VERSION "created by canmatrix"

NS_ :

BS_:

BU_: RadarFrontCenter DASy MPC3

BO_ 210 VFC_Object17A: 64 MPC3
 SG_ VFC_Obj17A_CRC : 0|16@1+ (1,0) [0|65535] ""  RadarFrontCenter,DASy
 SG_ VFC_Obj17A_DyStdDev : 104|10@1+ (0.02,0) [0|20] "m"  RadarFrontCenter,DASy
 SG_ VFC_Obj17A_DxStdDev : 118|10@1+ (0.05,0) [0|50] "m"  RadarFrontCenter,DASy
 SG_ VFC_Obj17A_VxStdDev : 128|10@1+ (0.1,0) [0|100] "m/s"  RadarFrontCenter,DASy
 SG_ VFC_Obj17A_ExistProb : 138|6@1+ (2,0) [0|100] "%"  RadarFrontCenter,DASy
 SG_ VFC_Obj17A_VyStdDev : 144|9@1+ (0.1,0) [0|50] "m/s"  RadarFrontCenter,DASy
 SG_ VFC_Obj17A_TypeProb : 154|6@1+ (2,0) [0|100] "%"  RadarFrontCenter,DASy
 SG_ VFC_Obj17A_AxStdDev : 160|8@1+ (0.1,0) [0|25] "m/s^2"  RadarFrontCenter,DASy
 SG_ VFC_Obj17A_AyStdDev : 168|8@1+ (0.1,0) [0|25] "m/s^2"  RadarFrontCenter,DASy
 SG_ VFC_Obj17A_AliveCtr : 16|8@1+ (1,0) [0|255] ""  RadarFrontCenter,DASy
 SG_ VFC_Obj17A_PhiLeft : 176|13@1+ (0.00025,-1) [-1|1] ""  RadarFrontCenter,DASy
 SG_ VFC_Obj17A_ClassifiedView : 189|3@1+ (1,0) [0|7] ""  RadarFrontCenter,DASy
 SG_ VFC_Obj17A_Length : 192|9@1+ (0.05,0) [0|25.5] "m"  RadarFrontCenter,DASy
 SG_ VFC_Obj17A_WidthStdDev : 201|7@1+ (0.01,0) [0|1] "m"  RadarFrontCenter,DASy
 SG_ VFC_Obj17A_Height : 208|9@1+ (0.01,0) [0|5.11] "m"  RadarFrontCenter,DASy
 SG_ VFC_Obj17A_HeightStdDev : 217|7@1+ (0.01,0) [0|1] "m"  RadarFrontCenter,DASy
 SG_ VFC_Obj17A_PhiLeftStdDev : 224|8@1+ (0.0002,0) [0|0.05] ""  RadarFrontCenter,DASy
 SG_ VFC_Obj17A_HeadingStdDev : 232|6@1+ (0.01,0) [0|0.5] "rad"  RadarFrontCenter,DASy
 SG_ VFC_Obj17A_Measured : 238|2@1+ (1,0) [0|3] ""  RadarFrontCenter,DASy
 SG_ VFC_Obj17A_Heading : 240|9@1+ (0.01,-1.57) [-1.57|1.57] "rad"  RadarFrontCenter,DASy
 SG_ VFC_Obj17A_LengthStdDev : 249|7@1+ (0.05,0) [0|5] "m"  RadarFrontCenter,DASy
 SG_ VFC_Obj17A_BlockCtr : 24|4@1+ (1,0) [0|15] ""  RadarFrontCenter,DASy
 SG_ VFC_Obj17A_PhiMid : 256|13@1+ (0.00025,-1) [-1|1] ""  RadarFrontCenter,DASy
 SG_ VFC_Obj17A_Width : 269|11@1+ (0.01,0) [0|12] "m"  RadarFrontCenter,DASy
 SG_ VFC_Obj17A_PhiMidStdDev : 280|8@1+ (0.0002,0) [0|0.05] ""  RadarFrontCenter,DASy
 SG_ VFC_Obj17A_PhiRight : 288|13@1+ (0.00025,-1) [-1|1] ""  RadarFrontCenter,DASy
 SG_ VFC_Obj17A_VisibleView : 301|3@1+ (1,0) [0|4] ""  RadarFrontCenter,DASy
 SG_ VFC_Obj17A_PhiRightStdDev : 304|8@1+ (0.0002,0) [0|0.05] ""  RadarFrontCenter,DASy
 SG_ VFC_Obj17A_PhiLeftVel : 312|13@1+ (0.001,-4) [-4|4] "1/s"  RadarFrontCenter,DASy
 SG_ VFC_Obj17A_PhiRightVel : 328|13@1+ (0.001,-4) [-4|4] "1/s"  RadarFrontCenter,DASy
 SG_ VFC_Obj17A_ProtOrderIndex : 32|6@1+ (1,0) [0|63] ""  RadarFrontCenter,DASy
 SG_ VFC_Obj17A_PhiRightVelStdDev : 344|8@1+ (0.001,0) [0|0.25] "1/s"  RadarFrontCenter,DASy
 SG_ VFC_Obj17A_PhiLeftVelStdDev : 352|8@1+ (0.001,0) [0|0.25] "1/s"  RadarFrontCenter,DASy
 SG_ VFC_Obj17A_PhiTop : 360|12@1+ (0.00025,-0.4) [-0.4|0.4] ""  RadarFrontCenter,DASy
 SG_ VFC_Obj17A_PhiBottom : 372|12@1+ (0.00025,-0.4) [-0.4|0.4] ""  RadarFrontCenter,DASy
 SG_ VFC_Obj17A_PhiTopStdDev : 384|8@1+ (0.0002,0) [0|0.05] ""  RadarFrontCenter,DASy
 SG_ VFC_Obj17A_HeadOrientation : 392|4@1+ (1,0) [0|10] ""  RadarFrontCenter,DASy
 SG_ VFC_Obj17A_Type : 396|4@1+ (1,0) [0|15] ""  RadarFrontCenter,DASy
 SG_ VFC_Obj17A_Ax : 39|9@1+ (0.1,-16) [-16|16] "m/s^2"  RadarFrontCenter,DASy
 SG_ VFC_Obj17A_PhiBottomStdDev : 400|8@1+ (0.0002,0) [0|0.05] ""  RadarFrontCenter,DASy
 SG_ VFC_Obj17A_NormVx : 408|16@1+ (0.001,-40) [-40|25] "1/s"  RadarFrontCenter,DASy
 SG_ VFC_Obj17A_NormAx : 424|13@1+ (0.002,-10) [-10|6] "1/s^2"  RadarFrontCenter,DASy
 SG_ VFC_Obj17A_NormAxStdDev : 440|10@1+ (0.0025,0) [0|2.5] "1/s^2"  RadarFrontCenter,DASy
 SG_ VFC_Obj17A_ProbMovingLat : 450|6@1+ (2,0) [0|100] "%"  RadarFrontCenter,DASy
 SG_ VFC_Obj17A_ID : 456|8@1+ (1,0) [0|254] ""  RadarFrontCenter,DASy
 SG_ VFC_Obj17A_NormVxStdDev : 464|10@1+ (0.001,0) [0|1] "1/s"  RadarFrontCenter,DASy
 SG_ VFC_Obj17A_ProbMovingLong : 474|6@1+ (2,0) [0|100] "%"  RadarFrontCenter,DASy
 SG_ VFC_Obj17A_Vx : 48|12@1+ (0.1,-154) [-154|50] "m/s"  RadarFrontCenter,DASy
 SG_ VFC_Obj17A_Dx : 60|12@1+ (0.05,0) [0|204.7] "m"  RadarFrontCenter,DASy
 SG_ VFC_Obj17A_Dy : 72|14@1+ (0.01,-80) [-80|80] "m"  RadarFrontCenter,DASy
 SG_ VFC_Obj17A_Vy : 86|10@1+ (0.1,-50) [-50|50] "m/s"  RadarFrontCenter,DASy
 SG_ VFC_Obj17A_Ay : 96|8@1+ (0.1,-12) [-12|12] "m/s^2"  RadarFrontCenter,DASy

BO_ 211 VFC_Object17B: 16 MPC3
 SG_ VFC_Obj17B_CRC : 0|16@1+ (1,0) [0|65535] ""  RadarFrontCenter,DASy
 SG_ VFC_Obj17B_TTIPC : 104|11@1+ (0.008,-8) [-8|8] ""  RadarFrontCenter,DASy
 SG_ VFC_Obj17B_TTIPC_StdDev : 120|7@1+ (0.0625,0) [0|7.875] ""  RadarFrontCenter,DASy
 SG_ VFC_Obj17B_AliveCtr : 16|8@1+ (1,0) [0|255] ""  RadarFrontCenter,DASy
 SG_ VFC_Obj17B_BlockCtr : 24|4@1+ (1,0) [0|15] ""  RadarFrontCenter,DASy
 SG_ VFC_Obj17B_ScaleChange : 32|14@1+ (0.0001,0.5) [0.5|2.1] ""  RadarFrontCenter,DASy
 SG_ VFC_Obj17B_ScaleChngStdDev : 48|10@1+ (0.0001,0) [0|0.1] ""  RadarFrontCenter,DASy
 SG_ VFC_Obj17B_LineEdgeRightEgo : 58|1@1+ (1,0) [0|1] ""  RadarFrontCenter,DASy
 SG_ VFC_Obj17B_LineEdgeLeftEgo : 59|1@1+ (1,0) [0|1] ""  RadarFrontCenter,DASy
 SG_ VFC_Obj17B_CompletelyInImg : 60|1@1+ (1,0) [0|1] ""  RadarFrontCenter,DASy
 SG_ VFC_Obj17B_DirIndicator : 61|3@1+ (1,0) [0|7] ""  RadarFrontCenter,DASy
 SG_ VFC_Obj17B_LineEdgeAngle : 64|13@1+ (0.00025,-1) [-1|1] "rad"  RadarFrontCenter,DASy
 SG_ VFC_Obj17B_BrakeLight : 77|3@1+ (1,0) [0|7] ""  RadarFrontCenter,DASy
 SG_ VFC_Obj17B_MeasSource : 80|5@1+ (1,0) [0|31] ""  RadarFrontCenter,DASy
 SG_ VFC_Obj17B_AngLongitude : 88|10@1+ (0.005,-2.5) [-2.5|2.5] "rad/s"  RadarFrontCenter,DASy
 SG_ VFC_Obj17B_Reliab : 98|6@1+ (1,0) [0|63] ""  RadarFrontCenter,DASy

BO_ 212 VFC_Object18A: 64 MPC3
 SG_ VFC_Obj18A_CRC : 0|16@1+ (1,0) [0|65535] ""  RadarFrontCenter,DASy
 SG_ VFC_Obj18A_DyStdDev : 104|10@1+ (0.02,0) [0|20] "m"  RadarFrontCenter,DASy
 SG_ VFC_Obj18A_DxStdDev : 118|10@1+ (0.05,0) [0|50] "m"  RadarFrontCenter,DASy
 SG_ VFC_Obj18A_VxStdDev : 128|10@1+ (0.1,0) [0|100] "m/s"  RadarFrontCenter,DASy
 SG_ VFC_Obj18A_ExistProb : 138|6@1+ (2,0) [0|100] "%"  RadarFrontCenter,DASy
 SG_ VFC_Obj18A_VyStdDev : 144|9@1+ (0.1,0) [0|50] "m/s"  RadarFrontCenter,DASy
 SG_ VFC_Obj18A_TypeProb : 154|6@1+ (2,0) [0|100] "%"  RadarFrontCenter,DASy
 SG_ VFC_Obj18A_AxStdDev : 160|8@1+ (0.1,0) [0|25] "m/s^2"  RadarFrontCenter,DASy
 SG_ VFC_Obj18A_AyStdDev : 168|8@1+ (0.1,0) [0|25] "m/s^2"  RadarFrontCenter,DASy
 SG_ VFC_Obj18A_AliveCtr : 16|8@1+ (1,0) [0|255] ""  RadarFrontCenter,DASy
 SG_ VFC_Obj18A_PhiLeft : 176|13@1+ (0.00025,-1) [-1|1] ""  RadarFrontCenter,DASy
 SG_ VFC_Obj18A_ClassifiedView : 189|3@1+ (1,0) [0|7] ""  RadarFrontCenter,DASy
 SG_ VFC_Obj18A_Length : 192|9@1+ (0.05,0) [0|25.5] "m"  RadarFrontCenter,DASy
 SG_ VFC_Obj18A_WidthStdDev : 201|7@1+ (0.01,0) [0|1] "m"  RadarFrontCenter,DASy
 SG_ VFC_Obj18A_Height : 208|9@1+ (0.01,0) [0|5.11] "m"  RadarFrontCenter,DASy
 SG_ VFC_Obj18A_HeightStdDev : 217|7@1+ (0.01,0) [0|1] "m"  RadarFrontCenter,DASy
 SG_ VFC_Obj18A_PhiLeftStdDev : 224|8@1+ (0.0002,0) [0|0.05] ""  RadarFrontCenter,DASy
 SG_ VFC_Obj18A_HeadingStdDev : 232|6@1+ (0.01,0) [0|0.5] "rad"  RadarFrontCenter,DASy
 SG_ VFC_Obj18A_Measured : 238|2@1+ (1,0) [0|3] ""  RadarFrontCenter,DASy
 SG_ VFC_Obj18A_Heading : 240|9@1+ (0.01,-1.57) [-1.57|1.57] "rad"  RadarFrontCenter,DASy
 SG_ VFC_Obj18A_LengthStdDev : 249|7@1+ (0.05,0) [0|5] "m"  RadarFrontCenter,DASy
 SG_ VFC_Obj18A_BlockCtr : 24|4@1+ (1,0) [0|15] ""  RadarFrontCenter,DASy
 SG_ VFC_Obj18A_PhiMid : 256|13@1+ (0.00025,-1) [-1|1] ""  RadarFrontCenter,DASy
 SG_ VFC_Obj18A_Width : 269|11@1+ (0.01,0) [0|12] "m"  RadarFrontCenter,DASy
 SG_ VFC_Obj18A_PhiMidStdDev : 280|8@1+ (0.0002,0) [0|0.05] ""  RadarFrontCenter,DASy
 SG_ VFC_Obj18A_PhiRight : 288|13@1+ (0.00025,-1) [-1|1] ""  RadarFrontCenter,DASy
 SG_ VFC_Obj18A_VisibleView : 301|3@1+ (1,0) [0|4] ""  RadarFrontCenter,DASy
 SG_ VFC_Obj18A_PhiRightStdDev : 304|8@1+ (0.0002,0) [0|0.05] ""  RadarFrontCenter,DASy
 SG_ VFC_Obj18A_PhiLeftVel : 312|13@1+ (0.001,-4) [-4|4] "1/s"  RadarFrontCenter,DASy
 SG_ VFC_Obj18A_PhiRightVel : 328|13@1+ (0.001,-4) [-4|4] "1/s"  RadarFrontCenter,DASy
 SG_ VFC_Obj18A_ProtOrderIndex : 32|6@1+ (1,0) [0|63] ""  RadarFrontCenter,DASy
 SG_ VFC_Obj18A_PhiRightVelStdDev : 344|8@1+ (0.001,0) [0|0.25] "1/s"  RadarFrontCenter,DASy
 SG_ VFC_Obj18A_PhiLeftVelStdDev : 352|8@1+ (0.001,0) [0|0.25] "1/s"  RadarFrontCenter,DASy
 SG_ VFC_Obj18A_PhiTop : 360|12@1+ (0.00025,-0.4) [-0.4|0.4] ""  RadarFrontCenter,DASy
 SG_ VFC_Obj18A_PhiBottom : 372|12@1+ (0.00025,-0.4) [-0.4|0.4] ""  RadarFrontCenter,DASy
 SG_ VFC_Obj18A_PhiTopStdDev : 384|8@1+ (0.0002,0) [0|0.05] ""  RadarFrontCenter,DASy
 SG_ VFC_Obj18A_HeadOrientation : 392|4@1+ (1,0) [0|10] ""  RadarFrontCenter,DASy
 SG_ VFC_Obj18A_Type : 396|4@1+ (1,0) [0|15] ""  RadarFrontCenter,DASy
 SG_ VFC_Obj18A_Ax : 39|9@1+ (0.1,-16) [-16|16] "m/s^2"  RadarFrontCenter,DASy
 SG_ VFC_Obj18A_PhiBottomStdDev : 400|8@1+ (0.0002,0) [0|0.05] ""  RadarFrontCenter,DASy
 SG_ VFC_Obj18A_NormVx : 408|16@1+ (0.001,-40) [-40|25] "1/s"  RadarFrontCenter,DASy
 SG_ VFC_Obj18A_NormAx : 424|13@1+ (0.002,-10) [-10|6] "1/s^2"  RadarFrontCenter,DASy
 SG_ VFC_Obj18A_NormAxStdDev : 440|10@1+ (0.0025,0) [0|2.5] "1/s^2"  RadarFrontCenter,DASy
 SG_ VFC_Obj18A_ProbMovingLat : 450|6@1+ (2,0) [0|100] "%"  RadarFrontCenter,DASy
 SG_ VFC_Obj18A_ID : 456|8@1+ (1,0) [0|254] ""  RadarFrontCenter,DASy
 SG_ VFC_Obj18A_NormVxStdDev : 464|10@1+ (0.001,0) [0|1] "1/s"  RadarFrontCenter,DASy
 SG_ VFC_Obj18A_ProbMovingLong : 474|6@1+ (2,0) [0|100] "%"  RadarFrontCenter,DASy
 SG_ VFC_Obj18A_Vx : 48|12@1+ (0.1,-154) [-154|50] "m/s"  RadarFrontCenter,DASy
 SG_ VFC_Obj18A_Dx : 60|12@1+ (0.05,0) [0|204.7] "m"  RadarFrontCenter,DASy
 SG_ VFC_Obj18A_Dy : 72|14@1+ (0.01,-80) [-80|80] "m"  RadarFrontCenter,DASy
 SG_ VFC_Obj18A_Vy : 86|10@1+ (0.1,-50) [-50|50] "m/s"  RadarFrontCenter,DASy
 SG_ VFC_Obj18A_Ay : 96|8@1+ (0.1,-12) [-12|12] "m/s^2"  RadarFrontCenter,DASy

BO_ 213 VFC_Object18B: 16 MPC3
 SG_ VFC_Obj18B_CRC : 0|16@1+ (1,0) [0|65535] ""  RadarFrontCenter,DASy
 SG_ VFC_Obj18B_TTIPC : 104|11@1+ (0.008,-8) [-8|8] ""  RadarFrontCenter,DASy
 SG_ VFC_Obj18B_TTIPC_StdDev : 120|7@1+ (0.0625,0) [0|7.875] ""  RadarFrontCenter,DASy
 SG_ VFC_Obj18B_AliveCtr : 16|8@1+ (1,0) [0|255] ""  RadarFrontCenter,DASy
 SG_ VFC_Obj18B_BlockCtr : 24|4@1+ (1,0) [0|15] ""  RadarFrontCenter,DASy
 SG_ VFC_Obj18B_ScaleChange : 32|14@1+ (0.0001,0.5) [0.5|2.1] ""  RadarFrontCenter,DASy
 SG_ VFC_Obj18B_ScaleChngStdDev : 48|10@1+ (0.0001,0) [0|0.1] ""  RadarFrontCenter,DASy
 SG_ VFC_Obj18B_LineEdgeRightEgo : 58|1@1+ (1,0) [0|1] ""  RadarFrontCenter,DASy
 SG_ VFC_Obj18B_LineEdgeLeftEgo : 59|1@1+ (1,0) [0|1] ""  RadarFrontCenter,DASy
 SG_ VFC_Obj18B_CompletelyInImg : 60|1@1+ (1,0) [0|1] ""  RadarFrontCenter,DASy
 SG_ VFC_Obj18B_DirIndicator : 61|3@1+ (1,0) [0|7] ""  RadarFrontCenter,DASy
 SG_ VFC_Obj18B_LineEdgeAngle : 64|13@1+ (0.00025,-1) [-1|1] "rad"  RadarFrontCenter,DASy
 SG_ VFC_Obj18B_BrakeLight : 77|3@1+ (1,0) [0|7] ""  RadarFrontCenter,DASy
 SG_ VFC_Obj18B_MeasSource : 80|5@1+ (1,0) [0|31] ""  RadarFrontCenter,DASy
 SG_ VFC_Obj18B_AngLongitude : 88|10@1+ (0.005,-2.5) [-2.5|2.5] "rad/s"  RadarFrontCenter,DASy
 SG_ VFC_Obj18B_Reliab : 98|6@1+ (1,0) [0|63] ""  RadarFrontCenter,DASy

BO_ 214 VFC_Object19A: 64 MPC3
 SG_ VFC_Obj19A_CRC : 0|16@1+ (1,0) [0|65535] ""  RadarFrontCenter,DASy
 SG_ VFC_Obj19A_DyStdDev : 104|10@1+ (0.02,0) [0|20] "m"  RadarFrontCenter,DASy
 SG_ VFC_Obj19A_DxStdDev : 118|10@1+ (0.05,0) [0|50] "m"  RadarFrontCenter,DASy
 SG_ VFC_Obj19A_VxStdDev : 128|10@1+ (0.1,0) [0|100] "m/s"  RadarFrontCenter,DASy
 SG_ VFC_Obj19A_ExistProb : 138|6@1+ (2,0) [0|100] "%"  RadarFrontCenter,DASy
 SG_ VFC_Obj19A_VyStdDev : 144|9@1+ (0.1,0) [0|50] "m/s"  RadarFrontCenter,DASy
 SG_ VFC_Obj19A_TypeProb : 154|6@1+ (2,0) [0|100] "%"  RadarFrontCenter,DASy
 SG_ VFC_Obj19A_AxStdDev : 160|8@1+ (0.1,0) [0|25] "m/s^2"  RadarFrontCenter,DASy
 SG_ VFC_Obj19A_AyStdDev : 168|8@1+ (0.1,0) [0|25] "m/s^2"  RadarFrontCenter,DASy
 SG_ VFC_Obj19A_AliveCtr : 16|8@1+ (1,0) [0|255] ""  RadarFrontCenter,DASy
 SG_ VFC_Obj19A_PhiLeft : 176|13@1+ (0.00025,-1) [-1|1] ""  RadarFrontCenter,DASy
 SG_ VFC_Obj19A_ClassifiedView : 189|3@1+ (1,0) [0|7] ""  RadarFrontCenter,DASy
 SG_ VFC_Obj19A_Length : 192|9@1+ (0.05,0) [0|25.5] "m"  RadarFrontCenter,DASy
 SG_ VFC_Obj19A_WidthStdDev : 201|7@1+ (0.01,0) [0|1] "m"  RadarFrontCenter,DASy
 SG_ VFC_Obj19A_Height : 208|9@1+ (0.01,0) [0|5.11] "m"  RadarFrontCenter,DASy
 SG_ VFC_Obj19A_HeightStdDev : 217|7@1+ (0.01,0) [0|1] "m"  RadarFrontCenter,DASy
 SG_ VFC_Obj19A_PhiLeftStdDev : 224|8@1+ (0.0002,0) [0|0.05] ""  RadarFrontCenter,DASy
 SG_ VFC_Obj19A_HeadingStdDev : 232|6@1+ (0.01,0) [0|0.5] "rad"  RadarFrontCenter,DASy
 SG_ VFC_Obj19A_Measured : 238|2@1+ (1,0) [0|3] ""  RadarFrontCenter,DASy
 SG_ VFC_Obj19A_Heading : 240|9@1+ (0.01,-1.57) [-1.57|1.57] "rad"  RadarFrontCenter,DASy
 SG_ VFC_Obj19A_LengthStdDev : 249|7@1+ (0.05,0) [0|5] "m"  RadarFrontCenter,DASy
 SG_ VFC_Obj19A_BlockCtr : 24|4@1+ (1,0) [0|15] ""  RadarFrontCenter,DASy
 SG_ VFC_Obj19A_PhiMid : 256|13@1+ (0.00025,-1) [-1|1] ""  RadarFrontCenter,DASy
 SG_ VFC_Obj19A_Width : 269|11@1+ (0.01,0) [0|12] "m"  RadarFrontCenter,DASy
 SG_ VFC_Obj19A_PhiMidStdDev : 280|8@1+ (0.0002,0) [0|0.05] ""  RadarFrontCenter,DASy
 SG_ VFC_Obj19A_PhiRight : 288|13@1+ (0.00025,-1) [-1|1] ""  RadarFrontCenter,DASy
 SG_ VFC_Obj19A_VisibleView : 301|3@1+ (1,0) [0|4] ""  RadarFrontCenter,DASy
 SG_ VFC_Obj19A_PhiRightStdDev : 304|8@1+ (0.0002,0) [0|0.05] ""  RadarFrontCenter,DASy
 SG_ VFC_Obj19A_PhiLeftVel : 312|13@1+ (0.001,-4) [-4|4] "1/s"  RadarFrontCenter,DASy
 SG_ VFC_Obj19A_PhiRightVel : 328|13@1+ (0.001,-4) [-4|4] "1/s"  RadarFrontCenter,DASy
 SG_ VFC_Obj19A_ProtOrderIndex : 32|6@1+ (1,0) [0|63] ""  RadarFrontCenter,DASy
 SG_ VFC_Obj19A_PhiRightVelStdDev : 344|8@1+ (0.001,0) [0|0.25] "1/s"  RadarFrontCenter,DASy
 SG_ VFC_Obj19A_PhiLeftVelStdDev : 352|8@1+ (0.001,0) [0|0.25] "1/s"  RadarFrontCenter,DASy
 SG_ VFC_Obj19A_PhiTop : 360|12@1+ (0.00025,-0.4) [-0.4|0.4] ""  RadarFrontCenter,DASy
 SG_ VFC_Obj19A_PhiBottom : 372|12@1+ (0.00025,-0.4) [-0.4|0.4] ""  RadarFrontCenter,DASy
 SG_ VFC_Obj19A_PhiTopStdDev : 384|8@1+ (0.0002,0) [0|0.05] ""  RadarFrontCenter,DASy
 SG_ VFC_Obj19A_HeadOrientation : 392|4@1+ (1,0) [0|10] ""  RadarFrontCenter,DASy
 SG_ VFC_Obj19A_Type : 396|4@1+ (1,0) [0|15] ""  RadarFrontCenter,DASy
 SG_ VFC_Obj19A_Ax : 39|9@1+ (0.1,-16) [-16|16] "m/s^2"  RadarFrontCenter,DASy
 SG_ VFC_Obj19A_PhiBottomStdDev : 400|8@1+ (0.0002,0) [0|0.05] ""  RadarFrontCenter,DASy
 SG_ VFC_Obj19A_NormVx : 408|16@1+ (0.001,-40) [-40|25] "1/s"  RadarFrontCenter,DASy
 SG_ VFC_Obj19A_NormAx : 424|13@1+ (0.002,-10) [-10|6] "1/s^2"  RadarFrontCenter,DASy
 SG_ VFC_Obj19A_NormAxStdDev : 440|10@1+ (0.0025,0) [0|2.5] "1/s^2"  RadarFrontCenter,DASy
 SG_ VFC_Obj19A_ProbMovingLat : 450|6@1+ (2,0) [0|100] "%"  RadarFrontCenter,DASy
 SG_ VFC_Obj19A_ID : 456|8@1+ (1,0) [0|254] ""  RadarFrontCenter,DASy
 SG_ VFC_Obj19A_NormVxStdDev : 464|10@1+ (0.001,0) [0|1] "1/s"  RadarFrontCenter,DASy
 SG_ VFC_Obj19A_ProbMovingLong : 474|6@1+ (2,0) [0|100] "%"  RadarFrontCenter,DASy
 SG_ VFC_Obj19A_Vx : 48|12@1+ (0.1,-154) [-154|50] "m/s"  RadarFrontCenter,DASy
 SG_ VFC_Obj19A_Dx : 60|12@1+ (0.05,0) [0|204.7] "m"  RadarFrontCenter,DASy
 SG_ VFC_Obj19A_Dy : 72|14@1+ (0.01,-80) [-80|80] "m"  RadarFrontCenter,DASy
 SG_ VFC_Obj19A_Vy : 86|10@1+ (0.1,-50) [-50|50] "m/s"  RadarFrontCenter,DASy
 SG_ VFC_Obj19A_Ay : 96|8@1+ (0.1,-12) [-12|12] "m/s^2"  RadarFrontCenter,DASy

BO_ 215 VFC_Object19B: 16 MPC3
 SG_ VFC_Obj19B_CRC : 0|16@1+ (1,0) [0|65535] ""  RadarFrontCenter,DASy
 SG_ VFC_Obj19B_TTIPC : 104|11@1+ (0.008,-8) [-8|8] ""  RadarFrontCenter,DASy
 SG_ VFC_Obj19B_TTIPC_StdDev : 120|7@1+ (0.0625,0) [0|7.875] ""  RadarFrontCenter,DASy
 SG_ VFC_Obj19B_AliveCtr : 16|8@1+ (1,0) [0|255] ""  RadarFrontCenter,DASy
 SG_ VFC_Obj19B_BlockCtr : 24|4@1+ (1,0) [0|15] ""  RadarFrontCenter,DASy
 SG_ VFC_Obj19B_ScaleChange : 32|14@1+ (0.0001,0.5) [0.5|2.1] ""  RadarFrontCenter,DASy
 SG_ VFC_Obj19B_ScaleChngStdDev : 48|10@1+ (0.0001,0) [0|0.1] ""  RadarFrontCenter,DASy
 SG_ VFC_Obj19B_LineEdgeRightEgo : 58|1@1+ (1,0) [0|1] ""  RadarFrontCenter,DASy
 SG_ VFC_Obj19B_LineEdgeLeftEgo : 59|1@1+ (1,0) [0|1] ""  RadarFrontCenter,DASy
 SG_ VFC_Obj19B_CompletelyInImg : 60|1@1+ (1,0) [0|1] ""  RadarFrontCenter,DASy
 SG_ VFC_Obj19B_DirIndicator : 61|3@1+ (1,0) [0|7] ""  RadarFrontCenter,DASy
 SG_ VFC_Obj19B_LineEdgeAngle : 64|13@1+ (0.00025,-1) [-1|1] "rad"  RadarFrontCenter,DASy
 SG_ VFC_Obj19B_BrakeLight : 77|3@1+ (1,0) [0|7] ""  RadarFrontCenter,DASy
 SG_ VFC_Obj19B_MeasSource : 80|5@1+ (1,0) [0|31] ""  RadarFrontCenter,DASy
 SG_ VFC_Obj19B_AngLongitude : 88|10@1+ (0.005,-2.5) [-2.5|2.5] "rad/s"  RadarFrontCenter,DASy
 SG_ VFC_Obj19B_Reliab : 98|6@1+ (1,0) [0|63] ""  RadarFrontCenter,DASy

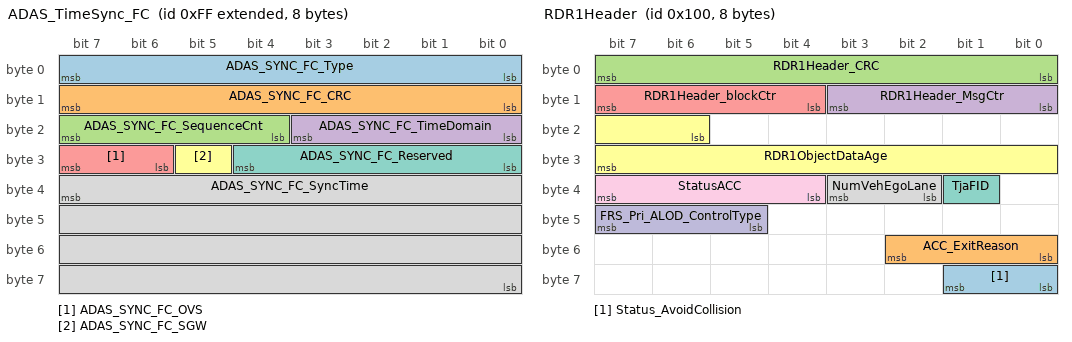
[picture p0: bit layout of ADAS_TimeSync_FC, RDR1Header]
BO_ 2147483903 ADAS_TimeSync_FC: 8 DASy
 SG_ ADAS_SYNC_FC_Type : 7|8@0+ (1,0) [0|255] ""  RadarFrontCenter,MPC3
 SG_ ADAS_SYNC_FC_CRC : 15|8@0+ (1,0) [0|0] ""  RadarFrontCenter,MPC3
 SG_ ADAS_SYNC_FC_SequenceCnt : 23|4@0+ (1,0) [0|15] ""  RadarFrontCenter,MPC3
 SG_ ADAS_SYNC_FC_TimeDomain : 19|4@0+ (1,0) [0|15] ""  RadarFrontCenter,MPC3
 SG_ ADAS_SYNC_FC_OVS : 31|2@0+ (1,0) [0|3] ""  RadarFrontCenter,MPC3
 SG_ ADAS_SYNC_FC_SGW : 29|1@0+ (1,0) [0|1] ""  RadarFrontCenter,MPC3
 SG_ ADAS_SYNC_FC_Reserved : 28|5@0+ (1,0) [0|31] ""  RadarFrontCenter,MPC3
 SG_ ADAS_SYNC_FC_SyncTime : 39|32@0+ (1,0) [0|4294967295] ""  RadarFrontCenter,MPC3

BO_ 256 RDR1Header: 8 RadarFrontCenter
 SG_ Status_AvoidCollision : 56|2@1+ (1,0) [0|3] ""  MPC3
 SG_ ACC_ExitReason : 48|3@1+ (1,0) [0|7] ""  MPC3
 SG_ RDR1Header_CRC : 0|8@1+ (1,0) [0|255] ""  MPC3
 SG_ RDR1Header_MsgCtr : 8|4@1+ (1,0) [0|15] ""  MPC3
 SG_ RDR1Header_blockCtr : 12|4@1+ (1,0) [0|15] ""  MPC3
 SG_ RDR1ObjectDataAge : 22|10@1+ (0.000976562,0) [0|0.998046875] "seconds"  MPC3
 SG_ TjaFID : 33|1@1+ (1,0) [0|1] ""  MPC3
 SG_ NumVehEgoLane : 34|2@1+ (1,0) [0|3] ""  MPC3
 SG_ StatusACC : 36|4@1+ (1,0) [0|15] ""  MPC3
 SG_ FRS_Pri_ALOD_ControlType : 45|3@1+ (1,0) [0|7] ""  MPC3

BO_ 273 TIPLCourseInfo0: 16 RadarFrontCenter
 SG_ TIPLCourseInfo0_CRC : 0|8@1+ (1,0) [0|255] ""  MPC3
 SG_ TIPLCourseInfo0_MsgCtr : 8|4@1+ (1,0) [0|15] ""  MPC3
 SG_ TIPLCourseInfo0_blockCtr : 12|4@1+ (1,0) [0|15] ""  MPC3
 SG_ TIPLCourseInfo0_a0polynomCoef_sw : 16|16@1- (0.0078125,0) [-256|255.9921875] ""  MPC3
 SG_ TIPLCourseInfo0_a1polynomCoef_sw : 32|16@1- (0.000244140625,0) [-8|7.999755859375] ""  MPC3
 SG_ TIPLCourseInfo0_a2polynomCoef_sw : 48|16@1- (1.9073486328125E-006,0) [-0.0625|0.0624980926513672] ""  MPC3
 SG_ TIPLCourseInfo0_dLowerLimit_sw : 64|16@1- (0.0078125,0) [-256|255.9921875] "m"  MPC3
 SG_ TIPLCourseInfo0_dUpperLimit_sw : 80|16@1- (0.0078125,0) [-256|255.9921875] "m"  MPC3
 SG_ TIPLCourseInfo0_qCourseConform : 96|8@1+ (0.00390625,0) [0|0.99609375] ""  MPC3

BO_ 274 TIPLCourseInfo1: 16 RadarFrontCenter
 SG_ TIPLCourseInfo1_CRC : 0|8@1+ (1,0) [0|255] ""  MPC3
 SG_ TIPLCourseInfo1_MsgCtr : 8|4@1+ (1,0) [0|15] ""  MPC3
 SG_ TIPLCourseInfo1_blockCtr : 12|4@1+ (1,0) [0|15] ""  MPC3
 SG_ TIPLCourseInfo1_a0polynomCoef_sw : 16|16@1- (0.0078125,0) [-256|255.9921875] ""  MPC3
 SG_ TIPLCourseInfo1_a1polynomCoef_sw : 32|16@1- (0.000244140625,0) [-8|7.999755859375] ""  MPC3
 SG_ TIPLCourseInfo1_a2polynomCoef_sw : 48|16@1- (1.9073486328125E-006,0) [-0.0625|0.0624980926513672] ""  MPC3
 SG_ TIPLCourseInfo1_dLowerLimit_sw : 64|16@1- (0.0078125,0) [-256|255.9921875] "m"  MPC3
 SG_ TIPLCourseInfo1_dUpperLimit_sw : 80|16@1- (0.0078125,0) [-256|255.9921875] "m"  MPC3
 SG_ TIPLCourseInfo1_qCourseConform : 96|8@1+ (0.00390625,0) [0|0.99609375] ""  MPC3

BO_ 275 TIPLCourseInfo2: 16 RadarFrontCenter
 SG_ TIPLCourseInfo2_CRC : 0|8@1+ (1,0) [0|255] ""  MPC3
 SG_ TIPLCourseInfo2_MsgCtr : 8|4@1+ (1,0) [0|15] ""  MPC3
 SG_ TIPLCourseInfo2_blockCtr : 12|4@1+ (1,0) [0|15] ""  MPC3
 SG_ TIPLCourseInfo2_a0polynomCoef_sw : 16|16@1- (0.0078125,0) [-256|255.9921875] ""  MPC3
 SG_ TIPLCourseInfo2_a1polynomCoef_sw : 32|16@1- (0.000244140625,0) [-8|7.999755859375] ""  MPC3
 SG_ TIPLCourseInfo2_a2polynomCoef_sw : 48|16@1- (1.9073486328125E-006,0) [-0.0625|0.0624980926513672] ""  MPC3
 SG_ TIPLCourseInfo2_dLowerLimit_sw : 64|16@1- (0.0078125,0) [-256|255.9921875] "m"  MPC3
 SG_ TIPLCourseInfo2_dUpperLimit_sw : 80|16@1- (0.0078125,0) [-256|255.9921875] "m"  MPC3
 SG_ TIPLCourseInfo2_qCourseConform : 96|8@1+ (0.00390625,0) [0|0.99609375] ""  MPC3

BO_ 276 TIPLCourseInfo3: 16 RadarFrontCenter
 SG_ TIPLCourseInfo3_CRC : 0|8@1+ (1,0) [0|255] ""  MPC3
 SG_ TIPLCourseInfo3_MsgCtr : 8|4@1+ (1,0) [0|15] ""  MPC3
 SG_ TIPLCourseInfo3_blockCtr : 12|4@1+ (1,0) [0|15] ""  MPC3
 SG_ TIPLCourseInfo3_a0polynomCoef_sw : 16|16@1- (0.0078125,0) [-256|255.9921875] ""  MPC3
 SG_ TIPLCourseInfo3_a1polynomCoef_sw : 32|16@1- (0.000244140625,0) [-8|7.999755859375] ""  MPC3
 SG_ TIPLCourseInfo3_a2polynomCoef_sw : 48|16@1- (1.9073486328125E-006,0) [-0.0625|0.0624980926513672] ""  MPC3
 SG_ TIPLCourseInfo3_dLowerLimit_sw : 64|16@1- (0.0078125,0) [-256|255.9921875] "m"  MPC3
 SG_ TIPLCourseInfo3_dUpperLimit_sw : 80|16@1- (0.0078125,0) [-256|255.9921875] "m"  MPC3
 SG_ TIPLCourseInfo3_qCourseConform : 96|8@1+ (0.00390625,0) [0|0.99609375] ""  MPC3

BO_ 277 TIPLCourseInfo4: 16 RadarFrontCenter
 SG_ TIPLCourseInfo4_CRC : 0|8@1+ (1,0) [0|255] ""  MPC3
 SG_ TIPLCourseInfo4_MsgCtr : 8|4@1+ (1,0) [0|15] ""  MPC3
 SG_ TIPLCourseInfo4_blockCtr : 12|4@1+ (1,0) [0|15] ""  MPC3
 SG_ TIPLCourseInfo4_a0polynomCoef_sw : 16|16@1- (0.0078125,0) [-256|255.9921875] ""  MPC3
 SG_ TIPLCourseInfo4_a1polynomCoef_sw : 32|16@1- (0.000244140625,0) [-8|7.999755859375] ""  MPC3
 SG_ TIPLCourseInfo4_a2polynomCoef_sw : 48|16@1- (1.9073486328125E-006,0) [-0.0625|0.0624980926513672] ""  MPC3
 SG_ TIPLCourseInfo4_dLowerLimit_sw : 64|16@1- (0.0078125,0) [-256|255.9921875] "m"  MPC3
 SG_ TIPLCourseInfo4_dUpperLimit_sw : 80|16@1- (0.0078125,0) [-256|255.9921875] "m"  MPC3
 SG_ TIPLCourseInfo4_qCourseConform : 96|8@1+ (0.00390625,0) [0|0.99609375] ""  MPC3

BO_ 278 TIPLLaneInfo0: 12 RadarFrontCenter
 SG_ TIPLLaneInfo0_CRC : 0|8@1+ (1,0) [0|255] ""  MPC3
 SG_ TIPLLaneInfo0_MsgCtr : 8|4@1+ (1,0) [0|15] ""  MPC3
 SG_ TIPLLaneInfo0_blockCtr : 12|4@1+ (1,0) [0|15] ""  MPC3
 SG_ TIPLLaneInfo0_dLeftBorder_sw : 16|16@1- (0.0078125,0) [-256|255.9921875] "m"  MPC3
 SG_ TIPLLaneInfo0_dLowerLimitLane_sw : 32|16@1- (0.0078125,0) [-256|255.9921875] "m"  MPC3
 SG_ TIPLLaneInfo0_dRightBorder_sw : 48|16@1- (0.0078125,0) [-256|255.9921875] "m"  MPC3
 SG_ TIPLLaneInfo0_dUpperLimitLane_sw : 64|16@1- (0.0078125,0) [-256|255.9921875] "m"  MPC3
 SG_ TIPLLaneInfo0_prob1Lane_ub : 80|8@1+ (0.0078125,0) [0|1.9921875] ""  MPC3

BO_ 279 TIPLLaneInfo1: 12 RadarFrontCenter
 SG_ TIPLLaneInfo1_CRC : 0|8@1+ (1,0) [0|255] ""  MPC3
 SG_ TIPLLaneInfo1_MsgCtr : 8|4@1+ (1,0) [0|15] ""  MPC3
 SG_ TIPLLaneInfo1_blockCtr : 12|4@1+ (1,0) [0|15] ""  MPC3
 SG_ TIPLLaneInfo1_dLeftBorder_sw : 16|16@1- (0.0078125,0) [-256|255.9921875] "m"  MPC3
 SG_ TIPLLaneInfo1_dLowerLimitLane_sw : 32|16@1- (0.0078125,0) [-256|255.9921875] "m"  MPC3
 SG_ TIPLLaneInfo1_dRightBorder_sw : 48|16@1- (0.0078125,0) [-256|255.9921875] "m"  MPC3
 SG_ TIPLLaneInfo1_dUpperLimitLane_sw : 64|16@1- (0.0078125,0) [-256|255.9921875] "m"  MPC3
 SG_ TIPLLaneInfo1_prob1Lane_ub : 80|8@1+ (0.0078125,0) [0|1.9921875] ""  MPC3

BO_ 280 TIPLLaneInfo2: 12 RadarFrontCenter
 SG_ TIPLLaneInfo2_CRC : 0|8@1+ (1,0) [0|255] ""  MPC3
 SG_ TIPLLaneInfo2_MsgCtr : 8|4@1+ (1,0) [0|15] ""  MPC3
 SG_ TIPLLaneInfo2_blockCtr : 12|4@1+ (1,0) [0|15] ""  MPC3
 SG_ TIPLLaneInfo2_dLeftBorder_sw : 16|16@1- (0.0078125,0) [-256|255.9921875] "m"  MPC3
 SG_ TIPLLaneInfo2_dLowerLimitLane_sw : 32|16@1- (0.0078125,0) [-256|255.9921875] "m"  MPC3
 SG_ TIPLLaneInfo2_dRightBorder_sw : 48|16@1- (0.0078125,0) [-256|255.9921875] "m"  MPC3
 SG_ TIPLLaneInfo2_dUpperLimitLane_sw : 64|16@1- (0.0078125,0) [-256|255.9921875] "m"  MPC3
 SG_ TIPLLaneInfo2_prob1Lane_ub : 80|8@1+ (0.0078125,0) [0|1.9921875] ""  MPC3

BO_ 281 TIPLLaneInfo3: 12 RadarFrontCenter
 SG_ TIPLLaneInfo3_CRC : 0|8@1+ (1,0) [0|255] ""  MPC3
 SG_ TIPLLaneInfo3_MsgCtr : 8|4@1+ (1,0) [0|15] ""  MPC3
 SG_ TIPLLaneInfo3_blockCtr : 12|4@1+ (1,0) [0|15] ""  MPC3
 SG_ TIPLLaneInfo3_dLeftBorder_sw : 16|16@1- (0.0078125,0) [-256|255.9921875] "m"  MPC3
 SG_ TIPLLaneInfo3_dLowerLimitLane_sw : 32|16@1- (0.0078125,0) [-256|255.9921875] "m"  MPC3
 SG_ TIPLLaneInfo3_dRightBorder_sw : 48|16@1- (0.0078125,0) [-256|255.9921875] "m"  MPC3
 SG_ TIPLLaneInfo3_dUpperLimitLane_sw : 64|16@1- (0.0078125,0) [-256|255.9921875] "m"  MPC3
 SG_ TIPLLaneInfo3_prob1Lane_ub : 80|8@1+ (0.0078125,0) [0|1.9921875] ""  MPC3

BO_ 288 OnComingObj0: 12 RadarFrontCenter
 SG_ OnComingObj0_CRC : 0|8@1+ (1,0) [0|255] ""  MPC3
 SG_ OnComingObj0_MsgCtr : 8|4@1+ (1,0) [0|15] ""  MPC3
 SG_ OnComingObj0_blockCtr : 12|4@1+ (1,0) [0|15] ""  MPC3
 SG_ OnComingObj0_dWidth_sw : 16|16@1- (0.0078125,0) [-256|255.9921875] ""  MPC3
 SG_ OnComingObj0_dxv_sw : 32|16@1- (0.0078125,0) [-256|255.9921875] ""  MPC3
 SG_ OnComingObj0_dyv_sw : 48|16@1- (0.0078125,0) [-256|255.9921875] ""  MPC3
 SG_ OnComingObj0_Handle_ub : 64|8@1+ (1,0) [0|255] ""  MPC3
 SG_ OnComingObj0_RFF_ub : 72|8@1+ (1,0) [0|255] ""  MPC3
 SG_ OnComingObj0_vxv_sw : 80|16@1- (0.00390625,0) [-128|127.99609375] ""  MPC3

BO_ 289 OnComingObj1: 12 RadarFrontCenter
 SG_ OnComingObj1_CRC : 0|8@1+ (1,0) [0|255] ""  MPC3
 SG_ OnComingObj1_MsgCtr : 8|4@1+ (1,0) [0|15] ""  MPC3
 SG_ OnComingObj1_blockCtr : 12|4@1+ (1,0) [0|15] ""  MPC3
 SG_ OnComingObj1_dWidth_sw : 16|16@1- (0.0078125,0) [-256|255.9921875] ""  MPC3
 SG_ OnComingObj1_dxv_sw : 32|16@1- (0.0078125,0) [-256|255.9921875] ""  MPC3
 SG_ OnComingObj1_dyv_sw : 48|16@1- (0.0078125,0) [-256|255.9921875] ""  MPC3
 SG_ OnComingObj1_Handle_ub : 64|8@1+ (1,0) [0|255] ""  MPC3
 SG_ OnComingObj1_RFF_ub : 72|8@1+ (1,0) [0|255] ""  MPC3
 SG_ OnComingObj1_vxv_sw : 80|16@1- (0.00390625,0) [-128|127.99609375] ""  MPC3

BO_ 290 OnComingObj2: 12 RadarFrontCenter
 SG_ OnComingObj2_CRC : 0|8@1+ (1,0) [0|255] ""  MPC3
 SG_ OnComingObj2_MsgCtr : 8|4@1+ (1,0) [0|15] ""  MPC3
 SG_ OnComingObj2_blockCtr : 12|4@1+ (1,0) [0|15] ""  MPC3
 SG_ OnComingObj2_dWidth_sw : 16|16@1- (0.0078125,0) [-256|255.9921875] ""  MPC3
 SG_ OnComingObj2_dxv_sw : 32|16@1- (0.0078125,0) [-256|255.9921875] ""  MPC3
 SG_ OnComingObj2_dyv_sw : 48|16@1- (0.0078125,0) [-256|255.9921875] ""  MPC3
 SG_ OnComingObj2_Handle_ub : 64|8@1+ (1,0) [0|255] ""  MPC3
 SG_ OnComingObj2_RFF_ub : 72|8@1+ (1,0) [0|255] ""  MPC3
 SG_ OnComingObj2_vxv_sw : 80|16@1- (0.00390625,0) [-128|127.99609375] ""  MPC3

BO_ 291 OnComingObj3: 12 RadarFrontCenter
 SG_ OnComingObj3_CRC : 0|8@1+ (1,0) [0|255] ""  MPC3
 SG_ OnComingObj3_MsgCtr : 8|4@1+ (1,0) [0|15] ""  MPC3
 SG_ OnComingObj3_blockCtr : 12|4@1+ (1,0) [0|15] ""  MPC3
 SG_ OnComingObj3_dWidth_sw : 16|16@1- (0.0078125,0) [-256|255.9921875] ""  MPC3
 SG_ OnComingObj3_dxv_sw : 32|16@1- (0.0078125,0) [-256|255.9921875] ""  MPC3
 SG_ OnComingObj3_dyv_sw : 48|16@1- (0.0078125,0) [-256|255.9921875] ""  MPC3
 SG_ OnComingObj3_Handle_ub : 64|8@1+ (1,0) [0|255] ""  MPC3
 SG_ OnComingObj3_RFF_ub : 72|8@1+ (1,0) [0|255] ""  MPC3
 SG_ OnComingObj3_vxv_sw : 80|16@1- (0.00390625,0) [-128|127.99609375] ""  MPC3

BO_ 292 OnGoingObj0: 12 RadarFrontCenter
 SG_ OnGoingObj0_CRC : 0|8@1+ (1,0) [0|255] ""  MPC3
 SG_ OnGoingObj0_MsgCtr : 8|4@1+ (1,0) [0|15] ""  MPC3
 SG_ OnGoingObj0_blockCtr : 12|4@1+ (1,0) [0|15] ""  MPC3
 SG_ OnGoingObj0_dxv_sw : 16|16@1- (0.0078125,0) [-256|255.9921875] ""  MPC3
 SG_ OnGoingObj0_dyv_sw : 32|16@1- (0.0078125,0) [-256|255.9921875] ""  MPC3
 SG_ OnGoingObj0_Handle_ub : 48|8@1+ (1,0) [0|255] ""  MPC3
 SG_ OnGoingObj0_RFF_ub : 56|8@1+ (1,0) [0|255] ""  MPC3
 SG_ OnGoingObj0_vxv_sw : 64|16@1- (0.00390625,0) [-128|127.99609375] ""  MPC3

BO_ 293 OnGoingObj1: 12 RadarFrontCenter
 SG_ OnGoingObj1_CRC : 0|8@1+ (1,0) [0|255] ""  MPC3
 SG_ OnGoingObj1_MsgCtr : 8|4@1+ (1,0) [0|15] ""  MPC3
 SG_ OnGoingObj1_blockCtr : 12|4@1+ (1,0) [0|15] ""  MPC3
 SG_ OnGoingObj1_dxv_sw : 16|16@1- (0.0078125,0) [-256|255.9921875] ""  MPC3
 SG_ OnGoingObj1_dyv_sw : 32|16@1- (0.0078125,0) [-256|255.9921875] ""  MPC3
 SG_ OnGoingObj1_Handle_ub : 48|8@1+ (1,0) [0|255] ""  MPC3
 SG_ OnGoingObj1_RFF_ub : 56|8@1+ (1,0) [0|255] ""  MPC3
 SG_ OnGoingObj1_vxv_sw : 64|16@1- (0.00390625,0) [-128|127.99609375] ""  MPC3

BO_ 304 TrajPointACCObj0: 16 RadarFrontCenter
 SG_ TrajPointACCObj0_CRC : 0|8@1+ (1,0) [0|255] ""  MPC3
 SG_ TrajPointACCObj0_MsgCtr : 8|4@1+ (1,0) [0|15] ""  MPC3
 SG_ TrajPointACCObj0_blockCtr : 12|4@1+ (1,0) [0|15] ""  MPC3
 SG_ TrajPointACCObj0_Valid_b : 17|1@1+ (1,0) [0|1] ""  MPC3
 SG_ TrajPointACCObj0_Drive_b : 18|1@1+ (1,0) [0|1] ""  MPC3
 SG_ TrajPointACCObj0_Stand_b : 19|1@1+ (1,0) [0|1] ""  MPC3
 SG_ TrajPointACCObj0_InvDir_b : 21|1@1+ (1,0) [0|1] ""  MPC3
 SG_ TrajPointACCObj0_Stopped_b : 22|1@1+ (1,0) [0|1] ""  MPC3
 SG_ TrajPointACCObj0_TrajEnd_b : 23|1@1+ (1,0) [0|1] ""  MPC3
 SG_ TrajPointACCObj0_dVarXv_uw : 24|16@1+ (0.001953125,0) [0|127.998046875] ""  MPC3
 SG_ TrajPointACCObj0_dVarYv_uw : 40|16@1+ (0.001953125,0) [0|127.998046875] ""  MPC3
 SG_ TrajPointACCObj0_dxv_sw : 56|16@1- (0.0078125,0) [-256|255.9921875] ""  MPC3
 SG_ TrajPointACCObj0_dyv_sw : 72|16@1- (0.0078125,0) [-256|255.9921875] ""  MPC3
 SG_ TrajPointACCObj0_wExistProb_ub : 88|8@1+ (0.00390625,0) [0|0.99609375] ""  MPC3
 SG_ TrajPointACCObj0_timestamp : 96|16@1+ (0.00048828125,0) [0|32] ""  MPC3

BO_ 305 TrajPointACCObj1: 16 RadarFrontCenter
 SG_ TrajPointACCObj1_CRC : 0|8@1+ (1,0) [0|255] ""  MPC3
 SG_ TrajPointACCObj1_MsgCtr : 8|4@1+ (1,0) [0|15] ""  MPC3
 SG_ TrajPointACCObj1_blockCtr : 12|4@1+ (1,0) [0|15] ""  MPC3
 SG_ TrajPointACCObj1_Valid_b : 17|1@1+ (1,0) [0|1] ""  MPC3
 SG_ TrajPointACCObj1_Drive_b : 18|1@1+ (1,0) [0|1] ""  MPC3
 SG_ TrajPointACCObj1_Stand_b : 19|1@1+ (1,0) [0|1] ""  MPC3
 SG_ TrajPointACCObj1_InvDir_b : 21|1@1+ (1,0) [0|1] ""  MPC3
 SG_ TrajPointACCObj1_Stopped_b : 22|1@1+ (1,0) [0|1] ""  MPC3
 SG_ TrajPointACCObj1_TrajEnd_b : 23|1@1+ (1,0) [0|1] ""  MPC3
 SG_ TrajPointACCObj1_dVarXv_uw : 24|16@1+ (0.001953125,0) [0|127.998046875] ""  MPC3
 SG_ TrajPointACCObj1_dVarYv_uw : 40|16@1+ (0.001953125,0) [0|127.998046875] ""  MPC3
 SG_ TrajPointACCObj1_dxv_sw : 56|16@1- (0.0078125,0) [-256|255.9921875] ""  MPC3
 SG_ TrajPointACCObj1_dyv_sw : 72|16@1- (0.0078125,0) [-256|255.9921875] ""  MPC3
 SG_ TrajPointACCObj1_wExistProb_ub : 88|8@1+ (0.00390625,0) [0|0.99609375] ""  MPC3
 SG_ TrajPointACCObj1_timestamp : 96|16@1+ (0.00048828125,0) [0|32] ""  MPC3

BO_ 306 TrajPointACCObj2: 16 RadarFrontCenter
 SG_ TrajPointACCObj2_CRC : 0|8@1+ (1,0) [0|255] ""  MPC3
 SG_ TrajPointACCObj2_MsgCtr : 8|4@1+ (1,0) [0|15] ""  MPC3
 SG_ TrajPointACCObj2_blockCtr : 12|4@1+ (1,0) [0|15] ""  MPC3
 SG_ TrajPointACCObj2_Valid_b : 17|1@1+ (1,0) [0|1] ""  MPC3
 SG_ TrajPointACCObj2_Drive_b : 18|1@1+ (1,0) [0|1] ""  MPC3
 SG_ TrajPointACCObj2_Stand_b : 19|1@1+ (1,0) [0|1] ""  MPC3
 SG_ TrajPointACCObj2_InvDir_b : 21|1@1+ (1,0) [0|1] ""  MPC3
 SG_ TrajPointACCObj2_Stopped_b : 22|1@1+ (1,0) [0|1] ""  MPC3
 SG_ TrajPointACCObj2_TrajEnd_b : 23|1@1+ (1,0) [0|1] ""  MPC3
 SG_ TrajPointACCObj2_dVarXv_uw : 24|16@1+ (0.001953125,0) [0|127.998046875] ""  MPC3
 SG_ TrajPointACCObj2_dVarYv_uw : 40|16@1+ (0.001953125,0) [0|127.998046875] ""  MPC3
 SG_ TrajPointACCObj2_dxv_sw : 56|16@1- (0.0078125,0) [-256|255.9921875] ""  MPC3
 SG_ TrajPointACCObj2_dyv_sw : 72|16@1- (0.0078125,0) [-256|255.9921875] ""  MPC3
 SG_ TrajPointACCObj2_wExistProb_ub : 88|8@1+ (0.00390625,0) [0|0.99609375] ""  MPC3
 SG_ TrajPointACCObj2_timestamp : 96|16@1+ (0.00048828125,0) [0|32] ""  MPC3

BO_ 307 TrajPointACCObj3: 16 RadarFrontCenter
 SG_ TrajPointACCObj3_CRC : 0|8@1+ (1,0) [0|255] ""  MPC3
 SG_ TrajPointACCObj3_MsgCtr : 8|4@1+ (1,0) [0|15] ""  MPC3
 SG_ TrajPointACCObj3_blockCtr : 12|4@1+ (1,0) [0|15] ""  MPC3
 SG_ TrajPointACCObj3_Valid_b : 17|1@1+ (1,0) [0|1] ""  MPC3
 SG_ TrajPointACCObj3_Drive_b : 18|1@1+ (1,0) [0|1] ""  MPC3
 SG_ TrajPointACCObj3_Stand_b : 19|1@1+ (1,0) [0|1] ""  MPC3
 SG_ TrajPointACCObj3_InvDir_b : 21|1@1+ (1,0) [0|1] ""  MPC3
 SG_ TrajPointACCObj3_Stopped_b : 22|1@1+ (1,0) [0|1] ""  MPC3
 SG_ TrajPointACCObj3_TrajEnd_b : 23|1@1+ (1,0) [0|1] ""  MPC3
 SG_ TrajPointACCObj3_dVarXv_uw : 24|16@1+ (0.001953125,0) [0|127.998046875] ""  MPC3
 SG_ TrajPointACCObj3_dVarYv_uw : 40|16@1+ (0.001953125,0) [0|127.998046875] ""  MPC3
 SG_ TrajPointACCObj3_dxv_sw : 56|16@1- (0.0078125,0) [-256|255.9921875] ""  MPC3
 SG_ TrajPointACCObj3_dyv_sw : 72|16@1- (0.0078125,0) [-256|255.9921875] ""  MPC3
 SG_ TrajPointACCObj3_wExistProb_ub : 88|8@1+ (0.00390625,0) [0|0.99609375] ""  MPC3
 SG_ TrajPointACCObj3_timestamp : 96|16@1+ (0.00048828125,0) [0|32] ""  MPC3

BO_ 308 TrajPointACCObj4: 16 RadarFrontCenter
 SG_ TrajPointACCObj4_CRC : 0|8@1+ (1,0) [0|255] ""  MPC3
 SG_ TrajPointACCObj4_MsgCtr : 8|4@1+ (1,0) [0|15] ""  MPC3
 SG_ TrajPointACCObj4_blockCtr : 12|4@1+ (1,0) [0|15] ""  MPC3
 SG_ TrajPointACCObj4_Valid_b : 17|1@1+ (1,0) [0|1] ""  MPC3
 SG_ TrajPointACCObj4_Drive_b : 18|1@1+ (1,0) [0|1] ""  MPC3
 SG_ TrajPointACCObj4_Stand_b : 19|1@1+ (1,0) [0|1] ""  MPC3
 SG_ TrajPointACCObj4_InvDir_b : 21|1@1+ (1,0) [0|1] ""  MPC3
 SG_ TrajPointACCObj4_Stopped_b : 22|1@1+ (1,0) [0|1] ""  MPC3
 SG_ TrajPointACCObj4_TrajEnd_b : 23|1@1+ (1,0) [0|1] ""  MPC3
 SG_ TrajPointACCObj4_dVarXv_uw : 24|16@1+ (0.001953125,0) [0|127.998046875] ""  MPC3
 SG_ TrajPointACCObj4_dVarYv_uw : 40|16@1+ (0.001953125,0) [0|127.998046875] ""  MPC3
 SG_ TrajPointACCObj4_dxv_sw : 56|16@1- (0.0078125,0) [-256|255.9921875] ""  MPC3
 SG_ TrajPointACCObj4_dyv_sw : 72|16@1- (0.0078125,0) [-256|255.9921875] ""  MPC3
 SG_ TrajPointACCObj4_wExistProb_ub : 88|8@1+ (0.00390625,0) [0|0.99609375] ""  MPC3
 SG_ TrajPointACCObj4_timestamp : 96|16@1+ (0.00048828125,0) [0|32] ""  MPC3

BO_ 309 TrajPointACCObj5: 16 RadarFrontCenter
 SG_ TrajPointACCObj5_CRC : 0|8@1+ (1,0) [0|255] ""  MPC3
 SG_ TrajPointACCObj5_MsgCtr : 8|4@1+ (1,0) [0|15] ""  MPC3
 SG_ TrajPointACCObj5_blockCtr : 12|4@1+ (1,0) [0|15] ""  MPC3
 SG_ TrajPointACCObj5_Valid_b : 17|1@1+ (1,0) [0|1] ""  MPC3
 SG_ TrajPointACCObj5_Drive_b : 18|1@1+ (1,0) [0|1] ""  MPC3
 SG_ TrajPointACCObj5_Stand_b : 19|1@1+ (1,0) [0|1] ""  MPC3
 SG_ TrajPointACCObj5_InvDir_b : 21|1@1+ (1,0) [0|1] ""  MPC3
 SG_ TrajPointACCObj5_Stopped_b : 22|1@1+ (1,0) [0|1] ""  MPC3
 SG_ TrajPointACCObj5_TrajEnd_b : 23|1@1+ (1,0) [0|1] ""  MPC3
 SG_ TrajPointACCObj5_dVarXv_uw : 24|16@1+ (0.001953125,0) [0|127.998046875] ""  MPC3
 SG_ TrajPointACCObj5_dVarYv_uw : 40|16@1+ (0.001953125,0) [0|127.998046875] ""  MPC3
 SG_ TrajPointACCObj5_dxv_sw : 56|16@1- (0.0078125,0) [-256|255.9921875] ""  MPC3
 SG_ TrajPointACCObj5_dyv_sw : 72|16@1- (0.0078125,0) [-256|255.9921875] ""  MPC3
 SG_ TrajPointACCObj5_wExistProb_ub : 88|8@1+ (0.00390625,0) [0|0.99609375] ""  MPC3
 SG_ TrajPointACCObj5_timestamp : 96|16@1+ (0.00048828125,0) [0|32] ""  MPC3

BO_ 310 TrajPointACCObj6: 16 RadarFrontCenter
 SG_ TrajPointACCObj6_CRC : 0|8@1+ (1,0) [0|255] ""  MPC3
 SG_ TrajPointACCObj6_MsgCtr : 8|4@1+ (1,0) [0|15] ""  MPC3
 SG_ TrajPointACCObj6_blockCtr : 12|4@1+ (1,0) [0|15] ""  MPC3
 SG_ TrajPointACCObj6_Valid_b : 17|1@1+ (1,0) [0|1] ""  MPC3
 SG_ TrajPointACCObj6_Stand_b : 18|1@1+ (1,0) [0|1] ""  MPC3
 SG_ TrajPointACCObj6_Drive_b : 19|1@1+ (1,0) [0|1] ""  MPC3
 SG_ TrajPointACCObj6_InvDir_b : 21|1@1+ (1,0) [0|1] ""  MPC3
 SG_ TrajPointACCObj6_Stopped_b : 22|1@1+ (1,0) [0|1] ""  MPC3
 SG_ TrajPointACCObj6_TrajEnd_b : 23|1@1+ (1,0) [0|1] ""  MPC3
 SG_ TrajPointACCObj6_dVarXv_uw : 24|16@1+ (0.001953125,0) [0|127.998046875] ""  MPC3
 SG_ TrajPointACCObj6_dVarYv_uw : 40|16@1+ (0.001953125,0) [0|127.998046875] ""  MPC3
 SG_ TrajPointACCObj6_dxv_sw : 56|16@1- (0.0078125,0) [-256|255.9921875] ""  MPC3
 SG_ TrajPointACCObj6_dyv_sw : 72|16@1- (0.0078125,0) [-256|255.9921875] ""  MPC3
 SG_ TrajPointACCObj6_wExistProb_ub : 88|8@1+ (0.00390625,0) [0|0.99609375] ""  MPC3
 SG_ TrajPointACCObj6_timestamp : 96|16@1+ (0.00048828125,0) [0|32] ""  MPC3

BO_ 311 TrajPointACCObj7: 16 RadarFrontCenter
 SG_ TrajPointACCObj7_CRC : 0|8@1+ (1,0) [0|255] ""  MPC3
 SG_ TrajPointACCObj7_MsgCtr : 8|4@1+ (1,0) [0|15] ""  MPC3
 SG_ TrajPointACCObj7_blockCtr : 12|4@1+ (1,0) [0|15] ""  MPC3
 SG_ TrajPointACCObj7_Valid_b : 17|1@1+ (1,0) [0|1] ""  MPC3
 SG_ TrajPointACCObj7_Drive_b : 18|1@1+ (1,0) [0|1] ""  MPC3
 SG_ TrajPointACCObj7_Stand_b : 19|1@1+ (1,0) [0|1] ""  MPC3
 SG_ TrajPointACCObj7_InvDir_b : 21|1@1+ (1,0) [0|1] ""  MPC3
 SG_ TrajPointACCObj7_Stopped_b : 22|1@1+ (1,0) [0|1] ""  MPC3
 SG_ TrajPointACCObj7_TrajEnd_b : 23|1@1+ (1,0) [0|1] ""  MPC3
 SG_ TrajPointACCObj7_dVarXv_uw : 24|16@1+ (0.001953125,0) [0|127.998046875] ""  MPC3
 SG_ TrajPointACCObj7_dVarYv_uw : 40|16@1+ (0.001953125,0) [0|127.998046875] ""  MPC3
 SG_ TrajPointACCObj7_dxv_sw : 56|16@1- (0.0078125,0) [-256|255.9921875] ""  MPC3
 SG_ TrajPointACCObj7_dyv_sw : 72|16@1- (0.0078125,0) [-256|255.9921875] ""  MPC3
 SG_ TrajPointACCObj7_wExistProb_ub : 88|8@1+ (0.00390625,0) [0|0.99609375] ""  MPC3
 SG_ TrajPointACCObj7_timestamp : 96|16@1+ (0.00048828125,0) [0|32] ""  MPC3

BO_ 312 TrajPointACCObj8: 16 RadarFrontCenter
 SG_ TrajPointACCObj8_CRC : 0|8@1+ (1,0) [0|255] ""  MPC3
 SG_ TrajPointACCObj8_MsgCtr : 8|4@1+ (1,0) [0|15] ""  MPC3
 SG_ TrajPointACCObj8_blockCtr : 12|4@1+ (1,0) [0|15] ""  MPC3
 SG_ TrajPointACCObj8_Valid_b : 17|1@1+ (1,0) [0|1] ""  MPC3
 SG_ TrajPointACCObj8_Drive_b : 18|1@1+ (1,0) [0|1] ""  MPC3
 SG_ TrajPointACCObj8_Stand_b : 19|1@1+ (1,0) [0|1] ""  MPC3
 SG_ TrajPointACCObj8_InvDir_b : 21|1@1+ (1,0) [0|1] ""  MPC3
 SG_ TrajPointACCObj8_Stopped_b : 22|1@1+ (1,0) [0|1] ""  MPC3
 SG_ TrajPointACCObj8_TrajEnd_b : 23|1@1+ (1,0) [0|1] ""  MPC3
 SG_ TrajPointACCObj8_dVarXv_uw : 24|16@1+ (0.001953125,0) [0|127.998046875] ""  MPC3
 SG_ TrajPointACCObj8_dVarYv_uw : 40|16@1+ (0.001953125,0) [0|127.998046875] ""  MPC3
 SG_ TrajPointACCObj8_dxv_sw : 56|16@1- (0.0078125,0) [-256|255.9921875] ""  MPC3
 SG_ TrajPointACCObj8_dyv_sw : 72|16@1- (0.0078125,0) [-256|255.9921875] ""  MPC3
 SG_ TrajPointACCObj8_wExistProb_ub : 88|8@1+ (0.00390625,0) [0|0.99609375] ""  MPC3
 SG_ TrajPointACCObj8_timestamp : 96|16@1+ (0.00048828125,0) [0|32] ""  MPC3

BO_ 313 TrajPointACCObj9: 16 RadarFrontCenter
 SG_ TrajPointACCObj9_CRC : 0|8@1+ (1,0) [0|255] ""  MPC3
 SG_ TrajPointACCObj9_MsgCtr : 8|4@1+ (1,0) [0|15] ""  MPC3
 SG_ TrajPointACCObj9_blockCtr : 12|4@1+ (1,0) [0|15] ""  MPC3
 SG_ TrajPointACCObj9_Valid_b : 17|1@1+ (1,0) [0|1] ""  MPC3
 SG_ TrajPointACCObj9_Drive_b : 18|1@1+ (1,0) [0|1] ""  MPC3
 SG_ TrajPointACCObj9_Stand_b : 19|1@1+ (1,0) [0|1] ""  MPC3
 SG_ TrajPointACCObj9_InvDir_b : 21|1@1+ (1,0) [0|1] ""  MPC3
 SG_ TrajPointACCObj9_Stopped_b : 22|1@1+ (1,0) [0|1] ""  MPC3
 SG_ TrajPointACCObj9_TrajEnd_b : 23|1@1+ (1,0) [0|1] ""  MPC3
 SG_ TrajPointACCObj9_dVarXv_uw : 24|16@1+ (0.001953125,0) [0|127.998046875] ""  MPC3
 SG_ TrajPointACCObj9_dVarYv_uw : 40|16@1+ (0.001953125,0) [0|127.998046875] ""  MPC3
 SG_ TrajPointACCObj9_dxv_sw : 56|16@1- (0.0078125,0) [-256|255.9921875] ""  MPC3
 SG_ TrajPointACCObj9_dyv_sw : 72|16@1- (0.0078125,0) [-256|255.9921875] ""  MPC3
 SG_ TrajPointACCObj9_wExistProb_ub : 88|8@1+ (0.00390625,0) [0|0.99609375] ""  MPC3
 SG_ TrajPointACCObj9_timestamp : 96|16@1+ (0.00048828125,0) [0|32] ""  MPC3

BO_ 320 TrajPointACCObj10: 16 RadarFrontCenter
 SG_ TrajPointACCObj10_CRC : 0|8@1+ (1,0) [0|255] ""  MPC3
 SG_ TrajPointACCObj10_MsgCtr : 8|4@1+ (1,0) [0|15] ""  MPC3
 SG_ TrajPointACCObj10_blockCtr : 12|4@1+ (1,0) [0|15] ""  MPC3
 SG_ TrajPointACCObj10_Valid_b : 17|1@1+ (1,0) [0|1] ""  MPC3
 SG_ TrajPointACCObj10_Drive_b : 18|1@1+ (1,0) [0|1] ""  MPC3
 SG_ TrajPointACCObj10_Stand_b : 19|1@1+ (1,0) [0|1] ""  MPC3
 SG_ TrajPointACCObj10_InvDir_b : 21|1@1+ (1,0) [0|1] ""  MPC3
 SG_ TrajPointACCObj10_Stopped_b : 22|1@1+ (1,0) [0|1] ""  MPC3
 SG_ TrajPointACCObj10_TrajEnd_b : 23|1@1+ (1,0) [0|1] ""  MPC3
 SG_ TrajPointACCObj10_dVarXv_uw : 24|16@1+ (0.001953125,0) [0|127.998046875] ""  MPC3
 SG_ TrajPointACCObj10_dVarYv_uw : 40|16@1+ (0.001953125,0) [0|127.998046875] ""  MPC3
 SG_ TrajPointACCObj10_dxv_sw : 56|16@1- (0.0078125,0) [-256|255.9921875] ""  MPC3
 SG_ TrajPointACCObj10_dyv_sw : 72|16@1- (0.0078125,0) [-256|255.9921875] ""  MPC3
 SG_ TrajPointACCObj10_wExistProb_ub : 88|8@1+ (0.00390625,0) [0|0.99609375] ""  MPC3
 SG_ TrajPointACCObj10_timestamp : 96|16@1+ (0.00048828125,0) [0|32] ""  MPC3

BO_ 321 TrajPointACCObj11: 16 RadarFrontCenter
 SG_ TrajPointACCObj11_CRC : 0|8@1+ (1,0) [0|255] ""  MPC3
 SG_ TrajPointACCObj11_MsgCtr : 8|4@1+ (1,0) [0|15] ""  MPC3
 SG_ TrajPointACCObj11_blockCtr : 12|4@1+ (1,0) [0|15] ""  MPC3
 SG_ TrajPointACCObj11_Valid_b : 17|1@1+ (1,0) [0|1] ""  MPC3
 SG_ TrajPointACCObj11_Drive_b : 18|1@1+ (1,0) [0|1] ""  MPC3
 SG_ TrajPointACCObj11_Stand_b : 19|1@1+ (1,0) [0|1] ""  MPC3
 SG_ TrajPointACCObj11_InvDir_b : 21|1@1+ (1,0) [0|1] ""  MPC3
 SG_ TrajPointACCObj11_Stopped_b : 22|1@1+ (1,0) [0|1] ""  MPC3
 SG_ TrajPointACCObj11_TrajEnd_b : 23|1@1+ (1,0) [0|1] ""  MPC3
 SG_ TrajPointACCObj11_dVarXv_uw : 24|16@1+ (0.001953125,0) [0|127.998046875] ""  MPC3
 SG_ TrajPointACCObj11_dVarYv_uw : 40|16@1+ (0.001953125,0) [0|127.998046875] ""  MPC3
 SG_ TrajPointACCObj11_dxv_sw : 56|16@1- (0.0078125,0) [-256|255.9921875] ""  MPC3
 SG_ TrajPointACCObj11_dyv_sw : 72|16@1- (0.0078125,0) [-256|255.9921875] ""  MPC3
 SG_ TrajPointACCObj11_wExistProb_ub : 88|8@1+ (0.00390625,0) [0|0.99609375] ""  MPC3
 SG_ TrajPointACCObj11_timestamp : 96|16@1+ (0.00048828125,0) [0|32] ""  MPC3

BO_ 322 TrajPointACCObj12: 16 RadarFrontCenter
 SG_ TrajPointACCObj12_CRC : 0|8@1+ (1,0) [0|255] ""  MPC3
 SG_ TrajPointACCObj12_MsgCtr : 8|4@1+ (1,0) [0|15] ""  MPC3
 SG_ TrajPointACCObj12_blockCtr : 12|4@1+ (1,0) [0|15] ""  MPC3
 SG_ TrajPointACCObj12_Valid_b : 17|1@1+ (1,0) [0|1] ""  MPC3
 SG_ TrajPointACCObj12_Drive_b : 18|1@1+ (1,0) [0|1] ""  MPC3
 SG_ TrajPointACCObj12_Stand_b : 19|1@1+ (1,0) [0|1] ""  MPC3
 SG_ TrajPointACCObj12_InvDir_b : 21|1@1+ (1,0) [0|1] ""  MPC3
 SG_ TrajPointACCObj12_Stopped_b : 22|1@1+ (1,0) [0|1] ""  MPC3
 SG_ TrajPointACCObj12_TrajEnd_b : 23|1@1+ (1,0) [0|1] ""  MPC3
 SG_ TrajPointACCObj12_dVarXv_uw : 24|16@1+ (0.001953125,0) [0|127.998046875] ""  MPC3
 SG_ TrajPointACCObj12_dVarYv_uw : 40|16@1+ (0.001953125,0) [0|127.998046875] ""  MPC3
 SG_ TrajPointACCObj12_dxv_sw : 56|16@1- (0.0078125,0) [-256|255.9921875] ""  MPC3
 SG_ TrajPointACCObj12_dyv_sw : 72|16@1- (0.0078125,0) [-256|255.9921875] ""  MPC3
 SG_ TrajPointACCObj12_wExistProb_ub : 88|8@1+ (0.00390625,0) [0|0.99609375] ""  MPC3
 SG_ TrajPointACCObj12_timestamp : 96|16@1+ (0.00048828125,0) [0|32] ""  MPC3

BO_ 323 TrajPointACCObj13: 16 RadarFrontCenter
 SG_ TrajPointACCObj13_CRC : 0|8@1+ (1,0) [0|255] ""  MPC3
 SG_ TrajPointACCObj13_MsgCtr : 8|4@1+ (1,0) [0|15] ""  MPC3
 SG_ TrajPointACCObj13_blockCtr : 12|4@1+ (1,0) [0|15] ""  MPC3
 SG_ TrajPointACCObj13_Valid_b : 17|1@1+ (1,0) [0|1] ""  MPC3
 SG_ TrajPointACCObj13_Drive_b : 18|1@1+ (1,0) [0|1] ""  MPC3
 SG_ TrajPointACCObj13_Stand_b : 19|1@1+ (1,0) [0|1] ""  MPC3
 SG_ TrajPointACCObj13_InvDir_b : 21|1@1+ (1,0) [0|1] ""  MPC3
 SG_ TrajPointACCObj13_Stopped_b : 22|1@1+ (1,0) [0|1] ""  MPC3
 SG_ TrajPointACCObj13_TrajEnd_b : 23|1@1+ (1,0) [0|1] ""  MPC3
 SG_ TrajPointACCObj13_dVarXv_uw : 24|16@1+ (0.001953125,0) [0|127.998046875] ""  MPC3
 SG_ TrajPointACCObj13_dVarYv_uw : 40|16@1+ (0.001953125,0) [0|127.998046875] ""  MPC3
 SG_ TrajPointACCObj13_dxv_sw : 56|16@1- (0.0078125,0) [-256|255.9921875] ""  MPC3
 SG_ TrajPointACCObj13_dyv_sw : 72|16@1- (0.0078125,0) [-256|255.9921875] ""  MPC3
 SG_ TrajPointACCObj13_wExistProb_ub : 88|8@1+ (0.00390625,0) [0|0.99609375] ""  MPC3
 SG_ TrajPointACCObj13_timestamp : 96|16@1+ (0.00048828125,0) [0|32] ""  MPC3

BO_ 324 TrajPointACCObj14: 16 RadarFrontCenter
 SG_ TrajPointACCObj14_CRC : 0|8@1+ (1,0) [0|255] ""  MPC3
 SG_ TrajPointACCObj14_MsgCtr : 8|4@1+ (1,0) [0|15] ""  MPC3
 SG_ TrajPointACCObj14_blockCtr : 12|4@1+ (1,0) [0|15] ""  MPC3
 SG_ TrajPointACCObj14_Valid_b : 17|1@1+ (1,0) [0|1] ""  MPC3
 SG_ TrajPointACCObj14_Drive_b : 18|1@1+ (1,0) [0|1] ""  MPC3
 SG_ TrajPointACCObj14_Stand_b : 19|1@1+ (1,0) [0|1] ""  MPC3
 SG_ TrajPointACCObj14_InvDir_b : 21|1@1+ (1,0) [0|1] ""  MPC3
 SG_ TrajPointACCObj14_Stopped_b : 22|1@1+ (1,0) [0|1] ""  MPC3
 SG_ TrajPointACCObj14_TrajEnd_b : 23|1@1+ (1,0) [0|1] ""  MPC3
 SG_ TrajPointACCObj14_dVarXv_uw : 24|16@1+ (0.001953125,0) [0|127.998046875] ""  MPC3
 SG_ TrajPointACCObj14_dVarYv_uw : 40|16@1+ (0.001953125,0) [0|127.998046875] ""  MPC3
 SG_ TrajPointACCObj14_dxv_sw : 56|16@1- (0.0078125,0) [-256|255.9921875] ""  MPC3
 SG_ TrajPointACCObj14_dyv_sw : 72|16@1- (0.0078125,0) [-256|255.9921875] ""  MPC3
 SG_ TrajPointACCObj14_wExistProb_ub : 88|8@1+ (0.00390625,0) [0|0.99609375] ""  MPC3
 SG_ TrajPointACCObj14_timestamp : 96|16@1+ (0.00048828125,0) [0|32] ""  MPC3

BO_ 325 TrajPointACCObj15: 16 RadarFrontCenter
 SG_ TrajPointACCObj15_CRC : 0|8@1+ (1,0) [0|255] ""  MPC3
 SG_ TrajPointACCObj15_MsgCtr : 8|4@1+ (1,0) [0|15] ""  MPC3
 SG_ TrajPointACCObj15_blockCtr : 12|4@1+ (1,0) [0|15] ""  MPC3
 SG_ TrajPointACCObj15_Valid_b : 17|1@1+ (1,0) [0|1] ""  MPC3
 SG_ TrajPointACCObj15_Drive_b : 18|1@1+ (1,0) [0|1] ""  MPC3
 SG_ TrajPointACCObj15_Stand_b : 19|1@1+ (1,0) [0|1] ""  MPC3
 SG_ TrajPointACCObj15_InvDir_b : 21|1@1+ (1,0) [0|1] ""  MPC3
 SG_ TrajPointACCObj15_Stopped_b : 22|1@1+ (1,0) [0|1] ""  MPC3
 SG_ TrajPointACCObj15_TrajEnd_b : 23|1@1+ (1,0) [0|1] ""  MPC3
 SG_ TrajPointACCObj15_dVarXv_uw : 24|16@1+ (0.001953125,0) [0|127.998046875] ""  MPC3
 SG_ TrajPointACCObj15_dVarYv_uw : 40|16@1+ (0.001953125,0) [0|127.998046875] ""  MPC3
 SG_ TrajPointACCObj15_dxv_sw : 56|16@1- (0.0078125,0) [-256|255.9921875] ""  MPC3
 SG_ TrajPointACCObj15_dyv_sw : 72|16@1- (0.0078125,0) [-256|255.9921875] ""  MPC3
 SG_ TrajPointACCObj15_wExistProb_ub : 88|8@1+ (0.00390625,0) [0|0.99609375] ""  MPC3
 SG_ TrajPointACCObj15_timestamp : 96|16@1+ (0.00048828125,0) [0|32] ""  MPC3

BO_ 326 TrajPointACCObj16: 16 RadarFrontCenter
 SG_ TrajPointACCObj16_CRC : 0|8@1+ (1,0) [0|255] ""  MPC3
 SG_ TrajPointACCObj16_MsgCtr : 8|4@1+ (1,0) [0|15] ""  MPC3
 SG_ TrajPointACCObj16_blockCtr : 12|4@1+ (1,0) [0|15] ""  MPC3
 SG_ TrajPointACCObj16_Valid_b : 17|1@1+ (1,0) [0|1] ""  MPC3
 SG_ TrajPointACCObj16_Drive_b : 18|1@1+ (1,0) [0|1] ""  MPC3
 SG_ TrajPointACCObj16_Stand_b : 19|1@1+ (1,0) [0|1] ""  MPC3
 SG_ TrajPointACCObj16_InvDir_b : 21|1@1+ (1,0) [0|1] ""  MPC3
 SG_ TrajPointACCObj16_Stopped_b : 22|1@1+ (1,0) [0|1] ""  MPC3
 SG_ TrajPointACCObj16_TrajEnd_b : 23|1@1+ (1,0) [0|1] ""  MPC3
 SG_ TrajPointACCObj16_dVarXv_uw : 24|16@1+ (0.001953125,0) [0|127.998046875] ""  MPC3
 SG_ TrajPointACCObj16_dVarYv_uw : 40|16@1+ (0.001953125,0) [0|127.998046875] ""  MPC3
 SG_ TrajPointACCObj16_dxv_sw : 56|16@1- (0.0078125,0) [-256|255.9921875] ""  MPC3
 SG_ TrajPointACCObj16_dyv_sw : 72|16@1- (0.0078125,0) [-256|255.9921875] ""  MPC3
 SG_ TrajPointACCObj16_wExistProb_ub : 88|8@1+ (0.00390625,0) [0|0.99609375] ""  MPC3
 SG_ TrajPointACCObj16_timestamp : 96|16@1+ (0.00048828125,0) [0|32] ""  MPC3

BO_ 327 TrajPointACCObj17: 16 RadarFrontCenter
 SG_ TrajPointACCObj17_CRC : 0|8@1+ (1,0) [0|255] ""  MPC3
 SG_ TrajPointACCObj17_MsgCtr : 8|4@1+ (1,0) [0|15] ""  MPC3
 SG_ TrajPointACCObj17_blockCtr : 12|4@1+ (1,0) [0|15] ""  MPC3
 SG_ TrajPointACCObj17_Valid_b : 17|1@1+ (1,0) [0|1] ""  MPC3
 SG_ TrajPointACCObj17_Drive_b : 18|1@1+ (1,0) [0|1] ""  MPC3
 SG_ TrajPointACCObj17_Stand_b : 19|1@1+ (1,0) [0|1] ""  MPC3
 SG_ TrajPointACCObj17_InvDir_b : 21|1@1+ (1,0) [0|1] ""  MPC3
 SG_ TrajPointACCObj17_Stopped_b : 22|1@1+ (1,0) [0|1] ""  MPC3
 SG_ TrajPointACCObj17_TrajEnd_b : 23|1@1+ (1,0) [0|1] ""  MPC3
 SG_ TrajPointACCObj17_dVarXv_uw : 24|16@1+ (0.001953125,0) [0|127.998046875] ""  MPC3
 SG_ TrajPointACCObj17_dVarYv_uw : 40|16@1+ (0.001953125,0) [0|127.998046875] ""  MPC3
 SG_ TrajPointACCObj17_dxv_sw : 56|16@1- (0.0078125,0) [-256|255.9921875] ""  MPC3
 SG_ TrajPointACCObj17_dyv_sw : 72|16@1- (0.0078125,0) [-256|255.9921875] ""  MPC3
 SG_ TrajPointACCObj17_wExistProb_ub : 88|8@1+ (0.00390625,0) [0|0.99609375] ""  MPC3
 SG_ TrajPointACCObj17_timestamp : 96|16@1+ (0.00048828125,0) [0|32] ""  MPC3

BO_ 328 TrajPointACCObj18: 16 RadarFrontCenter
 SG_ TrajPointACCObj18_CRC : 0|8@1+ (1,0) [0|255] ""  MPC3
 SG_ TrajPointACCObj18_MsgCtr : 8|4@1+ (1,0) [0|15] ""  MPC3
 SG_ TrajPointACCObj18_blockCtr : 12|4@1+ (1,0) [0|15] ""  MPC3
 SG_ TrajPointACCObj18_Valid_b : 17|1@1+ (1,0) [0|1] ""  MPC3
 SG_ TrajPointACCObj18_Drive_b : 18|1@1+ (1,0) [0|1] ""  MPC3
 SG_ TrajPointACCObj18_Stand_b : 19|1@1+ (1,0) [0|1] ""  MPC3
 SG_ TrajPointACCObj18_InvDir_b : 21|1@1+ (1,0) [0|1] ""  MPC3
 SG_ TrajPointACCObj18_Stopped_b : 22|1@1+ (1,0) [0|1] ""  MPC3
 SG_ TrajPointACCObj18_TrajEnd_b : 23|1@1+ (1,0) [0|1] ""  MPC3
 SG_ TrajPointACCObj18_dVarXv_uw : 24|16@1+ (0.001953125,0) [0|127.998046875] ""  MPC3
 SG_ TrajPointACCObj18_dVarYv_uw : 40|16@1+ (0.001953125,0) [0|127.998046875] ""  MPC3
 SG_ TrajPointACCObj18_dxv_sw : 56|16@1- (0.0078125,0) [-256|255.9921875] ""  MPC3
 SG_ TrajPointACCObj18_dyv_sw : 72|16@1- (0.0078125,0) [-256|255.9921875] ""  MPC3
 SG_ TrajPointACCObj18_wExistProb_ub : 88|8@1+ (0.00390625,0) [0|0.99609375] ""  MPC3
 SG_ TrajPointACCObj18_timestamp : 96|16@1+ (0.00048828125,0) [0|32] ""  MPC3

BO_ 329 TrajPointACCObj19: 16 RadarFrontCenter
 SG_ TrajPointACCObj19_CRC : 0|8@1+ (1,0) [0|255] ""  MPC3
 SG_ TrajPointACCObj19_MsgCtr : 8|4@1+ (1,0) [0|15] ""  MPC3
 SG_ TrajPointACCObj19_blockCtr : 12|4@1+ (1,0) [0|15] ""  MPC3
 SG_ TrajPointACCObj19_Valid_b : 17|1@1+ (1,0) [0|1] ""  MPC3
 SG_ TrajPointACCObj19_Drive_b : 18|1@1+ (1,0) [0|1] ""  MPC3
 SG_ TrajPointACCObj19_Stand_b : 19|1@1+ (1,0) [0|1] ""  MPC3
 SG_ TrajPointACCObj19_InvDir_b : 21|1@1+ (1,0) [0|1] ""  MPC3
 SG_ TrajPointACCObj19_Stopped_b : 22|1@1+ (1,0) [0|1] ""  MPC3
 SG_ TrajPointACCObj19_TrajEnd_b : 23|1@1+ (1,0) [0|1] ""  MPC3
 SG_ TrajPointACCObj19_dVarXv_uw : 24|16@1+ (0.001953125,0) [0|127.998046875] ""  MPC3
 SG_ TrajPointACCObj19_dVarYv_uw : 40|16@1+ (0.001953125,0) [0|127.998046875] ""  MPC3
 SG_ TrajPointACCObj19_dxv_sw : 56|16@1- (0.0078125,0) [-256|255.9921875] ""  MPC3
 SG_ TrajPointACCObj19_dyv_sw : 72|16@1- (0.0078125,0) [-256|255.9921875] ""  MPC3
 SG_ TrajPointACCObj19_wExistProb_ub : 88|8@1+ (0.00390625,0) [0|0.99609375] ""  MPC3
 SG_ TrajPointACCObj19_timestamp : 96|16@1+ (0.00048828125,0) [0|32] ""  MPC3

BO_ 336 TrajPointACCObj20: 16 RadarFrontCenter
 SG_ TrajPointACCObj20_CRC : 0|8@1+ (1,0) [0|255] ""  MPC3
 SG_ TrajPointACCObj20_MsgCtr : 8|4@1+ (1,0) [0|15] ""  MPC3
 SG_ TrajPointACCObj20_blockCtr : 12|4@1+ (1,0) [0|15] ""  MPC3
 SG_ TrajPointACCObj20_Valid_b : 17|1@1+ (1,0) [0|1] ""  MPC3
 SG_ TrajPointACCObj20_Drive_b : 18|1@1+ (1,0) [0|1] ""  MPC3
 SG_ TrajPointACCObj20_Stand_b : 19|1@1+ (1,0) [0|1] ""  MPC3
 SG_ TrajPointACCObj20_InvDir_b : 21|1@1+ (1,0) [0|1] ""  MPC3
 SG_ TrajPointACCObj20_Stopped_b : 22|1@1+ (1,0) [0|1] ""  MPC3
 SG_ TrajPointACCObj20_TrajEnd_b : 23|1@1+ (1,0) [0|1] ""  MPC3
 SG_ TrajPointACCObj20_dVarXv_uw : 24|16@1+ (0.001953125,0) [0|127.998046875] ""  MPC3
 SG_ TrajPointACCObj20_dVarYv_uw : 40|16@1+ (0.001953125,0) [0|127.998046875] ""  MPC3
 SG_ TrajPointACCObj20_dxv_sw : 56|16@1- (0.0078125,0) [-256|255.9921875] ""  MPC3
 SG_ TrajPointACCObj20_dyv_sw : 72|16@1- (0.0078125,0) [-256|255.9921875] ""  MPC3
 SG_ TrajPointACCObj20_wExistProb_ub : 88|8@1+ (0.00390625,0) [0|0.99609375] ""  MPC3
 SG_ TrajPointACCObj20_timestamp : 96|16@1+ (0.00048828125,0) [0|32] ""  MPC3

BO_ 337 TrajPointACCObj21: 16 RadarFrontCenter
 SG_ TrajPointACCObj21_CRC : 0|8@1+ (1,0) [0|255] ""  MPC3
 SG_ TrajPointACCObj21_MsgCtr : 8|4@1+ (1,0) [0|15] ""  MPC3
 SG_ TrajPointACCObj21_blockCtr : 12|4@1+ (1,0) [0|15] ""  MPC3
 SG_ TrajPointACCObj21_Valid_b : 17|1@1+ (1,0) [0|1] ""  MPC3
 SG_ TrajPointACCObj21_Drive_b : 18|1@1+ (1,0) [0|1] ""  MPC3
 SG_ TrajPointACCObj21_Stand_b : 19|1@1+ (1,0) [0|1] ""  MPC3
 SG_ TrajPointACCObj21_InvDir_b : 21|1@1+ (1,0) [0|1] ""  MPC3
 SG_ TrajPointACCObj21_Stopped_b : 22|1@1+ (1,0) [0|1] ""  MPC3
 SG_ TrajPointACCObj21_TrajEnd_b : 23|1@1+ (1,0) [0|1] ""  MPC3
 SG_ TrajPointACCObj21_dVarXv_uw : 24|16@1+ (0.001953125,0) [0|127.998046875] ""  MPC3
 SG_ TrajPointACCObj21_dVarYv_uw : 40|16@1+ (0.001953125,0) [0|127.998046875] ""  MPC3
 SG_ TrajPointACCObj21_dxv_sw : 56|16@1- (0.0078125,0) [-256|255.9921875] ""  MPC3
 SG_ TrajPointACCObj21_dyv_sw : 72|16@1- (0.0078125,0) [-256|255.9921875] ""  MPC3
 SG_ TrajPointACCObj21_wExistProb_ub : 88|8@1+ (0.00390625,0) [0|0.99609375] ""  MPC3
 SG_ TrajPointACCObj21_timestamp : 96|16@1+ (0.00048828125,0) [0|32] ""  MPC3

BO_ 338 TrajPointACCObj22: 16 RadarFrontCenter
 SG_ TrajPointACCObj22_CRC : 0|8@1+ (1,0) [0|255] ""  MPC3
 SG_ TrajPointACCObj22_MsgCtr : 8|4@1+ (1,0) [0|15] ""  MPC3
 SG_ TrajPointACCObj22_blockCtr : 12|4@1+ (1,0) [0|15] ""  MPC3
 SG_ TrajPointACCObj22_Valid_b : 17|1@1+ (1,0) [0|1] ""  MPC3
 SG_ TrajPointACCObj22_Drive_b : 18|1@1+ (1,0) [0|1] ""  MPC3
 SG_ TrajPointACCObj22_Stand_b : 19|1@1+ (1,0) [0|1] ""  MPC3
 SG_ TrajPointACCObj22_InvDir_b : 21|1@1+ (1,0) [0|1] ""  MPC3
 SG_ TrajPointACCObj22_Stopped_b : 22|1@1+ (1,0) [0|1] ""  MPC3
 SG_ TrajPointACCObj22_TrajEnd_b : 23|1@1+ (1,0) [0|1] ""  MPC3
 SG_ TrajPointACCObj22_dVarXv_uw : 24|16@1+ (0.001953125,0) [0|127.998046875] ""  MPC3
 SG_ TrajPointACCObj22_dVarYv_uw : 40|16@1+ (0.001953125,0) [0|127.998046875] ""  MPC3
 SG_ TrajPointACCObj22_dxv_sw : 56|16@1- (0.0078125,0) [-256|255.9921875] ""  MPC3
 SG_ TrajPointACCObj22_dyv_sw : 72|16@1- (0.0078125,0) [-256|255.9921875] ""  MPC3
 SG_ TrajPointACCObj22_wExistProb_ub : 88|8@1+ (0.00390625,0) [0|0.99609375] ""  MPC3
 SG_ TrajPointACCObj22_timestamp : 96|16@1+ (0.00048828125,0) [0|32] ""  MPC3

BO_ 339 TrajPointACCObj23: 16 RadarFrontCenter
 SG_ TrajPointACCObj23_CRC : 0|8@1+ (1,0) [0|255] ""  MPC3
 SG_ TrajPointACCObj23_MsgCtr : 8|4@1+ (1,0) [0|15] ""  MPC3
 SG_ TrajPointACCObj23_blockCtr : 12|4@1+ (1,0) [0|15] ""  MPC3
 SG_ TrajPointACCObj23_Valid_b : 17|1@1+ (1,0) [0|1] ""  MPC3
 SG_ TrajPointACCObj23_Drive_b : 18|1@1+ (1,0) [0|1] ""  MPC3
 SG_ TrajPointACCObj23_Stand_b : 19|1@1+ (1,0) [0|1] ""  MPC3
 SG_ TrajPointACCObj23_InvDir_b : 21|1@1+ (1,0) [0|1] ""  MPC3
 SG_ TrajPointACCObj23_Stopped_b : 22|1@1+ (1,0) [0|1] ""  MPC3
 SG_ TrajPointACCObj23_TrajEnd_b : 23|1@1+ (1,0) [0|1] ""  MPC3
 SG_ TrajPointACCObj23_dVarXv_uw : 24|16@1+ (0.001953125,0) [0|127.998046875] ""  MPC3
 SG_ TrajPointACCObj23_dVarYv_uw : 40|16@1+ (0.001953125,0) [0|127.998046875] ""  MPC3
 SG_ TrajPointACCObj23_dxv_sw : 56|16@1- (0.0078125,0) [-256|255.9921875] ""  MPC3
 SG_ TrajPointACCObj23_dyv_sw : 72|16@1- (0.0078125,0) [-256|255.9921875] ""  MPC3
 SG_ TrajPointACCObj23_wExistProb_ub : 88|8@1+ (0.00390625,0) [0|0.99609375] ""  MPC3
 SG_ TrajPointACCObj23_timestamp : 96|16@1+ (0.00048828125,0) [0|32] ""  MPC3

BO_ 340 ACCObjInfo: 16 RadarFrontCenter
 SG_ ACCObjInfo_CRC : 0|8@1+ (1,0) [0|255] ""  MPC3
 SG_ ACCObjInfo_MsgCtr : 8|4@1+ (1,0) [0|15] ""  MPC3
 SG_ ACCObjInfo_vxv_sw : 112|16@1- (0.00390625,0) [-128|127.99609375] ""  MPC3
 SG_ ACCObjInfo_blockCtr : 12|4@1+ (1,0) [0|15] ""  MPC3
 SG_ ACCObjInfo_dWidth_sw : 16|16@1- (0.0078125,0) [-256|255.9921875] ""  MPC3
 SG_ ACCObjInfo_dxv_sw : 32|16@1- (0.0078125,0) [-256|255.9921875] ""  MPC3
 SG_ ACCObjInfo_dyv_sw : 48|16@1- (0.0078125,0) [-256|255.9921875] ""  MPC3
 SG_ ACCObjInfo_Handle_ub : 64|8@1+ (1,0) [0|255] ""  MPC3
 SG_ ACCObjInfo_RFF_ub : 72|8@1+ (1,0) [0|255] ""  MPC3
 SG_ ACCObjInfo_timestamp : 80|32@1+ (1.52588E-005,0) [0|65535.9999847412] ""  MPC3

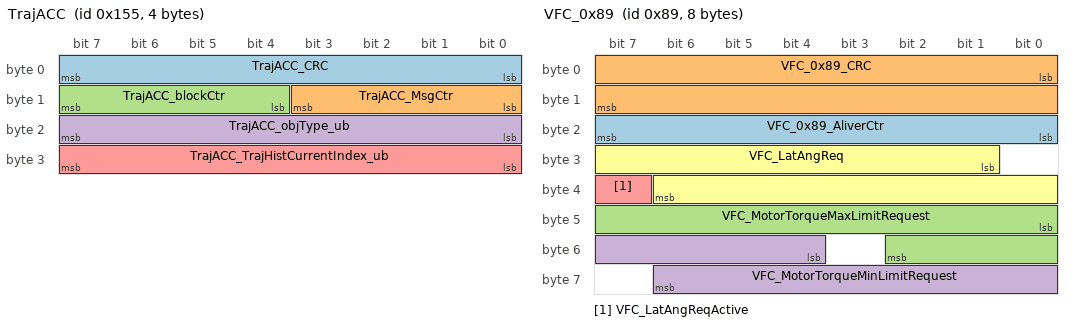
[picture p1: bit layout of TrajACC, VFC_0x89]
BO_ 341 TrajACC: 4 RadarFrontCenter
 SG_ TrajACC_CRC : 0|8@1+ (1,0) [0|255] ""  MPC3
 SG_ TrajACC_MsgCtr : 8|4@1+ (1,0) [0|15] ""  MPC3
 SG_ TrajACC_blockCtr : 12|4@1+ (1,0) [0|15] ""  MPC3
 SG_ TrajACC_objType_ub : 16|8@1+ (1,0) [0|255] ""  MPC3
 SG_ TrajACC_TrajHistCurrentIndex_ub : 24|8@1+ (1,0) [0|255] ""  MPC3

BO_ 137 VFC_0x89: 8 MPC3
 SG_ VFC_0x89_AliverCtr : 16|8@1+ (1,0) [0|255] ""  RadarFrontCenter
 SG_ VFC_0x89_CRC : 0|16@1+ (1,0) [0|65535] ""  RadarFrontCenter
 SG_ VFC_MotorTorqueMaxLimitRequest : 40|11@1+ (0.02,-20.48) [-20.48|20.46] "Nm"  RadarFrontCenter
 SG_ VFC_MotorTorqueMinLimitRequest : 52|11@1+ (0.02,-20.48) [-20.48|20.46] "Nm"  RadarFrontCenter
 SG_ VFC_LatAngReqActive : 39|1@1+ (1,0) [0|1] ""  RadarFrontCenter
 SG_ VFC_LatAngReq : 25|14@1+ (0.1,-720) [-720|720] "degree"  RadarFrontCenter

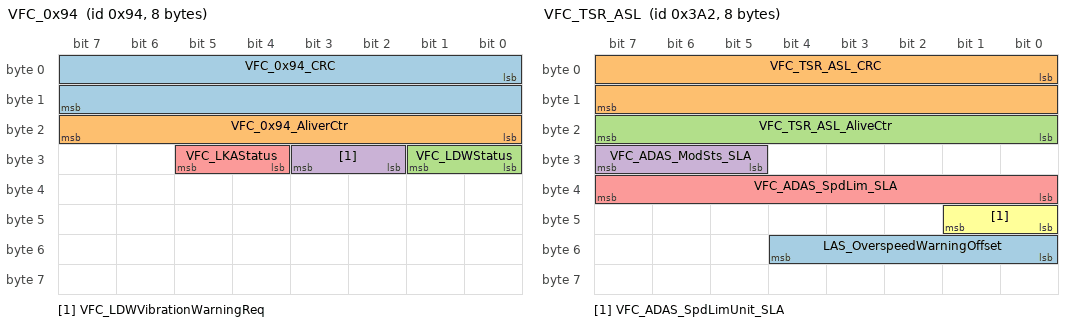
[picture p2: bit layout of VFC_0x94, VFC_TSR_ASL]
BO_ 148 VFC_0x94: 8 MPC3
 SG_ VFC_0x94_CRC : 0|16@1+ (1,0) [0|65535] ""  RadarFrontCenter
 SG_ VFC_0x94_AliverCtr : 16|8@1+ (1,0) [0|255] ""  RadarFrontCenter
 SG_ VFC_LDWStatus : 24|2@1+ (1,0) [0|3] ""  RadarFrontCenter
 SG_ VFC_LDWVibrationWarningReq : 26|2@1+ (1,0) [0|3] ""  RadarFrontCenter
 SG_ VFC_LKAStatus : 28|2@1+ (1,0) [0|3] ""  RadarFrontCenter

BO_ 145 VFC_0x91: 16 MPC3
 SG_ Selflearning_angle : 72|11@1+ (0.01,-10.25) [-10.25|10.22] "degree"  RadarFrontCenter
 SG_ Selflearning_status : 64|2@1+ (1,0) [0|3] ""  RadarFrontCenter
 SG_ VFC_0x91_CRC : 0|16@1+ (1,0) [0|65535] ""  RadarFrontCenter
 SG_ VFC_0x91_AliverCtr : 16|8@1+ (1,0) [0|255] ""  RadarFrontCenter
 SG_ VFC_DriverWindowControl : 32|7@1+ (1,0) [0|100] ""  RadarFrontCenter
 SG_ VFC_ToTargetLatDistance : 56|8@1+ (0.1,-10) [-10|10] ""  RadarFrontCenter
 SG_ VFC_LLaneDistanceFusion : 24|7@1+ (0.05,-1) [-1|5] "m"  RadarFrontCenter
 SG_ VFC_SunroofControl : 47|8@1+ (1,0) [0|255] ""  RadarFrontCenter
 SG_ VFC_RLaneDistanceFusion : 40|7@1+ (0.05,-1) [-1|5] "m"  RadarFrontCenter

BO_ 146 VFC_0x92: 32 MPC3
 SG_ VFC_EmergencyLightingRequest : 144|2@1+ (1,0) [0|3] ""  RadarFrontCenter
 SG_ VFC_ELKActiveSide : 152|2@1+ (1,0) [0|3] ""  RadarFrontCenter
 SG_ VFC_0x92_CRC : 0|16@1+ (1,0) [0|65535] ""  RadarFrontCenter
 SG_ VFC_0x92_AliverCtr : 16|8@1+ (1,0) [0|255] ""  RadarFrontCenter
 SG_ VFC_LASModeSelectionStatus : 61|3@1+ (1,0) [0|7] ""  RadarFrontCenter
 SG_ VFC_LatTakeoverReq : 88|2@1+ (1,0) [0|3] ""  RadarFrontCenter
 SG_ VFC_HandsOnReq : 39|3@1+ (1,0) [0|7] ""  RadarFrontCenter
 SG_ VFC_RLaneMarkerType : 103|3@1+ (1,0) [0|7] ""  RadarFrontCenter
 SG_ VFC_LaneChangeStatus : 59|2@1+ (1,0) [0|3] ""  RadarFrontCenter
 SG_ VFC_RoadCurvatureFar : 113|7@1+ (0.0005,-0.03) [-0.03|0.03] "1/m"  RadarFrontCenter
 SG_ VFC_RRLaneDistance : 129|6@1+ (0.2,0) [0|12] "m"  RadarFrontCenter
 SG_ VFC_IACCHWAMode : 51|3@1+ (1,0) [0|7] ""  RadarFrontCenter
 SG_ VFC_LASWarningModeSelectionSts : 64|3@1+ (1,0) [0|7] ""  RadarFrontCenter
 SG_ VFC_DriverHandsOffStatus : 24|2@1+ (1,0) [0|3] ""  RadarFrontCenter
 SG_ VFC_IACCHWATextInfoForDriver : 54|5@1+ (1,0) [0|31] ""  RadarFrontCenter
 SG_ VFC_LDWShakeLevStatus : 90|2@1+ (1,0) [0|3] ""  RadarFrontCenter
 SG_ VFC_IACCHWAEnable : 50|1@1+ (1,0) [0|1] ""  RadarFrontCenter
 SG_ VFC_HostLaneLeftStatus : 42|4@1+ (1,0) [0|15] ""  RadarFrontCenter
 SG_ VFC_ELKInterventionMode : 27|2@1+ (1,0) [0|3] ""  RadarFrontCenter
 SG_ VFC_ELKMode : 29|3@1+ (1,0) [0|7] ""  RadarFrontCenter
 SG_ VFC_HostLaneRightStatus : 46|4@1+ (1,0) [0|15] ""  RadarFrontCenter
 SG_ VFC_TargetBasedLateralControl : 135|2@1+ (1,0) [0|3] ""  RadarFrontCenter
 SG_ VFC_HandsoffFuncStatus : 32|3@1+ (1,0) [0|7] ""  RadarFrontCenter
 SG_ VFC_HandsoffFuncTextinfo : 35|4@1+ (1,0) [0|15] ""  RadarFrontCenter
 SG_ VFC_LLaneMarkerType : 92|3@1+ (1,0) [0|7] ""  RadarFrontCenter
 SG_ VFC_ELKEnableStatus : 26|1@1+ (1,0) [0|1] ""  RadarFrontCenter
 SG_ VFC_LLLaneDistance : 97|6@1+ (0.2,0) [0|12] "m"  RadarFrontCenter
 SG_ VFC_LatPathDY : 67|10@1- (0.01,0) [-5|5] "m"  RadarFrontCenter
 SG_ VFC_RoadCurvature : 106|7@1+ (0.0005,-0.03) [-0.03|0.03] "1/m"  RadarFrontCenter
 SG_ VFC_LLLaneDetection : 95|2@1+ (1,0) [0|3] ""  RadarFrontCenter
 SG_ VFC_LatPathHeadingAngle : 77|11@1- (0.1,0) [-90|90] "degree"  RadarFrontCenter
 SG_ VFC_Voiceinfo : 137|5@1+ (1,0) [0|31] ""  RadarFrontCenter
 SG_ VFC_RRLaneDetection : 127|2@1+ (1,0) [0|3] ""  RadarFrontCenter
 SG_ VFC_RoadCurvatureNear : 120|7@1+ (0.0005,-0.03) [-0.03|0.03] "1/m"  RadarFrontCenter

BO_ 147 VFC_0x93: 16 MPC3
 SG_ VFC_0x93_CRC : 0|16@1+ (1,0) [0|65535] ""  RadarFrontCenter
 SG_ VFC_0x93_AliverCtr : 16|8@1+ (1,0) [0|255] ""  RadarFrontCenter
 SG_ VFC_LaneQuality : 62|6@1+ (0.015625,0) [0|0.984375] ""  RadarFrontCenter
 SG_ VFC_LaneEquationC1 : 24|12@1+ (0.00048828125,-1) [-1|0.9990234375] "red"  RadarFrontCenter
 SG_ VFC_LaneEquationC2 : 36|12@1+ (1.52587890625E-005,-0.0312347412109375) [-0.0312347412109375|0.0312347412109375] ""  RadarFrontCenter
 SG_ VFC_LaneEquationStatus : 60|2@1+ (1,0) [0|3] ""  RadarFrontCenter
 SG_ VFC_LaneEquationC3 : 48|12@1+ (4.76837158203125E-007,-0.000976085662841797) [-0.000976085662841797|0.000976085662841797] ""  RadarFrontCenter

BO_ 930 VFC_TSR_ASL: 8 MPC3
 SG_ LAS_OverspeedWarningOffset : 48|5@1+ (1,-10) [-10|10] "km/h"  RadarFrontCenter
 SG_ VFC_TSR_ASL_CRC : 0|16@1+ (1,0) [0|65535] ""  RadarFrontCenter,DASy
 SG_ VFC_TSR_ASL_AliveCtr : 16|8@1+ (1,0) [0|255] ""  RadarFrontCenter,DASy
 SG_ VFC_ADAS_ModSts_SLA : 29|3@1+ (1,0) [0|7] ""  RadarFrontCenter,DASy
 SG_ VFC_ADAS_SpdLim_SLA : 32|8@1+ (1,0) [0|255] ""  RadarFrontCenter,DASy
 SG_ VFC_ADAS_SpdLimUnit_SLA : 40|2@1+ (1,0) [0|3] ""  RadarFrontCenter,DASy

BO_ 2281601536 Dev_Video_SyncVisor_TX: 8 MPC3
 SG_ ImgFrameCounter : 0|32@1+ (1,0) [0|4294967295] ""  RadarFrontCenter,DASy
 SG_ ImgTimeDelay : 32|32@1+ (1,0) [0|4294967295] ""  RadarFrontCenter,DASy

CM_ SG_ 210 VFC_Obj17A_CRC "CRC - Autosar E2E Profile 5";
CM_ SG_ 210 VFC_Obj17A_DyStdDev "Standard deviation of Object position in lateral direction";
CM_ SG_ 210 VFC_Obj17A_DxStdDev "Standard deviation of Object position in longitudinal direction";
CM_ SG_ 210 VFC_Obj17A_VxStdDev "Standard deviation of Object velocity in longitudinal direction";
CM_ SG_ 210 VFC_Obj17A_ExistProb "Object existence probability";
CM_ SG_ 210 VFC_Obj17A_VyStdDev "Standard deviation of Object velocity in lateral direction";
CM_ SG_ 210 VFC_Obj17A_TypeProb "Probability of the classified object type";
CM_ SG_ 210 VFC_Obj17A_AxStdDev "Standard deviation of Object acceleration in longitudinal direction";
CM_ SG_ 210 VFC_Obj17A_AyStdDev "Standard deviation of Object acceleration in lateral direction";
CM_ SG_ 210 VFC_Obj17A_AliveCtr "Alive counter - Autosar E2E Profile 5";
CM_ SG_ 210 VFC_Obj17A_PhiLeft "ACCS Viewing Angle of left object edge(dimensionless)";
CM_ SG_ 210 VFC_Obj17A_ClassifiedView "The classified view of object to be used in connection with Heading angle";
CM_ SG_ 210 VFC_Obj17A_Length "Length of the object";
CM_ SG_ 210 VFC_Obj17A_WidthStdDev "Standard deviation of object width";
CM_ SG_ 210 VFC_Obj17A_Height "Height of the object";
CM_ SG_ 210 VFC_Obj17A_HeightStdDev "Standard deviation of object height";
CM_ SG_ 210 VFC_Obj17A_PhiLeftStdDev "Standard deviation of the ACCS angle of left object(dimensionless)";
CM_ SG_ 210 VFC_Obj17A_HeadingStdDev "Standard deviation of object Heading angle";
CM_ SG_ 210 VFC_Obj17A_Measured "Indicator if the object detected is measured or predicted.";
CM_ SG_ 210 VFC_Obj17A_Heading "Heading angle of the object";
CM_ SG_ 210 VFC_Obj17A_LengthStdDev "Standard deviation of object length";
CM_ SG_ 210 VFC_Obj17A_BlockCtr "Protocol-Signal: Block-Counter";
CM_ SG_ 210 VFC_Obj17A_PhiMid "Viewing angle of the ACCS middle of the object(dimensionless)";
CM_ SG_ 210 VFC_Obj17A_Width "Width of the object";
CM_ SG_ 210 VFC_Obj17A_PhiMidStdDev "Standard deviation of the ACCS middle angle of object(dimensionless)";
CM_ SG_ 210 VFC_Obj17A_PhiRight "ACCS Viewing Angle of right object edge(dimensionless)";
CM_ SG_ 210 VFC_Obj17A_VisibleView "The visible view of the detectd object";
CM_ SG_ 210 VFC_Obj17A_PhiRightStdDev "Standard deviation of the ACCS angle of right object(dimensionless)";
CM_ SG_ 210 VFC_Obj17A_PhiLeftVel "Velocity of the ACCS viewing angle of the left edge";
CM_ SG_ 210 VFC_Obj17A_PhiRightVel "Velocity of the ACCS viewing angle of the right edge";
CM_ SG_ 210 VFC_Obj17A_ProtOrderIndex "Protocol-Signal: Index to ensure same order in Tx and Rx of the objects";
CM_ SG_ 210 VFC_Obj17A_PhiRightVelStdDev "Standard deviation of ACCS viewing angle velocity of right object edge from ego vehicle related to camera";
CM_ SG_ 210 VFC_Obj17A_PhiLeftVelStdDev "Standard deviation of ACCS viewing angle velocity of left object edge from ego vehicle related to camera";
CM_ SG_ 210 VFC_Obj17A_PhiTop "ACCS Viewing angle of the top of the object(dimensionless)";
CM_ SG_ 210 VFC_Obj17A_PhiBottom "ACCS Viewing angle of the bottom of the object(dimensionless)";
CM_ SG_ 210 VFC_Obj17A_PhiTopStdDev "Standard deviation  of the ACCS top angle of object(dimensionless)";
CM_ SG_ 210 VFC_Obj17A_HeadOrientation "The orientation of the head of cyclists or pedestrians that are detected.";
CM_ SG_ 210 VFC_Obj17A_Type "Classification of the object";
CM_ SG_ 210 VFC_Obj17A_Ax "Object Acceleration in longitudinal direction";
CM_ SG_ 210 VFC_Obj17A_PhiBottomStdDev "Standard deviation of the ACCS bottom angle of object(dimensionless)";
CM_ SG_ 210 VFC_Obj17A_NormVx "Normalised object velocity in longitudinal direction.";
CM_ SG_ 210 VFC_Obj17A_NormAx "Normalised object acceleration in longitudinal direction.";
CM_ SG_ 210 VFC_Obj17A_NormAxStdDev "Standard deviation of Normalized Object Acceleration in longitudinal direction";
CM_ SG_ 210 VFC_Obj17A_ProbMovingLat "Probability of object moving laterally";
CM_ SG_ 210 VFC_Obj17A_ID "Unique Object ID";
CM_ SG_ 210 VFC_Obj17A_NormVxStdDev "Standard deviation of Normalized Object Velocity in longitudinal direction";
CM_ SG_ 210 VFC_Obj17A_ProbMovingLong "Probability of object moving longitudinally";
CM_ SG_ 210 VFC_Obj17A_Vx "Object Velocity in longitudinal direction";
CM_ SG_ 210 VFC_Obj17A_Dx "Object Position in longitudinal direction";
CM_ SG_ 210 VFC_Obj17A_Dy "Object Position in lateral direction";
CM_ SG_ 210 VFC_Obj17A_Vy "Object Velocity in lateral direction";
CM_ SG_ 210 VFC_Obj17A_Ay "Object Acceleration in lateral direction";
CM_ SG_ 211 VFC_Obj17B_CRC "CRC - Autosar E2E Profile 5";
CM_ SG_ 211 VFC_Obj17B_TTIPC "Inverse TTI";
CM_ SG_ 211 VFC_Obj17B_TTIPC_StdDev "Inverse TTI standard deviation";
CM_ SG_ 211 VFC_Obj17B_AliveCtr "Alive counter - Autosar E2E Profile 5";
CM_ SG_ 211 VFC_Obj17B_BlockCtr "Protocol-Signal: Block Counter";
CM_ SG_ 211 VFC_Obj17B_ScaleChange "A scale change of of the detected object";
CM_ SG_ 211 VFC_Obj17B_ScaleChngStdDev "Standard deviation of object scale change";
CM_ SG_ 211 VFC_Obj17B_LineEdgeRightEgo "ObjLineEdgeAngle refers to the line which limits the host vehicle lane on the right side";
CM_ SG_ 211 VFC_Obj17B_LineEdgeLeftEgo "ObjLineEdgeAngle refers to the line which limits the host vehicle lane on the left side";
CM_ SG_ 211 VFC_Obj17B_CompletelyInImg "indicator if the object is completely measrued in the image";
CM_ SG_ 211 VFC_Obj17B_DirIndicator "The detected direction indicator lights";
CM_ SG_ 211 VFC_Obj17B_LineEdgeAngle "Angle between the video object's edge and the lane marking";
CM_ SG_ 211 VFC_Obj17B_BrakeLight "The number of detected lights. More confident if more lights are detected.";
CM_ SG_ 211 VFC_Obj17B_MeasSource "Bitmask for the measurement programs from which this object originates";
CM_ SG_ 211 VFC_Obj17B_AngLongitude "angular velocity with regarding to longitudinal direction";
CM_ SG_ 211 VFC_Obj17B_Reliab "Bitmask that indicates the algorithmic paths that have detected this object
NOT_RELIABLE=0 (Bit5==0)";
CM_ SG_ 212 VFC_Obj18A_CRC "CRC - Autosar E2E Profile 5";
CM_ SG_ 212 VFC_Obj18A_DyStdDev "Standard deviation of Object position in lateral direction";
CM_ SG_ 212 VFC_Obj18A_DxStdDev "Standard deviation of Object position in longitudinal direction";
CM_ SG_ 212 VFC_Obj18A_VxStdDev "Standard deviation of Object velocity in longitudinal direction";
CM_ SG_ 212 VFC_Obj18A_ExistProb "Object existence probability";
CM_ SG_ 212 VFC_Obj18A_VyStdDev "Standard deviation of Object velocity in lateral direction";
CM_ SG_ 212 VFC_Obj18A_TypeProb "Probability of the classified object type";
CM_ SG_ 212 VFC_Obj18A_AxStdDev "Standard deviation of Object acceleration in longitudinal direction";
CM_ SG_ 212 VFC_Obj18A_AyStdDev "Standard deviation of Object acceleration in lateral direction";
CM_ SG_ 212 VFC_Obj18A_AliveCtr "Alive counter - Autosar E2E Profile 5";
CM_ SG_ 212 VFC_Obj18A_PhiLeft "ACCS Viewing Angle of left object edge(dimensionless)";
CM_ SG_ 212 VFC_Obj18A_ClassifiedView "The classified view of object to be used in connection with Heading angle";
CM_ SG_ 212 VFC_Obj18A_Length "Length of the object";
CM_ SG_ 212 VFC_Obj18A_WidthStdDev "Standard deviation of object width";
CM_ SG_ 212 VFC_Obj18A_Height "Height of the object";
CM_ SG_ 212 VFC_Obj18A_HeightStdDev "Standard deviation of object height";
CM_ SG_ 212 VFC_Obj18A_PhiLeftStdDev "Standard deviation of the ACCS angle of left object(dimensionless)";
CM_ SG_ 212 VFC_Obj18A_HeadingStdDev "Standard deviation of object Heading angle";
CM_ SG_ 212 VFC_Obj18A_Measured "Indicator if the object detected is measured or predicted.";
CM_ SG_ 212 VFC_Obj18A_Heading "Heading angle of the object";
CM_ SG_ 212 VFC_Obj18A_LengthStdDev "Standard deviation of object length";
CM_ SG_ 212 VFC_Obj18A_BlockCtr "Protocol-Signal: Block-Counter";
CM_ SG_ 212 VFC_Obj18A_PhiMid "Viewing angle of the ACCS middle of the object(dimensionless)";
CM_ SG_ 212 VFC_Obj18A_Width "Width of the object";
CM_ SG_ 212 VFC_Obj18A_PhiMidStdDev "Standard deviation of the ACCS middle angle of object(dimensionless)";
CM_ SG_ 212 VFC_Obj18A_PhiRight "ACCS Viewing Angle of right object edge(dimensionless)";
CM_ SG_ 212 VFC_Obj18A_VisibleView "The visible view of the detectd object";
CM_ SG_ 212 VFC_Obj18A_PhiRightStdDev "Standard deviation of the ACCS angle of right object(dimensionless)";
CM_ SG_ 212 VFC_Obj18A_PhiLeftVel "Velocity of the ACCS viewing angle of the left edge";
CM_ SG_ 212 VFC_Obj18A_PhiRightVel "Velocity of the ACCS viewing angle of the right edge";
CM_ SG_ 212 VFC_Obj18A_ProtOrderIndex "Protocol-Signal: Index to ensure same order in Tx and Rx of the objects";
CM_ SG_ 212 VFC_Obj18A_PhiRightVelStdDev "Standard deviation of ACCS viewing angle velocity of right object edge from ego vehicle related to camera";
CM_ SG_ 212 VFC_Obj18A_PhiLeftVelStdDev "Standard deviation of ACCS viewing angle velocity of left object edge from ego vehicle related to camera";
CM_ SG_ 212 VFC_Obj18A_PhiTop "ACCS Viewing angle of the top of the object(dimensionless)";
CM_ SG_ 212 VFC_Obj18A_PhiBottom "ACCS Viewing angle of the bottom of the object(dimensionless)";
CM_ SG_ 212 VFC_Obj18A_PhiTopStdDev "Standard deviation  of the ACCS top angle of object(dimensionless)";
CM_ SG_ 212 VFC_Obj18A_HeadOrientation "The orientation of the head of cyclists or pedestrians that are detected.";
CM_ SG_ 212 VFC_Obj18A_Type "Classification of the object";
CM_ SG_ 212 VFC_Obj18A_Ax "Object Acceleration in longitudinal direction";
CM_ SG_ 212 VFC_Obj18A_PhiBottomStdDev "Standard deviation of the ACCS bottom angle of object(dimensionless)";
CM_ SG_ 212 VFC_Obj18A_NormVx "Normalised object velocity in longitudinal direction.";
CM_ SG_ 212 VFC_Obj18A_NormAx "Normalised object acceleration in longitudinal direction.";
CM_ SG_ 212 VFC_Obj18A_NormAxStdDev "Standard deviation of Normalized Object Acceleration in longitudinal direction";
CM_ SG_ 212 VFC_Obj18A_ProbMovingLat "Probability of object moving laterally";
CM_ SG_ 212 VFC_Obj18A_ID "Unique Object ID";
CM_ SG_ 212 VFC_Obj18A_NormVxStdDev "Standard deviation of Normalized Object Velocity in longitudinal direction";
CM_ SG_ 212 VFC_Obj18A_ProbMovingLong "Probability of object moving longitudinally";
CM_ SG_ 212 VFC_Obj18A_Vx "Object Velocity in longitudinal direction";
CM_ SG_ 212 VFC_Obj18A_Dx "Object Position in longitudinal direction";
CM_ SG_ 212 VFC_Obj18A_Dy "Object Position in lateral direction";
CM_ SG_ 212 VFC_Obj18A_Vy "Object Velocity in lateral direction";
CM_ SG_ 212 VFC_Obj18A_Ay "Object Acceleration in lateral direction";
CM_ SG_ 213 VFC_Obj18B_CRC "CRC - Autosar E2E Profile 5";
CM_ SG_ 213 VFC_Obj18B_TTIPC "Inverse TTI";
CM_ SG_ 213 VFC_Obj18B_TTIPC_StdDev "Inverse TTI standard deviation";
CM_ SG_ 213 VFC_Obj18B_AliveCtr "Alive counter - Autosar E2E Profile 5";
CM_ SG_ 213 VFC_Obj18B_BlockCtr "Protocol-Signal: Block Counter";
CM_ SG_ 213 VFC_Obj18B_ScaleChange "A scale change of of the detected object";
CM_ SG_ 213 VFC_Obj18B_ScaleChngStdDev "Standard deviation of object scale change";
CM_ SG_ 213 VFC_Obj18B_LineEdgeRightEgo "ObjLineEdgeAngle refers to the line which limits the host vehicle lane on the right side";
CM_ SG_ 213 VFC_Obj18B_LineEdgeLeftEgo "ObjLineEdgeAngle refers to the line which limits the host vehicle lane on the left side";
CM_ SG_ 213 VFC_Obj18B_CompletelyInImg "indicator if the object is completely measrued in the image";
CM_ SG_ 213 VFC_Obj18B_DirIndicator "The detected direction indicator lights";
CM_ SG_ 213 VFC_Obj18B_LineEdgeAngle "Angle between the video object's edge and the lane marking";
CM_ SG_ 213 VFC_Obj18B_BrakeLight "The number of detected lights. More confident if more lights are detected.";
CM_ SG_ 213 VFC_Obj18B_MeasSource "Bitmask for the measurement programs from which this object originates";
CM_ SG_ 213 VFC_Obj18B_AngLongitude "angular velocity with regarding to longitudinal direction";
CM_ SG_ 213 VFC_Obj18B_Reliab "Bitmask that indicates the algorithmic paths that have detected this object
NOT_RELIABLE=0 (Bit5==0)";
CM_ SG_ 214 VFC_Obj19A_CRC "CRC - Autosar E2E Profile 5";
CM_ SG_ 214 VFC_Obj19A_DyStdDev "Standard deviation of Object position in lateral direction";
CM_ SG_ 214 VFC_Obj19A_DxStdDev "Standard deviation of Object position in longitudinal direction";
CM_ SG_ 214 VFC_Obj19A_VxStdDev "Standard deviation of Object velocity in longitudinal direction";
CM_ SG_ 214 VFC_Obj19A_ExistProb "Object existence probability";
CM_ SG_ 214 VFC_Obj19A_VyStdDev "Standard deviation of Object velocity in lateral direction";
CM_ SG_ 214 VFC_Obj19A_TypeProb "Probability of the classified object type";
CM_ SG_ 214 VFC_Obj19A_AxStdDev "Standard deviation of Object acceleration in longitudinal direction";
CM_ SG_ 214 VFC_Obj19A_AyStdDev "Standard deviation of Object acceleration in lateral direction";
CM_ SG_ 214 VFC_Obj19A_AliveCtr "Alive counter - Autosar E2E Profile 5";
CM_ SG_ 214 VFC_Obj19A_PhiLeft "ACCS Viewing Angle of left object edge(dimensionless)";
CM_ SG_ 214 VFC_Obj19A_ClassifiedView "The classified view of object to be used in connection with Heading angle";
CM_ SG_ 214 VFC_Obj19A_Length "Length of the object";
CM_ SG_ 214 VFC_Obj19A_WidthStdDev "Standard deviation of object width";
CM_ SG_ 214 VFC_Obj19A_Height "Height of the object";
CM_ SG_ 214 VFC_Obj19A_HeightStdDev "Standard deviation of object height";
CM_ SG_ 214 VFC_Obj19A_PhiLeftStdDev "Standard deviation of the ACCS angle of left object(dimensionless)";
CM_ SG_ 214 VFC_Obj19A_HeadingStdDev "Standard deviation of object Heading angle";
CM_ SG_ 214 VFC_Obj19A_Measured "Indicator if the object detected is measured or predicted.";
CM_ SG_ 214 VFC_Obj19A_Heading "Heading angle of the object";
CM_ SG_ 214 VFC_Obj19A_LengthStdDev "Standard deviation of object length";
CM_ SG_ 214 VFC_Obj19A_BlockCtr "Protocol-Signal: Block-Counter";
CM_ SG_ 214 VFC_Obj19A_PhiMid "Viewing angle of the ACCS middle of the object(dimensionless)";
CM_ SG_ 214 VFC_Obj19A_Width "Width of the object";
CM_ SG_ 214 VFC_Obj19A_PhiMidStdDev "Standard deviation of the ACCS middle angle of object(dimensionless)";
CM_ SG_ 214 VFC_Obj19A_PhiRight "ACCS Viewing Angle of right object edge(dimensionless)";
CM_ SG_ 214 VFC_Obj19A_VisibleView "The visible view of the detectd object";
CM_ SG_ 214 VFC_Obj19A_PhiRightStdDev "Standard deviation of the ACCS angle of right object(dimensionless)";
CM_ SG_ 214 VFC_Obj19A_PhiLeftVel "Velocity of the ACCS viewing angle of the left edge";
CM_ SG_ 214 VFC_Obj19A_PhiRightVel "Velocity of the ACCS viewing angle of the right edge";
CM_ SG_ 214 VFC_Obj19A_ProtOrderIndex "Protocol-Signal: Index to ensure same order in Tx and Rx of the objects";
CM_ SG_ 214 VFC_Obj19A_PhiRightVelStdDev "Standard deviation of ACCS viewing angle velocity of right object edge from ego vehicle related to camera";
CM_ SG_ 214 VFC_Obj19A_PhiLeftVelStdDev "Standard deviation of ACCS viewing angle velocity of left object edge from ego vehicle related to camera";
CM_ SG_ 214 VFC_Obj19A_PhiTop "ACCS Viewing angle of the top of the object(dimensionless)";
CM_ SG_ 214 VFC_Obj19A_PhiBottom "ACCS Viewing angle of the bottom of the object(dimensionless)";
CM_ SG_ 214 VFC_Obj19A_PhiTopStdDev "Standard deviation  of the ACCS top angle of object(dimensionless)";
CM_ SG_ 214 VFC_Obj19A_HeadOrientation "The orientation of the head of cyclists or pedestrians that are detected.";
CM_ SG_ 214 VFC_Obj19A_Type "Classification of the object";
CM_ SG_ 214 VFC_Obj19A_Ax "Object Acceleration in longitudinal direction";
CM_ SG_ 214 VFC_Obj19A_PhiBottomStdDev "Standard deviation of the ACCS bottom angle of object(dimensionless)";
CM_ SG_ 214 VFC_Obj19A_NormVx "Normalised object velocity in longitudinal direction.";
CM_ SG_ 214 VFC_Obj19A_NormAx "Normalised object acceleration in longitudinal direction.";
CM_ SG_ 214 VFC_Obj19A_NormAxStdDev "Standard deviation of Normalized Object Acceleration in longitudinal direction";
CM_ SG_ 214 VFC_Obj19A_ProbMovingLat "Probability of object moving laterally";
CM_ SG_ 214 VFC_Obj19A_ID "Unique Object ID";
CM_ SG_ 214 VFC_Obj19A_NormVxStdDev "Standard deviation of Normalized Object Velocity in longitudinal direction";
CM_ SG_ 214 VFC_Obj19A_ProbMovingLong "Probability of object moving longitudinally";
CM_ SG_ 214 VFC_Obj19A_Vx "Object Velocity in longitudinal direction";
CM_ SG_ 214 VFC_Obj19A_Dx "Object Position in longitudinal direction";
CM_ SG_ 214 VFC_Obj19A_Dy "Object Position in lateral direction";
CM_ SG_ 214 VFC_Obj19A_Vy "Object Velocity in lateral direction";
CM_ SG_ 214 VFC_Obj19A_Ay "Object Acceleration in lateral direction";
CM_ SG_ 215 VFC_Obj19B_CRC "CRC - Autosar E2E Profile 5";
CM_ SG_ 215 VFC_Obj19B_TTIPC "Inverse TTI";
CM_ SG_ 215 VFC_Obj19B_TTIPC_StdDev "Inverse TTI standard deviation";
CM_ SG_ 215 VFC_Obj19B_AliveCtr "Alive counter - Autosar E2E Profile 5";
CM_ SG_ 215 VFC_Obj19B_BlockCtr "Protocol-Signal: Block Counter";
CM_ SG_ 215 VFC_Obj19B_ScaleChange "A scale change of of the detected object";
CM_ SG_ 215 VFC_Obj19B_ScaleChngStdDev "Standard deviation of object scale change";
CM_ SG_ 215 VFC_Obj19B_LineEdgeRightEgo "ObjLineEdgeAngle refers to the line which limits the host vehicle lane on the right side";
CM_ SG_ 215 VFC_Obj19B_LineEdgeLeftEgo "ObjLineEdgeAngle refers to the line which limits the host vehicle lane on the left side";
CM_ SG_ 215 VFC_Obj19B_CompletelyInImg "indicator if the object is completely measrued in the image";
CM_ SG_ 215 VFC_Obj19B_DirIndicator "The detected direction indicator lights";
CM_ SG_ 215 VFC_Obj19B_LineEdgeAngle "Angle between the video object's edge and the lane marking";
CM_ SG_ 215 VFC_Obj19B_BrakeLight "The number of detected lights. More confident if more lights are detected.";
CM_ SG_ 215 VFC_Obj19B_MeasSource "Bitmask for the measurement programs from which this object originates";
CM_ SG_ 215 VFC_Obj19B_AngLongitude "angular velocity with regarding to longitudinal direction";
CM_ SG_ 215 VFC_Obj19B_Reliab "Bitmask that indicates the algorithmic paths that have detected this object
NOT_RELIABLE=0 (Bit5==0)";
CM_ SG_ 2147483903 ADAS_SYNC_FC_Type "Type=0x20 : TSync    Type=0x28 : TSync FUP";
CM_ SG_ 2147483903 ADAS_SYNC_FC_CRC "CRC";
CM_ SG_ 2147483903 ADAS_SYNC_FC_SequenceCnt "Sequence counter";
CM_ SG_ 2147483903 ADAS_SYNC_FC_TimeDomain "Time Domain";
CM_ SG_ 2147483903 ADAS_SYNC_FC_OVS "in FUP PDU
OVS = Overflow of seconds";
CM_ SG_ 2147483903 ADAS_SYNC_FC_SGW "in FUP PDU
SyncToGTM = 0
SyncToSubDomain = 1";
CM_ SG_ 2147483903 ADAS_SYNC_FC_Reserved "in FUP PDU
reserved, default =0";
CM_ SG_ 2147483903 ADAS_SYNC_FC_SyncTime "TSync: SyncTimeSec = 32 bit LSB of the 48 bits seconds part of the time
TSync FUP: SyncTimeNSec = 32 Bit time value in nanoseconds";
CM_ SG_ 256 FRS_Pri_ALOD_ControlType "The type of the automatic longitude driving";
CM_ SG_ 273 TIPLCourseInfo0_CRC "Check Sum";
CM_ SG_ 273 TIPLCourseInfo0_MsgCtr "Alive counter";
CM_ SG_ 273 TIPLCourseInfo0_blockCtr "Block counter for synchronisation";
CM_ SG_ 273 TIPLCourseInfo0_a0polynomCoef_sw "a0 coefficient of the polynom for the course segment";
CM_ SG_ 273 TIPLCourseInfo0_a1polynomCoef_sw "a1 coefficient of the polynom for the course segment";
CM_ SG_ 273 TIPLCourseInfo0_a2polynomCoef_sw "a2 coefficient of the polynom for the course segment";
CM_ SG_ 273 TIPLCourseInfo0_dLowerLimit_sw "dx value of the general lower limit for each course segment  in m";
CM_ SG_ 273 TIPLCourseInfo0_dUpperLimit_sw "dx value of the general upper limit for each course segment  in m";
CM_ SG_ 273 TIPLCourseInfo0_qCourseConform "Conformity of the estimated course for the course segment";
CM_ SG_ 274 TIPLCourseInfo1_CRC "Check Sum";
CM_ SG_ 274 TIPLCourseInfo1_MsgCtr "Alive counter";
CM_ SG_ 274 TIPLCourseInfo1_blockCtr "Block counter for synchronisation";
CM_ SG_ 274 TIPLCourseInfo1_a0polynomCoef_sw "a0 coefficient of the polynom for the course segment";
CM_ SG_ 274 TIPLCourseInfo1_a1polynomCoef_sw "a1 coefficient of the polynom for the course segment";
CM_ SG_ 274 TIPLCourseInfo1_a2polynomCoef_sw "a2 coefficient of the polynom for the course segment";
CM_ SG_ 274 TIPLCourseInfo1_dLowerLimit_sw "dx value of the general lower limit for each course segment  in m";
CM_ SG_ 274 TIPLCourseInfo1_dUpperLimit_sw "dx value of the general upper limit for each course segment  in m";
CM_ SG_ 274 TIPLCourseInfo1_qCourseConform "Conformity of the estimated course for the course segment";
CM_ SG_ 275 TIPLCourseInfo2_CRC "Check Sum";
CM_ SG_ 275 TIPLCourseInfo2_MsgCtr "Alive counter";
CM_ SG_ 275 TIPLCourseInfo2_blockCtr "Block counter for synchronisation";
CM_ SG_ 275 TIPLCourseInfo2_a0polynomCoef_sw "a0 coefficient of the polynom for the course segment";
CM_ SG_ 275 TIPLCourseInfo2_a1polynomCoef_sw "a1 coefficient of the polynom for the course segment";
CM_ SG_ 275 TIPLCourseInfo2_a2polynomCoef_sw "a2 coefficient of the polynom for the course segment";
CM_ SG_ 275 TIPLCourseInfo2_dLowerLimit_sw "dx value of the general lower limit for each course segment  in m";
CM_ SG_ 275 TIPLCourseInfo2_dUpperLimit_sw "dx value of the general upper limit for each course segment  in m";
CM_ SG_ 275 TIPLCourseInfo2_qCourseConform "Conformity of the estimated course for the course segment";
CM_ SG_ 276 TIPLCourseInfo3_CRC "Check Sum";
CM_ SG_ 276 TIPLCourseInfo3_MsgCtr "Alive counter";
CM_ SG_ 276 TIPLCourseInfo3_blockCtr "Block counter for synchronisation";
CM_ SG_ 276 TIPLCourseInfo3_a0polynomCoef_sw "a0 coefficient of the polynom for the course segment";
CM_ SG_ 276 TIPLCourseInfo3_a1polynomCoef_sw "a1 coefficient of the polynom for the course segment";
CM_ SG_ 276 TIPLCourseInfo3_a2polynomCoef_sw "a2 coefficient of the polynom for the course segment";
CM_ SG_ 276 TIPLCourseInfo3_dLowerLimit_sw "dx value of the general lower limit for each course segment  in m";
CM_ SG_ 276 TIPLCourseInfo3_dUpperLimit_sw "dx value of the general upper limit for each course segment  in m";
CM_ SG_ 276 TIPLCourseInfo3_qCourseConform "Conformity of the estimated course for the course segment";
CM_ SG_ 277 TIPLCourseInfo4_CRC "Check Sum";
CM_ SG_ 277 TIPLCourseInfo4_MsgCtr "Alive counter";
CM_ SG_ 277 TIPLCourseInfo4_blockCtr "Block counter for synchronisation";
CM_ SG_ 277 TIPLCourseInfo4_a0polynomCoef_sw "a0 coefficient of the polynom for the course segment";
CM_ SG_ 277 TIPLCourseInfo4_a1polynomCoef_sw "a1 coefficient of the polynom for the course segment";
CM_ SG_ 277 TIPLCourseInfo4_a2polynomCoef_sw "a2 coefficient of the polynom for the course segment";
CM_ SG_ 277 TIPLCourseInfo4_dLowerLimit_sw "dx value of the general lower limit for each course segment  in m";
CM_ SG_ 277 TIPLCourseInfo4_dUpperLimit_sw "dx value of the general upper limit for each course segment  in m";
CM_ SG_ 277 TIPLCourseInfo4_qCourseConform "Conformity of the estimated course for the course segment";
CM_ SG_ 278 TIPLLaneInfo0_CRC "Check Sum";
CM_ SG_ 278 TIPLLaneInfo0_MsgCtr "Alive counter";
CM_ SG_ 278 TIPLLaneInfo0_blockCtr "Block counter for synchronisation";
CM_ SG_ 278 TIPLLaneInfo0_dLeftBorder_sw "lateral position of the left lane border of each lane segment for x = {lower lane limit} in m";
CM_ SG_ 278 TIPLLaneInfo0_dLowerLimitLane_sw "dx value of the lower lane limit for each lane segment in m";
CM_ SG_ 278 TIPLLaneInfo0_dRightBorder_sw "lateral position of the right lane border of each lane segment for x = {lower lane limit} in m";
CM_ SG_ 278 TIPLLaneInfo0_dUpperLimitLane_sw "dx value of the upper lane limit for each lane segment in m";
CM_ SG_ 278 TIPLLaneInfo0_prob1Lane_ub "Probability of each lane segment that this lane segment exists";
CM_ SG_ 279 TIPLLaneInfo1_CRC "Check Sum";
CM_ SG_ 279 TIPLLaneInfo1_MsgCtr "Alive counter";
CM_ SG_ 279 TIPLLaneInfo1_blockCtr "Block counter for synchronisation";
CM_ SG_ 279 TIPLLaneInfo1_dLeftBorder_sw "lateral position of the left lane border of each lane segment for x = {lower lane limit} in m";
CM_ SG_ 279 TIPLLaneInfo1_dLowerLimitLane_sw "dx value of the lower lane limit for each lane segment in m";
CM_ SG_ 279 TIPLLaneInfo1_dRightBorder_sw "lateral position of the right lane border of each lane segment for x = {lower lane limit} in m";
CM_ SG_ 279 TIPLLaneInfo1_dUpperLimitLane_sw "dx value of the upper lane limit for each lane segment in m";
CM_ SG_ 279 TIPLLaneInfo1_prob1Lane_ub "Probability of each lane segment that this lane segment exists";
CM_ SG_ 280 TIPLLaneInfo2_CRC "Check Sum";
CM_ SG_ 280 TIPLLaneInfo2_MsgCtr "Alive counter";
CM_ SG_ 280 TIPLLaneInfo2_blockCtr "Block counter for synchronisation";
CM_ SG_ 280 TIPLLaneInfo2_dLeftBorder_sw "lateral position of the left lane border of each lane segment for x = {lower lane limit} in m";
CM_ SG_ 280 TIPLLaneInfo2_dLowerLimitLane_sw "dx value of the lower lane limit for each lane segment in m";
CM_ SG_ 280 TIPLLaneInfo2_dRightBorder_sw "lateral position of the right lane border of each lane segment for x = {lower lane limit} in m";
CM_ SG_ 280 TIPLLaneInfo2_dUpperLimitLane_sw "dx value of the upper lane limit for each lane segment in m";
CM_ SG_ 280 TIPLLaneInfo2_prob1Lane_ub "Probability of each lane segment that this lane segment exists";
CM_ SG_ 281 TIPLLaneInfo3_CRC "Check Sum";
CM_ SG_ 281 TIPLLaneInfo3_MsgCtr "Alive counter";
CM_ SG_ 281 TIPLLaneInfo3_blockCtr "Block counter for synchronisation";
CM_ SG_ 281 TIPLLaneInfo3_dLeftBorder_sw "lateral position of the left lane border of each lane segment for x = {lower lane limit} in m";
CM_ SG_ 281 TIPLLaneInfo3_dLowerLimitLane_sw "dx value of the lower lane limit for each lane segment in m";
CM_ SG_ 281 TIPLLaneInfo3_dRightBorder_sw "lateral position of the right lane border of each lane segment for x = {lower lane limit} in m";
CM_ SG_ 281 TIPLLaneInfo3_dUpperLimitLane_sw "dx value of the upper lane limit for each lane segment in m";
CM_ SG_ 281 TIPLLaneInfo3_prob1Lane_ub "Probability of each lane segment that this lane segment exists";
CM_ SG_ 288 OnComingObj0_CRC "CRC";
CM_ SG_ 288 OnComingObj0_MsgCtr "Alive Counter";
CM_ SG_ 288 OnComingObj0_blockCtr "Block counter for synchronisation";
CM_ SG_ 288 OnComingObj0_dWidth_sw "width of object";
CM_ SG_ 288 OnComingObj0_dxv_sw "longitudinal distance, relative to ego";
CM_ SG_ 288 OnComingObj0_dyv_sw "lateral distance, relative to ego";
CM_ SG_ 288 OnComingObj0_Handle_ub "PER fus handle of the object";
CM_ SG_ 288 OnComingObj0_RFF_ub "the object is fused with video(1) or radar only(0)";
CM_ SG_ 288 OnComingObj0_vxv_sw "longitudinal velocity, relative to ego";
CM_ SG_ 289 OnComingObj1_CRC "CRC";
CM_ SG_ 289 OnComingObj1_MsgCtr "Alive Counter";
CM_ SG_ 289 OnComingObj1_blockCtr "Block counter for synchronisation";
CM_ SG_ 289 OnComingObj1_dWidth_sw "width of object";
CM_ SG_ 289 OnComingObj1_dxv_sw "longitudinal distance, relative to ego";
CM_ SG_ 289 OnComingObj1_dyv_sw "lateral distance, relative to ego";
CM_ SG_ 289 OnComingObj1_Handle_ub "PER fus handle of the object";
CM_ SG_ 289 OnComingObj1_RFF_ub "the object is fused with video(1) or radar only(0)";
CM_ SG_ 289 OnComingObj1_vxv_sw "longitudinal velocity, relative to ego";
CM_ SG_ 290 OnComingObj2_CRC "CRC";
CM_ SG_ 290 OnComingObj2_MsgCtr "Alive Counter";
CM_ SG_ 290 OnComingObj2_blockCtr "Block counter for synchronisation";
CM_ SG_ 290 OnComingObj2_dWidth_sw "width of object";
CM_ SG_ 290 OnComingObj2_dxv_sw "longitudinal distance, relative to ego";
CM_ SG_ 290 OnComingObj2_dyv_sw "lateral distance, relative to ego";
CM_ SG_ 290 OnComingObj2_Handle_ub "PER fus handle of the object";
CM_ SG_ 290 OnComingObj2_RFF_ub "the object is fused with video(1) or radar only(0)";
CM_ SG_ 290 OnComingObj2_vxv_sw "longitudinal velocity, relative to ego";
CM_ SG_ 291 OnComingObj3_CRC "CRC";
CM_ SG_ 291 OnComingObj3_MsgCtr "Alive Counter";
CM_ SG_ 291 OnComingObj3_blockCtr "Block counter for synchronisation";
CM_ SG_ 291 OnComingObj3_dWidth_sw "width of object";
CM_ SG_ 291 OnComingObj3_dxv_sw "longitudinal distance, relative to ego";
CM_ SG_ 291 OnComingObj3_dyv_sw "lateral distance, relative to ego";
CM_ SG_ 291 OnComingObj3_Handle_ub "PER fus handle of the object";
CM_ SG_ 291 OnComingObj3_RFF_ub "the object is fused with video(1) or radar only(0)";
CM_ SG_ 291 OnComingObj3_vxv_sw "longitudinal velocity, relative to ego";
CM_ SG_ 292 OnGoingObj0_CRC "CRC";
CM_ SG_ 292 OnGoingObj0_MsgCtr "Alive Counter";
CM_ SG_ 292 OnGoingObj0_blockCtr "Block counter for synchronisation";
CM_ SG_ 292 OnGoingObj0_dxv_sw "longitudinal distance, relative to ego";
CM_ SG_ 292 OnGoingObj0_dyv_sw "lateral distance, relative to ego";
CM_ SG_ 292 OnGoingObj0_Handle_ub "PER fus handle of the object";
CM_ SG_ 292 OnGoingObj0_RFF_ub "the object is fused with video(1) or radar only(0)";
CM_ SG_ 292 OnGoingObj0_vxv_sw "longitudinal velocity, relative to ego";
CM_ SG_ 293 OnGoingObj1_CRC "CRC";
CM_ SG_ 293 OnGoingObj1_MsgCtr "Alive Counter";
CM_ SG_ 293 OnGoingObj1_blockCtr "Block counter for synchronisation";
CM_ SG_ 293 OnGoingObj1_dxv_sw "longitudinal distance, relative to ego";
CM_ SG_ 293 OnGoingObj1_dyv_sw "lateral distance, relative to ego";
CM_ SG_ 293 OnGoingObj1_Handle_ub "PER fus handle of the object";
CM_ SG_ 293 OnGoingObj1_RFF_ub "the object is fused with video(1) or radar only(0)";
CM_ SG_ 293 OnGoingObj1_vxv_sw "longitudinal velocity, relative to ego";
CM_ SG_ 304 TrajPointACCObj0_CRC "Check Sum";
CM_ SG_ 304 TrajPointACCObj0_MsgCtr "Alive counter";
CM_ SG_ 304 TrajPointACCObj0_blockCtr "Block counter for synchronisation";
CM_ SG_ 304 TrajPointACCObj0_Valid_b "object was existent in last cycle";
CM_ SG_ 304 TrajPointACCObj0_Drive_b "object is driving in same direction";
CM_ SG_ 304 TrajPointACCObj0_Stand_b "object is standing";
CM_ SG_ 304 TrajPointACCObj0_InvDir_b "object is driving in opposite direction or object has stopped after driving in opposite direction";
CM_ SG_ 304 TrajPointACCObj0_Stopped_b "object has stopped";
CM_ SG_ 304 TrajPointACCObj0_TrajEnd_b "object is measured";
CM_ SG_ 304 TrajPointACCObj0_dVarXv_uw "variance longitudinal distance";
CM_ SG_ 304 TrajPointACCObj0_dVarYv_uw "variance lateral distance";
CM_ SG_ 304 TrajPointACCObj0_dxv_sw "longitudinal distance";
CM_ SG_ 304 TrajPointACCObj0_dyv_sw "lateral distance";
CM_ SG_ 304 TrajPointACCObj0_wExistProb_ub "probability of existence of a physical object";
CM_ SG_ 304 TrajPointACCObj0_timestamp "time of detection";
CM_ SG_ 305 TrajPointACCObj1_CRC "Check Sum";
CM_ SG_ 305 TrajPointACCObj1_MsgCtr "Alive counter";
CM_ SG_ 305 TrajPointACCObj1_blockCtr "Block counter for synchronisation";
CM_ SG_ 305 TrajPointACCObj1_Valid_b "object was existent in last cycle";
CM_ SG_ 305 TrajPointACCObj1_Drive_b "object is driving in same direction";
CM_ SG_ 305 TrajPointACCObj1_Stand_b "object is standing";
CM_ SG_ 305 TrajPointACCObj1_InvDir_b "object is driving in opposite direction or object has stopped after driving in opposite direction";
CM_ SG_ 305 TrajPointACCObj1_Stopped_b "object has stopped";
CM_ SG_ 305 TrajPointACCObj1_TrajEnd_b "object is measured";
CM_ SG_ 305 TrajPointACCObj1_dVarXv_uw "variance longitudinal distance";
CM_ SG_ 305 TrajPointACCObj1_dVarYv_uw "variance lateral distance";
CM_ SG_ 305 TrajPointACCObj1_dxv_sw "longitudinal distance";
CM_ SG_ 305 TrajPointACCObj1_dyv_sw "lateral distance";
CM_ SG_ 305 TrajPointACCObj1_wExistProb_ub "probability of existence of a physical object";
CM_ SG_ 305 TrajPointACCObj1_timestamp "time of detection";
CM_ SG_ 306 TrajPointACCObj2_CRC "Check Sum";
CM_ SG_ 306 TrajPointACCObj2_MsgCtr "Alive counter";
CM_ SG_ 306 TrajPointACCObj2_blockCtr "Block counter for synchronisation";
CM_ SG_ 306 TrajPointACCObj2_Valid_b "object was existent in last cycle";
CM_ SG_ 306 TrajPointACCObj2_Drive_b "object is driving in same direction";
CM_ SG_ 306 TrajPointACCObj2_Stand_b "object is standing";
CM_ SG_ 306 TrajPointACCObj2_InvDir_b "object is driving in opposite direction or object has stopped after driving in opposite direction";
CM_ SG_ 306 TrajPointACCObj2_Stopped_b "object has stopped";
CM_ SG_ 306 TrajPointACCObj2_TrajEnd_b "object is measured";
CM_ SG_ 306 TrajPointACCObj2_dVarXv_uw "variance longitudinal distance";
CM_ SG_ 306 TrajPointACCObj2_dVarYv_uw "variance lateral distance";
CM_ SG_ 306 TrajPointACCObj2_dxv_sw "longitudinal distance";
CM_ SG_ 306 TrajPointACCObj2_dyv_sw "lateral distance";
CM_ SG_ 306 TrajPointACCObj2_wExistProb_ub "probability of existence of a physical object";
CM_ SG_ 306 TrajPointACCObj2_timestamp "time of detection";
CM_ SG_ 307 TrajPointACCObj3_CRC "Check Sum";
CM_ SG_ 307 TrajPointACCObj3_MsgCtr "Alive counter";
CM_ SG_ 307 TrajPointACCObj3_blockCtr "Block counter for synchronisation";
CM_ SG_ 307 TrajPointACCObj3_Valid_b "object was existent in last cycle";
CM_ SG_ 307 TrajPointACCObj3_Drive_b "object is driving in same direction";
CM_ SG_ 307 TrajPointACCObj3_Stand_b "object is standing";
CM_ SG_ 307 TrajPointACCObj3_InvDir_b "object is driving in opposite direction or object has stopped after driving in opposite direction";
CM_ SG_ 307 TrajPointACCObj3_Stopped_b "object has stopped";
CM_ SG_ 307 TrajPointACCObj3_TrajEnd_b "object is measured";
CM_ SG_ 307 TrajPointACCObj3_dVarXv_uw "variance longitudinal distance";
CM_ SG_ 307 TrajPointACCObj3_dVarYv_uw "variance lateral distance";
CM_ SG_ 307 TrajPointACCObj3_dxv_sw "longitudinal distance";
CM_ SG_ 307 TrajPointACCObj3_dyv_sw "lateral distance";
CM_ SG_ 307 TrajPointACCObj3_wExistProb_ub "probability of existence of a physical object";
CM_ SG_ 307 TrajPointACCObj3_timestamp "time of detection";
CM_ SG_ 308 TrajPointACCObj4_CRC "Check Sum";
CM_ SG_ 308 TrajPointACCObj4_MsgCtr "Alive counter";
CM_ SG_ 308 TrajPointACCObj4_blockCtr "Block counter for synchronisation";
CM_ SG_ 308 TrajPointACCObj4_Valid_b "object was existent in last cycle";
CM_ SG_ 308 TrajPointACCObj4_Drive_b "object is driving in same direction";
CM_ SG_ 308 TrajPointACCObj4_Stand_b "object is standing";
CM_ SG_ 308 TrajPointACCObj4_InvDir_b "object is driving in opposite direction or object has stopped after driving in opposite direction";
CM_ SG_ 308 TrajPointACCObj4_Stopped_b "object has stopped";
CM_ SG_ 308 TrajPointACCObj4_TrajEnd_b "object is measured";
CM_ SG_ 308 TrajPointACCObj4_dVarXv_uw "variance longitudinal distance";
CM_ SG_ 308 TrajPointACCObj4_dVarYv_uw "variance lateral distance";
CM_ SG_ 308 TrajPointACCObj4_dxv_sw "longitudinal distance";
CM_ SG_ 308 TrajPointACCObj4_dyv_sw "lateral distance";
CM_ SG_ 308 TrajPointACCObj4_wExistProb_ub "probability of existence of a physical object";
CM_ SG_ 308 TrajPointACCObj4_timestamp "time of detection";
CM_ SG_ 309 TrajPointACCObj5_CRC "Check Sum";
CM_ SG_ 309 TrajPointACCObj5_MsgCtr "Alive counter";
CM_ SG_ 309 TrajPointACCObj5_blockCtr "Block counter for synchronisation";
CM_ SG_ 309 TrajPointACCObj5_Valid_b "object was existent in last cycle";
CM_ SG_ 309 TrajPointACCObj5_Drive_b "object is driving in same direction";
CM_ SG_ 309 TrajPointACCObj5_Stand_b "object is standing";
CM_ SG_ 309 TrajPointACCObj5_InvDir_b "object is driving in opposite direction or object has stopped after driving in opposite direction";
CM_ SG_ 309 TrajPointACCObj5_Stopped_b "object has stopped";
CM_ SG_ 309 TrajPointACCObj5_TrajEnd_b "object is measured";
CM_ SG_ 309 TrajPointACCObj5_dVarXv_uw "variance longitudinal distance";
CM_ SG_ 309 TrajPointACCObj5_dVarYv_uw "variance lateral distance";
CM_ SG_ 309 TrajPointACCObj5_dxv_sw "longitudinal distance";
CM_ SG_ 309 TrajPointACCObj5_dyv_sw "lateral distance";
CM_ SG_ 309 TrajPointACCObj5_wExistProb_ub "probability of existence of a physical object";
CM_ SG_ 309 TrajPointACCObj5_timestamp "time of detection";
CM_ SG_ 310 TrajPointACCObj6_CRC "Check Sum";
CM_ SG_ 310 TrajPointACCObj6_MsgCtr "Alive counter";
CM_ SG_ 310 TrajPointACCObj6_blockCtr "Block counter for synchronisation";
CM_ SG_ 310 TrajPointACCObj6_Valid_b "object was existent in last cycle";
CM_ SG_ 310 TrajPointACCObj6_Stand_b "object is standing";
CM_ SG_ 310 TrajPointACCObj6_Drive_b "object is driving in same direction";
CM_ SG_ 310 TrajPointACCObj6_InvDir_b "object is driving in opposite direction or object has stopped after driving in opposite direction";
CM_ SG_ 310 TrajPointACCObj6_Stopped_b "object has stopped";
CM_ SG_ 310 TrajPointACCObj6_TrajEnd_b "object is measured";
CM_ SG_ 310 TrajPointACCObj6_dVarXv_uw "variance longitudinal distance";
CM_ SG_ 310 TrajPointACCObj6_dVarYv_uw "variance lateral distance";
CM_ SG_ 310 TrajPointACCObj6_dxv_sw "longitudinal distance";
CM_ SG_ 310 TrajPointACCObj6_dyv_sw "lateral distance";
CM_ SG_ 310 TrajPointACCObj6_wExistProb_ub "probability of existence of a physical object";
CM_ SG_ 310 TrajPointACCObj6_timestamp "time of detection";
CM_ SG_ 311 TrajPointACCObj7_CRC "Check Sum";
CM_ SG_ 311 TrajPointACCObj7_MsgCtr "Alive counter";
CM_ SG_ 311 TrajPointACCObj7_blockCtr "Block counter for synchronisation";
CM_ SG_ 311 TrajPointACCObj7_Valid_b "object was existent in last cycle";
CM_ SG_ 311 TrajPointACCObj7_Drive_b "object is driving in same direction";
CM_ SG_ 311 TrajPointACCObj7_Stand_b "object is standing";
CM_ SG_ 311 TrajPointACCObj7_InvDir_b "object is driving in opposite direction or object has stopped after driving in opposite direction";
CM_ SG_ 311 TrajPointACCObj7_Stopped_b "object has stopped";
CM_ SG_ 311 TrajPointACCObj7_TrajEnd_b "object is measured";
CM_ SG_ 311 TrajPointACCObj7_dVarXv_uw "variance longitudinal distance";
CM_ SG_ 311 TrajPointACCObj7_dVarYv_uw "variance lateral distance";
CM_ SG_ 311 TrajPointACCObj7_dxv_sw "longitudinal distance";
CM_ SG_ 311 TrajPointACCObj7_dyv_sw "lateral distance";
CM_ SG_ 311 TrajPointACCObj7_wExistProb_ub "probability of existence of a physical object";
CM_ SG_ 311 TrajPointACCObj7_timestamp "time of detection";
CM_ SG_ 312 TrajPointACCObj8_CRC "Check Sum";
CM_ SG_ 312 TrajPointACCObj8_MsgCtr "Alive counter";
CM_ SG_ 312 TrajPointACCObj8_blockCtr "Block counter for synchronisation";
CM_ SG_ 312 TrajPointACCObj8_Valid_b "object was existent in last cycle";
CM_ SG_ 312 TrajPointACCObj8_Drive_b "object is driving in same direction";
CM_ SG_ 312 TrajPointACCObj8_Stand_b "object is standing";
CM_ SG_ 312 TrajPointACCObj8_InvDir_b "object is driving in opposite direction or object has stopped after driving in opposite direction";
CM_ SG_ 312 TrajPointACCObj8_Stopped_b "object has stopped";
CM_ SG_ 312 TrajPointACCObj8_TrajEnd_b "object is measured";
CM_ SG_ 312 TrajPointACCObj8_dVarXv_uw "variance longitudinal distance";
CM_ SG_ 312 TrajPointACCObj8_dVarYv_uw "variance lateral distance";
CM_ SG_ 312 TrajPointACCObj8_dxv_sw "longitudinal distance";
CM_ SG_ 312 TrajPointACCObj8_dyv_sw "lateral distance";
CM_ SG_ 312 TrajPointACCObj8_wExistProb_ub "probability of existence of a physical object";
CM_ SG_ 312 TrajPointACCObj8_timestamp "time of detection";
CM_ SG_ 313 TrajPointACCObj9_CRC "Check Sum";
CM_ SG_ 313 TrajPointACCObj9_MsgCtr "Alive counter";
CM_ SG_ 313 TrajPointACCObj9_blockCtr "Block counter for synchronisation";
CM_ SG_ 313 TrajPointACCObj9_Valid_b "object was existent in last cycle";
CM_ SG_ 313 TrajPointACCObj9_Drive_b "object is driving in same direction";
CM_ SG_ 313 TrajPointACCObj9_Stand_b "object is standing";
CM_ SG_ 313 TrajPointACCObj9_InvDir_b "object is driving in opposite direction or object has stopped after driving in opposite direction";
CM_ SG_ 313 TrajPointACCObj9_Stopped_b "object has stopped";
CM_ SG_ 313 TrajPointACCObj9_TrajEnd_b "object is measured";
CM_ SG_ 313 TrajPointACCObj9_dVarXv_uw "variance longitudinal distance";
CM_ SG_ 313 TrajPointACCObj9_dVarYv_uw "variance lateral distance";
CM_ SG_ 313 TrajPointACCObj9_dxv_sw "longitudinal distance";
CM_ SG_ 313 TrajPointACCObj9_dyv_sw "lateral distance";
CM_ SG_ 313 TrajPointACCObj9_wExistProb_ub "probability of existence of a physical object";
CM_ SG_ 313 TrajPointACCObj9_timestamp "time of detection";
CM_ SG_ 320 TrajPointACCObj10_CRC "Check Sum";
CM_ SG_ 320 TrajPointACCObj10_MsgCtr "Alive counter";
CM_ SG_ 320 TrajPointACCObj10_blockCtr "Block counter for synchronisation";
CM_ SG_ 320 TrajPointACCObj10_Valid_b "object was existent in last cycle";
CM_ SG_ 320 TrajPointACCObj10_Drive_b "object is driving in same direction";
CM_ SG_ 320 TrajPointACCObj10_Stand_b "object is standing";
CM_ SG_ 320 TrajPointACCObj10_InvDir_b "object is driving in opposite direction or object has stopped after driving in opposite direction";
CM_ SG_ 320 TrajPointACCObj10_Stopped_b "object has stopped";
CM_ SG_ 320 TrajPointACCObj10_TrajEnd_b "object is measured";
CM_ SG_ 320 TrajPointACCObj10_dVarXv_uw "variance longitudinal distance";
CM_ SG_ 320 TrajPointACCObj10_dVarYv_uw "variance lateral distance";
CM_ SG_ 320 TrajPointACCObj10_dxv_sw "longitudinal distance";
CM_ SG_ 320 TrajPointACCObj10_dyv_sw "lateral distance";
CM_ SG_ 320 TrajPointACCObj10_wExistProb_ub "probability of existence of a physical object";
CM_ SG_ 320 TrajPointACCObj10_timestamp "time of detection";
CM_ SG_ 321 TrajPointACCObj11_CRC "Check Sum";
CM_ SG_ 321 TrajPointACCObj11_MsgCtr "Alive counter";
CM_ SG_ 321 TrajPointACCObj11_blockCtr "Block counter for synchronisation";
CM_ SG_ 321 TrajPointACCObj11_Valid_b "object was existent in last cycle";
CM_ SG_ 321 TrajPointACCObj11_Drive_b "object is driving in same direction";
CM_ SG_ 321 TrajPointACCObj11_Stand_b "object is standing";
CM_ SG_ 321 TrajPointACCObj11_InvDir_b "object is driving in opposite direction or object has stopped after driving in opposite direction";
CM_ SG_ 321 TrajPointACCObj11_Stopped_b "object has stopped";
CM_ SG_ 321 TrajPointACCObj11_TrajEnd_b "object is measured";
CM_ SG_ 321 TrajPointACCObj11_dVarXv_uw "variance longitudinal distance";
CM_ SG_ 321 TrajPointACCObj11_dVarYv_uw "variance lateral distance";
CM_ SG_ 321 TrajPointACCObj11_dxv_sw "longitudinal distance";
CM_ SG_ 321 TrajPointACCObj11_dyv_sw "lateral distance";
CM_ SG_ 321 TrajPointACCObj11_wExistProb_ub "probability of existence of a physical object";
CM_ SG_ 321 TrajPointACCObj11_timestamp "time of detection";
CM_ SG_ 322 TrajPointACCObj12_CRC "Check Sum";
CM_ SG_ 322 TrajPointACCObj12_MsgCtr "Alive counter";
CM_ SG_ 322 TrajPointACCObj12_blockCtr "Block counter for synchronisation";
CM_ SG_ 322 TrajPointACCObj12_Valid_b "object was existent in last cycle";
CM_ SG_ 322 TrajPointACCObj12_Drive_b "object is driving in same direction";
CM_ SG_ 322 TrajPointACCObj12_Stand_b "object is standing";
CM_ SG_ 322 TrajPointACCObj12_InvDir_b "object is driving in opposite direction or object has stopped after driving in opposite direction";
CM_ SG_ 322 TrajPointACCObj12_Stopped_b "object has stopped";
CM_ SG_ 322 TrajPointACCObj12_TrajEnd_b "object is measured";
CM_ SG_ 322 TrajPointACCObj12_dVarXv_uw "variance longitudinal distance";
CM_ SG_ 322 TrajPointACCObj12_dVarYv_uw "variance lateral distance";
CM_ SG_ 322 TrajPointACCObj12_dxv_sw "longitudinal distance";
CM_ SG_ 322 TrajPointACCObj12_dyv_sw "lateral distance";
CM_ SG_ 322 TrajPointACCObj12_wExistProb_ub "probability of existence of a physical object";
CM_ SG_ 322 TrajPointACCObj12_timestamp "time of detection";
CM_ SG_ 323 TrajPointACCObj13_CRC "Check Sum";
CM_ SG_ 323 TrajPointACCObj13_MsgCtr "Alive counter";
CM_ SG_ 323 TrajPointACCObj13_blockCtr "Block counter for synchronisation";
CM_ SG_ 323 TrajPointACCObj13_Valid_b "object was existent in last cycle";
CM_ SG_ 323 TrajPointACCObj13_Drive_b "object is driving in same direction";
CM_ SG_ 323 TrajPointACCObj13_Stand_b "object is standing";
CM_ SG_ 323 TrajPointACCObj13_InvDir_b "object is driving in opposite direction or object has stopped after driving in opposite direction";
CM_ SG_ 323 TrajPointACCObj13_Stopped_b "object has stopped";
CM_ SG_ 323 TrajPointACCObj13_TrajEnd_b "object is measured";
CM_ SG_ 323 TrajPointACCObj13_dVarXv_uw "variance longitudinal distance";
CM_ SG_ 323 TrajPointACCObj13_dVarYv_uw "variance lateral distance";
CM_ SG_ 323 TrajPointACCObj13_dxv_sw "longitudinal distance";
CM_ SG_ 323 TrajPointACCObj13_dyv_sw "lateral distance";
CM_ SG_ 323 TrajPointACCObj13_wExistProb_ub "probability of existence of a physical object";
CM_ SG_ 323 TrajPointACCObj13_timestamp "time of detection";
CM_ SG_ 324 TrajPointACCObj14_CRC "Check Sum";
CM_ SG_ 324 TrajPointACCObj14_MsgCtr "Alive counter";
CM_ SG_ 324 TrajPointACCObj14_blockCtr "Block counter for synchronisation";
CM_ SG_ 324 TrajPointACCObj14_Valid_b "object was existent in last cycle";
CM_ SG_ 324 TrajPointACCObj14_Drive_b "object is driving in same direction";
CM_ SG_ 324 TrajPointACCObj14_Stand_b "object is standing";
CM_ SG_ 324 TrajPointACCObj14_InvDir_b "object is driving in opposite direction or object has stopped after driving in opposite direction";
CM_ SG_ 324 TrajPointACCObj14_Stopped_b "object has stopped";
CM_ SG_ 324 TrajPointACCObj14_TrajEnd_b "object is measured";
CM_ SG_ 324 TrajPointACCObj14_dVarXv_uw "variance longitudinal distance";
CM_ SG_ 324 TrajPointACCObj14_dVarYv_uw "variance lateral distance";
CM_ SG_ 324 TrajPointACCObj14_dxv_sw "longitudinal distance";
CM_ SG_ 324 TrajPointACCObj14_dyv_sw "lateral distance";
CM_ SG_ 324 TrajPointACCObj14_wExistProb_ub "probability of existence of a physical object";
CM_ SG_ 324 TrajPointACCObj14_timestamp "time of detection";
CM_ SG_ 325 TrajPointACCObj15_CRC "Check Sum";
CM_ SG_ 325 TrajPointACCObj15_MsgCtr "Alive counter";
CM_ SG_ 325 TrajPointACCObj15_blockCtr "Block counter for synchronisation";
CM_ SG_ 325 TrajPointACCObj15_Valid_b "object was existent in last cycle";
CM_ SG_ 325 TrajPointACCObj15_Drive_b "object is driving in same direction";
CM_ SG_ 325 TrajPointACCObj15_Stand_b "object is standing";
CM_ SG_ 325 TrajPointACCObj15_InvDir_b "object is driving in opposite direction or object has stopped after driving in opposite direction";
CM_ SG_ 325 TrajPointACCObj15_Stopped_b "object has stopped";
CM_ SG_ 325 TrajPointACCObj15_TrajEnd_b "object is measured";
CM_ SG_ 325 TrajPointACCObj15_dVarXv_uw "variance longitudinal distance";
CM_ SG_ 325 TrajPointACCObj15_dVarYv_uw "variance lateral distance";
CM_ SG_ 325 TrajPointACCObj15_dxv_sw "longitudinal distance";
CM_ SG_ 325 TrajPointACCObj15_dyv_sw "lateral distance";
CM_ SG_ 325 TrajPointACCObj15_wExistProb_ub "probability of existence of a physical object";
CM_ SG_ 325 TrajPointACCObj15_timestamp "time of detection";
CM_ SG_ 326 TrajPointACCObj16_CRC "Check Sum";
CM_ SG_ 326 TrajPointACCObj16_MsgCtr "Alive counter";
CM_ SG_ 326 TrajPointACCObj16_blockCtr "Block counter for synchronisation";
CM_ SG_ 326 TrajPointACCObj16_Valid_b "object was existent in last cycle";
CM_ SG_ 326 TrajPointACCObj16_Drive_b "object is driving in same direction";
CM_ SG_ 326 TrajPointACCObj16_Stand_b "object is standing";
CM_ SG_ 326 TrajPointACCObj16_InvDir_b "object is driving in opposite direction or object has stopped after driving in opposite direction";
CM_ SG_ 326 TrajPointACCObj16_Stopped_b "object has stopped";
CM_ SG_ 326 TrajPointACCObj16_TrajEnd_b "object is measured";
CM_ SG_ 326 TrajPointACCObj16_dVarXv_uw "variance longitudinal distance";
CM_ SG_ 326 TrajPointACCObj16_dVarYv_uw "variance lateral distance";
CM_ SG_ 326 TrajPointACCObj16_dxv_sw "longitudinal distance";
CM_ SG_ 326 TrajPointACCObj16_dyv_sw "lateral distance";
CM_ SG_ 326 TrajPointACCObj16_wExistProb_ub "probability of existence of a physical object";
CM_ SG_ 326 TrajPointACCObj16_timestamp "time of detection";
CM_ SG_ 327 TrajPointACCObj17_CRC "Check Sum";
CM_ SG_ 327 TrajPointACCObj17_MsgCtr "Alive counter";
CM_ SG_ 327 TrajPointACCObj17_blockCtr "Block counter for synchronisation";
CM_ SG_ 327 TrajPointACCObj17_Valid_b "object was existent in last cycle";
CM_ SG_ 327 TrajPointACCObj17_Drive_b "object is driving in same direction";
CM_ SG_ 327 TrajPointACCObj17_Stand_b "object is standing";
CM_ SG_ 327 TrajPointACCObj17_InvDir_b "object is driving in opposite direction or object has stopped after driving in opposite direction";
CM_ SG_ 327 TrajPointACCObj17_Stopped_b "object has stopped";
CM_ SG_ 327 TrajPointACCObj17_TrajEnd_b "object is measured";
CM_ SG_ 327 TrajPointACCObj17_dVarXv_uw "variance longitudinal distance";
CM_ SG_ 327 TrajPointACCObj17_dVarYv_uw "variance lateral distance";
CM_ SG_ 327 TrajPointACCObj17_dxv_sw "longitudinal distance";
CM_ SG_ 327 TrajPointACCObj17_dyv_sw "lateral distance";
CM_ SG_ 327 TrajPointACCObj17_wExistProb_ub "probability of existence of a physical object";
CM_ SG_ 327 TrajPointACCObj17_timestamp "time of detection";
CM_ SG_ 328 TrajPointACCObj18_CRC "Check Sum";
CM_ SG_ 328 TrajPointACCObj18_MsgCtr "Alive counter";
CM_ SG_ 328 TrajPointACCObj18_blockCtr "Block counter for synchronisation";
CM_ SG_ 328 TrajPointACCObj18_Valid_b "object was existent in last cycle";
CM_ SG_ 328 TrajPointACCObj18_Drive_b "object is driving in same direction";
CM_ SG_ 328 TrajPointACCObj18_Stand_b "object is standing";
CM_ SG_ 328 TrajPointACCObj18_InvDir_b "object is driving in opposite direction or object has stopped after driving in opposite direction";
CM_ SG_ 328 TrajPointACCObj18_Stopped_b "object has stopped";
CM_ SG_ 328 TrajPointACCObj18_TrajEnd_b "object is measured";
CM_ SG_ 328 TrajPointACCObj18_dVarXv_uw "variance longitudinal distance";
CM_ SG_ 328 TrajPointACCObj18_dVarYv_uw "variance lateral distance";
CM_ SG_ 328 TrajPointACCObj18_dxv_sw "longitudinal distance";
CM_ SG_ 328 TrajPointACCObj18_dyv_sw "lateral distance";
CM_ SG_ 328 TrajPointACCObj18_wExistProb_ub "probability of existence of a physical object";
CM_ SG_ 328 TrajPointACCObj18_timestamp "time of detection";
CM_ SG_ 329 TrajPointACCObj19_CRC "Check Sum";
CM_ SG_ 329 TrajPointACCObj19_MsgCtr "Alive counter";
CM_ SG_ 329 TrajPointACCObj19_blockCtr "Block counter for synchronisation";
CM_ SG_ 329 TrajPointACCObj19_Valid_b "object was existent in last cycle";
CM_ SG_ 329 TrajPointACCObj19_Drive_b "object is driving in same direction";
CM_ SG_ 329 TrajPointACCObj19_Stand_b "object is standing";
CM_ SG_ 329 TrajPointACCObj19_InvDir_b "object is driving in opposite direction or object has stopped after driving in opposite direction";
CM_ SG_ 329 TrajPointACCObj19_Stopped_b "object has stopped";
CM_ SG_ 329 TrajPointACCObj19_TrajEnd_b "object is measured";
CM_ SG_ 329 TrajPointACCObj19_dVarXv_uw "variance longitudinal distance";
CM_ SG_ 329 TrajPointACCObj19_dVarYv_uw "variance lateral distance";
CM_ SG_ 329 TrajPointACCObj19_dxv_sw "longitudinal distance";
CM_ SG_ 329 TrajPointACCObj19_dyv_sw "lateral distance";
CM_ SG_ 329 TrajPointACCObj19_wExistProb_ub "probability of existence of a physical object";
CM_ SG_ 329 TrajPointACCObj19_timestamp "time of detection";
CM_ SG_ 336 TrajPointACCObj20_CRC "Check Sum";
CM_ SG_ 336 TrajPointACCObj20_MsgCtr "Alive counter";
CM_ SG_ 336 TrajPointACCObj20_blockCtr "Block counter for synchronisation";
CM_ SG_ 336 TrajPointACCObj20_Valid_b "object was existent in last cycle";
CM_ SG_ 336 TrajPointACCObj20_Drive_b "object is driving in same direction";
CM_ SG_ 336 TrajPointACCObj20_Stand_b "object is standing";
CM_ SG_ 336 TrajPointACCObj20_InvDir_b "object is driving in opposite direction or object has stopped after driving in opposite direction";
CM_ SG_ 336 TrajPointACCObj20_Stopped_b "object has stopped";
CM_ SG_ 336 TrajPointACCObj20_TrajEnd_b "object is measured";
CM_ SG_ 336 TrajPointACCObj20_dVarXv_uw "variance longitudinal distance";
CM_ SG_ 336 TrajPointACCObj20_dVarYv_uw "variance lateral distance";
CM_ SG_ 336 TrajPointACCObj20_dxv_sw "longitudinal distance";
CM_ SG_ 336 TrajPointACCObj20_dyv_sw "lateral distance";
CM_ SG_ 336 TrajPointACCObj20_wExistProb_ub "probability of existence of a physical object";
CM_ SG_ 336 TrajPointACCObj20_timestamp "time of detection";
CM_ SG_ 337 TrajPointACCObj21_CRC "Check Sum";
CM_ SG_ 337 TrajPointACCObj21_MsgCtr "Alive counter";
CM_ SG_ 337 TrajPointACCObj21_blockCtr "Block counter for synchronisation";
CM_ SG_ 337 TrajPointACCObj21_Valid_b "object was existent in last cycle";
CM_ SG_ 337 TrajPointACCObj21_Drive_b "object is driving in same direction";
CM_ SG_ 337 TrajPointACCObj21_Stand_b "object is standing";
CM_ SG_ 337 TrajPointACCObj21_InvDir_b "object is driving in opposite direction or object has stopped after driving in opposite direction";
CM_ SG_ 337 TrajPointACCObj21_Stopped_b "object has stopped";
CM_ SG_ 337 TrajPointACCObj21_TrajEnd_b "object is measured";
CM_ SG_ 337 TrajPointACCObj21_dVarXv_uw "variance longitudinal distance";
CM_ SG_ 337 TrajPointACCObj21_dVarYv_uw "variance lateral distance";
CM_ SG_ 337 TrajPointACCObj21_dxv_sw "longitudinal distance";
CM_ SG_ 337 TrajPointACCObj21_dyv_sw "lateral distance";
CM_ SG_ 337 TrajPointACCObj21_wExistProb_ub "probability of existence of a physical object";
CM_ SG_ 337 TrajPointACCObj21_timestamp "time of detection";
CM_ SG_ 338 TrajPointACCObj22_CRC "Check Sum";
CM_ SG_ 338 TrajPointACCObj22_MsgCtr "Alive counter";
CM_ SG_ 338 TrajPointACCObj22_blockCtr "Block counter for synchronisation";
CM_ SG_ 338 TrajPointACCObj22_Valid_b "object was existent in last cycle";
CM_ SG_ 338 TrajPointACCObj22_Drive_b "object is driving in same direction";
CM_ SG_ 338 TrajPointACCObj22_Stand_b "object is standing";
CM_ SG_ 338 TrajPointACCObj22_InvDir_b "object is driving in opposite direction or object has stopped after driving in opposite direction";
CM_ SG_ 338 TrajPointACCObj22_Stopped_b "object has stopped";
CM_ SG_ 338 TrajPointACCObj22_TrajEnd_b "object is measured";
CM_ SG_ 338 TrajPointACCObj22_dVarXv_uw "variance longitudinal distance";
CM_ SG_ 338 TrajPointACCObj22_dVarYv_uw "variance lateral distance";
CM_ SG_ 338 TrajPointACCObj22_dxv_sw "longitudinal distance";
CM_ SG_ 338 TrajPointACCObj22_dyv_sw "lateral distance";
CM_ SG_ 338 TrajPointACCObj22_wExistProb_ub "probability of existence of a physical object";
CM_ SG_ 338 TrajPointACCObj22_timestamp "time of detection";
CM_ SG_ 339 TrajPointACCObj23_CRC "Check Sum";
CM_ SG_ 339 TrajPointACCObj23_MsgCtr "Alive counter";
CM_ SG_ 339 TrajPointACCObj23_blockCtr "Block counter for synchronisation";
CM_ SG_ 339 TrajPointACCObj23_Valid_b "object was existent in last cycle";
CM_ SG_ 339 TrajPointACCObj23_Drive_b "object is driving in same direction";
CM_ SG_ 339 TrajPointACCObj23_Stand_b "object is standing";
CM_ SG_ 339 TrajPointACCObj23_InvDir_b "object is driving in opposite direction or object has stopped after driving in opposite direction";
CM_ SG_ 339 TrajPointACCObj23_Stopped_b "object has stopped";
CM_ SG_ 339 TrajPointACCObj23_TrajEnd_b "object is measured";
CM_ SG_ 339 TrajPointACCObj23_dVarXv_uw "variance longitudinal distance";
CM_ SG_ 339 TrajPointACCObj23_dVarYv_uw "variance lateral distance";
CM_ SG_ 339 TrajPointACCObj23_dxv_sw "longitudinal distance";
CM_ SG_ 339 TrajPointACCObj23_dyv_sw "lateral distance";
CM_ SG_ 339 TrajPointACCObj23_wExistProb_ub "probability of existence of a physical object";
CM_ SG_ 339 TrajPointACCObj23_timestamp "time of detection";
CM_ SG_ 340 ACCObjInfo_CRC "CRC";
CM_ SG_ 340 ACCObjInfo_MsgCtr "Alive Counter";
CM_ SG_ 340 ACCObjInfo_vxv_sw "longitudinal velocity, relative to ego";
CM_ SG_ 340 ACCObjInfo_blockCtr "Block counter for synchronisation";
CM_ SG_ 340 ACCObjInfo_dWidth_sw "width of object";
CM_ SG_ 340 ACCObjInfo_dxv_sw "longitudinal distance, relative to ego";
CM_ SG_ 340 ACCObjInfo_dyv_sw "lateral distance, relative to ego";
CM_ SG_ 340 ACCObjInfo_Handle_ub "PER fus handle of the object";
CM_ SG_ 340 ACCObjInfo_RFF_ub "the object is fused with video(1) or radar only(0)";
CM_ SG_ 340 ACCObjInfo_timestamp "time stamp for which the object data corresponds to";
CM_ SG_ 341 TrajACC_CRC "Check Sum";
CM_ SG_ 341 TrajACC_MsgCtr "Alive counter";
CM_ SG_ 341 TrajACC_blockCtr "Block counter for synchronisation";
CM_ SG_ 341 TrajACC_objType_ub "most probable object type";
CM_ SG_ 341 TrajACC_TrajHistCurrentIndex_ub "current object index in trajectory buffer";
CM_ SG_ 137 VFC_0x89_AliverCtr "Alive counter - Autosar E2E Profile 5";
CM_ SG_ 137 VFC_0x89_CRC "CRC - Autosar E2E Profile 5";
CM_ SG_ 137 VFC_MotorTorqueMaxLimitRequest "Maximum torque limit of EPS motor";
CM_ SG_ 137 VFC_MotorTorqueMinLimitRequest "EPS motor torque minimum limit";
CM_ SG_ 137 VFC_LatAngReqActive "Steering angle request (steering wheel end)";
CM_ SG_ 137 VFC_LatAngReq "Steering angle request activation;??????????,??????
0x384A-3FFF=Reserved";
CM_ SG_ 148 VFC_0x94_CRC "CRC - Autosar E2E Profile 5";
CM_ SG_ 148 VFC_0x94_AliverCtr "Alive counter - Autosar E2E Profile 5";
CM_ SG_ 148 VFC_LDWStatus "LDW status";
CM_ SG_ 148 VFC_LDWVibrationWarningReq "Vibration alarm request";
CM_ SG_ 148 VFC_LKAStatus "LKA status";
CM_ SG_ 145 Selflearning_angle "Selflearning_angle Values";
CM_ SG_ 145 Selflearning_status "Self learning Status";
CM_ SG_ 145 VFC_0x91_CRC "CRC - Autosar E2E Profile 5";
CM_ SG_ 145 VFC_0x91_AliverCtr "Alive counter - Autosar E2E Profile 5";
CM_ SG_ 145 VFC_DriverWindowControl "Main driving window control;
0x1~0x65= 0%~100% (???????);
0x66-0x7F= Reserved";
CM_ SG_ 145 VFC_ToTargetLatDistance "Real-time horizontal distance from target location;???????????,???????????";
CM_ SG_ 145 VFC_LLaneDistanceFusion "Distance from vehicle center to left lane line;0x0-0x78=-1-5;
0x79-0x7F=reserved;";
CM_ SG_ 145 VFC_SunroofControl "Skylight control;0x1~0x65=sunroof 0%~100%
0x67~0xCB=sunshade 0%~100%(???)";
CM_ SG_ 145 VFC_RLaneDistanceFusion "Distance from vehicle center to right lane line;0x0-0x78=-1-5;
0x79-0x7F=reserved;";
CM_ SG_ 146 VFC_0x92_CRC "CRC - Autosar E2E Profile 5";
CM_ SG_ 146 VFC_0x92_AliverCtr "Alive counter - Autosar E2E Profile 5";
CM_ SG_ 146 VFC_LASModeSelectionStatus "LAS mode selection signal status";
CM_ SG_ 146 VFC_LatTakeoverReq "Horizontal takeover request";
CM_ SG_ 146 VFC_HandsOnReq "handsOn request";
CM_ SG_ 146 VFC_RLaneMarkerType "Right lane line type";
CM_ SG_ 146 VFC_LaneChangeStatus "Lane change";
CM_ SG_ 146 VFC_RoadCurvatureFar "Road curvature 80m ahead;0x0-0x78=-0.03-0.03;
0x79-0x7F=reserved;";
CM_ SG_ 146 VFC_RRLaneDistance "Distance from the center of the vehicle to the lane line on the right and right:0x0~0x3c=0-12;0x3D~0x3F=reserved";
CM_ SG_ 146 VFC_IACCHWAMode "ACC_IACCHWAMode";
CM_ SG_ 146 VFC_LASWarningModeSelectionSts "LAS warning mode status";
CM_ SG_ 146 VFC_DriverHandsOffStatus "Driver disengagement";
CM_ SG_ 146 VFC_IACCHWATextInfoForDriver "IACC driver information prompt";
CM_ SG_ 146 VFC_LDWShakeLevStatus "LDW vibration intensity status";
CM_ SG_ 146 VFC_IACCHWAEnable "IACC/HWA enable switch status";
CM_ SG_ 146 VFC_HostLaneLeftStatus "Lane status on the right side of this lane0x9~0xF=reserved";
CM_ SG_ 146 VFC_ELKInterventionMode "Emergency lane keeping mode";
CM_ SG_ 146 VFC_ELKMode "Emergency lane keeping system status0x4~0x7=reseved";
CM_ SG_ 146 VFC_HostLaneRightStatus "Lane status on the right side of this lane";
CM_ SG_ 146 VFC_TargetBasedLateralControl "Horizontal control target type";
CM_ SG_ 146 VFC_HandsoffFuncStatus "Hands-off assisted driving function status";
CM_ SG_ 146 VFC_HandsoffFuncTextinfo "Tips for hands-off assisted driving function information;0xE~0xF=Reserved;";
CM_ SG_ 146 VFC_LLaneMarkerType "Left lane line type";
CM_ SG_ 146 VFC_ELKEnableStatus "Emergency lane remains on and off";
CM_ SG_ 146 VFC_LLLaneDistance "Distance from vehicle center to left-hand lane line;0x0-0x3C=0-12;
0x3D-0x3F=reserved;";
CM_ SG_ 146 VFC_LatPathDY "Distance between horizontal target track and actual track;????,????
DY(N : value of the message) :
   = N ◊ 0.01 , for  0 =N = 511
   = (N-1024) ◊ 0.01 , for N >511
Note:that Clockwise rotation is ë-ë and anti-Clockwise rotation is ë+ë
";
CM_ SG_ 146 VFC_RoadCurvature "Road curvature at current location;????,????
0x0-0x78=-0.03-0.03;
0x79-0x7F=reserved;";
CM_ SG_ 146 VFC_LLLaneDetection "Recognition of left and left lane lines";
CM_ SG_ 146 VFC_LatPathHeadingAngle "Heading angle deviation between lateral target trajectory and actual;????,???? Heading angle (N : value of the message) := N ◊ 0.1 , for  0 =N = 1023= (N-2048) ◊ 0.1 , for N >1023Note:that Clockwise rotation is ë-ë and anti-Clockwise rotation is ë+ë";
CM_ SG_ 146 VFC_Voiceinfo "Driving assistance sound information;0xF~0x1F=reserved";
CM_ SG_ 146 VFC_RRLaneDetection "Right and right lane line recognition;0x0-0x3C=0-12;
0x3D-0x3F=reserved;";
CM_ SG_ 146 VFC_RoadCurvatureNear "Road curvature 50m ahead;0x0-0x78=-0.03-0.03;
0x79-0x7F=reserved;";
CM_ SG_ 147 VFC_0x93_CRC "CRC - Autosar E2E Profile 5";
CM_ SG_ 147 VFC_0x93_AliverCtr "Alive counter - Autosar E2E Profile 5";
CM_ SG_ 147 VFC_LaneQuality "ÁΩÆ‰ø°Â∫¶‰∏∫ÁôæÂàÜÊØîÔºåÊç¢ÁÆóÂÖ¨Âºè‰∏∫0.015625*(0x0~0x3F)";
CM_ SG_ 147 VFC_LaneEquationC1 "Lane line equation coefficient C1;????????:y=C0+C1*x+(1/2)*C2*x^2+(1/6)*C3*x^3,??C1????????????,?????-1+(0x0 ~ 0xFFE)*2^(-11))";
CM_ SG_ 147 VFC_LaneEquationC2 "Lane line equation coefficient C2;????????:y=C0+C1*x+(1/2)*C2*x^2+(1/6)*C3*x^3,??C2??????,?????(-2047 + (0x0 ~ 0xFFE))*2^(-16))";
CM_ SG_ 147 VFC_LaneEquationStatus "Lane line equation state signal";
CM_ SG_ 147 VFC_LaneEquationC3 "Lane line equation coefficient C3;????????:y=C0+C1*x+(1/2)*C2*x^2+(1/6)*C3*x^3,??C3?????????,?????(-2047 + (0x0 ~ 0xFFE))*2^(-21))";
CM_ SG_ 930 VFC_TSR_ASL_CRC "CRC - Autosar E2E Profile 5";
CM_ SG_ 930 VFC_TSR_ASL_AliveCtr "Alive counter - Autosar E2E Profile 5";
CM_ SG_ 930 VFC_ADAS_ModSts_SLA "SLA mode status, from BJEV ASL spec V0.8";
CM_ SG_ 930 VFC_ADAS_SpdLim_SLA "Speed limit value, from BJEV ASL spec V0.8";
CM_ SG_ 930 VFC_ADAS_SpdLimUnit_SLA "Speed limit unit, from BJEV ASL spec V0.8";
BA_DEF_ BO_  "GenMsgSendType" ENUM  "cyclic","NoMsgSendType","IfActive","Event","CA","CE";
BA_DEF_ BO_  "GenMsgCycleTime" INT 0 0;
BA_DEF_ SG_  "GenSigSendType" ENUM  "cyclic","OnChange","OnWrite","IfActive","OnChangeWithRepetition","OnWriteWithRepetition","IfActiveWithRepetition","CA","CE","Event";
BA_DEF_ SG_  "GenSigStartValue" INT 0 0;
BA_DEF_ BO_  "CANFD_BRS" ENUM  "0","1";
BA_DEF_ BO_  "VFrameFormat" ENUM  "StandardCAN","ExtendedCAN","reserved","reserved","reserved","reserved","reserved","reserved","reserved","reserved","reserved","reserved","reserved","reserved","StandardCAN_FD","ExtendedCAN_FD";
BA_DEF_ BO_  "GenMsgILSupport" ENUM  "No","Yes";
BA_DEF_DEF_  "GenMsgSendType" "cyclic";
BA_DEF_DEF_  "GenMsgCycleTime" 0;
BA_DEF_DEF_  "GenSigSendType" "cyclic";
BA_DEF_DEF_  "GenSigStartValue" 0;
BA_DEF_DEF_  "CANFD_BRS" "1";
BA_DEF_DEF_  "VFrameFormat" "";
BA_DEF_DEF_  "GenMsgILSupport" "Yes";
BA_ "GenMsgSendType" BO_ 210 3;
BA_ "VFrameFormat" BO_ 210 14;
BA_ "GenMsgSendType" BO_ 211 3;
BA_ "VFrameFormat" BO_ 211 14;
BA_ "GenMsgSendType" BO_ 212 3;
BA_ "VFrameFormat" BO_ 212 14;
BA_ "GenMsgSendType" BO_ 213 3;
BA_ "VFrameFormat" BO_ 213 14;
BA_ "GenMsgSendType" BO_ 214 3;
BA_ "VFrameFormat" BO_ 214 14;
BA_ "GenMsgSendType" BO_ 215 3;
BA_ "VFrameFormat" BO_ 215 14;
BA_ "GenMsgCycleTime" BO_ 2147483903 500;
BA_ "VFrameFormat" BO_ 2147483903 15;
BA_ "GenMsgSendType" BO_ 256 3;
BA_ "VFrameFormat" BO_ 256 14;
BA_ "GenMsgSendType" BO_ 273 3;
BA_ "VFrameFormat" BO_ 273 14;
BA_ "GenMsgSendType" BO_ 274 3;
BA_ "VFrameFormat" BO_ 274 14;
BA_ "GenMsgSendType" BO_ 275 3;
BA_ "VFrameFormat" BO_ 275 14;
BA_ "GenMsgSendType" BO_ 276 3;
BA_ "VFrameFormat" BO_ 276 14;
BA_ "GenMsgSendType" BO_ 277 3;
BA_ "VFrameFormat" BO_ 277 14;
BA_ "GenMsgSendType" BO_ 278 3;
BA_ "VFrameFormat" BO_ 278 14;
BA_ "GenMsgSendType" BO_ 279 3;
BA_ "VFrameFormat" BO_ 279 14;
BA_ "GenMsgSendType" BO_ 280 3;
BA_ "VFrameFormat" BO_ 280 14;
BA_ "GenMsgSendType" BO_ 281 3;
BA_ "VFrameFormat" BO_ 281 14;
BA_ "GenMsgSendType" BO_ 288 3;
BA_ "VFrameFormat" BO_ 288 14;
BA_ "GenMsgSendType" BO_ 289 3;
BA_ "VFrameFormat" BO_ 289 14;
BA_ "GenMsgSendType" BO_ 290 3;
BA_ "VFrameFormat" BO_ 290 14;
BA_ "GenMsgSendType" BO_ 291 3;
BA_ "VFrameFormat" BO_ 291 14;
BA_ "GenMsgSendType" BO_ 292 3;
BA_ "VFrameFormat" BO_ 292 14;
BA_ "GenMsgSendType" BO_ 293 3;
BA_ "VFrameFormat" BO_ 293 14;
BA_ "GenMsgSendType" BO_ 304 3;
BA_ "VFrameFormat" BO_ 304 14;
BA_ "GenMsgSendType" BO_ 305 3;
BA_ "VFrameFormat" BO_ 305 14;
BA_ "GenMsgSendType" BO_ 306 3;
BA_ "VFrameFormat" BO_ 306 14;
BA_ "GenMsgSendType" BO_ 307 3;
BA_ "VFrameFormat" BO_ 307 14;
BA_ "GenMsgSendType" BO_ 308 3;
BA_ "VFrameFormat" BO_ 308 14;
BA_ "GenMsgSendType" BO_ 309 3;
BA_ "VFrameFormat" BO_ 309 14;
BA_ "GenMsgSendType" BO_ 310 3;
BA_ "VFrameFormat" BO_ 310 14;
BA_ "GenMsgSendType" BO_ 311 3;
BA_ "VFrameFormat" BO_ 311 14;
BA_ "GenMsgSendType" BO_ 312 3;
BA_ "VFrameFormat" BO_ 312 14;
BA_ "GenMsgSendType" BO_ 313 3;
BA_ "VFrameFormat" BO_ 313 14;
BA_ "GenMsgSendType" BO_ 320 3;
BA_ "VFrameFormat" BO_ 320 14;
BA_ "GenMsgSendType" BO_ 321 3;
BA_ "VFrameFormat" BO_ 321 14;
BA_ "GenMsgSendType" BO_ 322 3;
BA_ "VFrameFormat" BO_ 322 14;
BA_ "GenMsgSendType" BO_ 323 3;
BA_ "VFrameFormat" BO_ 323 14;
BA_ "GenMsgSendType" BO_ 324 3;
BA_ "VFrameFormat" BO_ 324 14;
BA_ "GenMsgSendType" BO_ 325 3;
BA_ "VFrameFormat" BO_ 325 14;
BA_ "GenMsgSendType" BO_ 326 3;
BA_ "VFrameFormat" BO_ 326 14;
BA_ "GenMsgSendType" BO_ 327 3;
BA_ "VFrameFormat" BO_ 327 14;
BA_ "GenMsgSendType" BO_ 328 3;
BA_ "VFrameFormat" BO_ 328 14;
BA_ "GenMsgSendType" BO_ 329 3;
BA_ "VFrameFormat" BO_ 329 14;
BA_ "GenMsgSendType" BO_ 336 3;
BA_ "VFrameFormat" BO_ 336 14;
BA_ "GenMsgSendType" BO_ 337 3;
BA_ "VFrameFormat" BO_ 337 14;
BA_ "GenMsgSendType" BO_ 338 3;
BA_ "VFrameFormat" BO_ 338 14;
BA_ "GenMsgSendType" BO_ 339 3;
BA_ "VFrameFormat" BO_ 339 14;
BA_ "GenMsgSendType" BO_ 340 3;
BA_ "VFrameFormat" BO_ 340 14;
BA_ "GenMsgSendType" BO_ 341 3;
BA_ "VFrameFormat" BO_ 341 14;
BA_ "GenMsgCycleTime" BO_ 137 10;
BA_ "VFrameFormat" BO_ 137 14;
BA_ "GenMsgCycleTime" BO_ 148 20;
BA_ "VFrameFormat" BO_ 148 14;
BA_ "GenMsgCycleTime" BO_ 145 100;
BA_ "VFrameFormat" BO_ 145 14;
BA_ "GenMsgCycleTime" BO_ 146 100;
BA_ "VFrameFormat" BO_ 146 14;
BA_ "GenMsgCycleTime" BO_ 147 100;
BA_ "VFrameFormat" BO_ 147 14;
BA_ "GenMsgCycleTime" BO_ 930 100;
BA_ "VFrameFormat" BO_ 930 14;
BA_ "GenMsgCycleTime" BO_ 2281601536 20;
BA_ "VFrameFormat" BO_ 2281601536 15;
BA_ "GenSigStartValue" SG_ 210 VFC_Obj17A_PhiLeft 4000;
BA_ "GenSigStartValue" SG_ 210 VFC_Obj17A_Heading 157;
BA_ "GenSigStartValue" SG_ 210 VFC_Obj17A_PhiMid 4000;
BA_ "GenSigStartValue" SG_ 210 VFC_Obj17A_PhiRight 4000;
BA_ "GenSigStartValue" SG_ 210 VFC_Obj17A_PhiLeftVel 4000;
BA_ "GenSigStartValue" SG_ 210 VFC_Obj17A_PhiRightVel 4000;
BA_ "GenSigStartValue" SG_ 210 VFC_Obj17A_PhiTop 1600;
BA_ "GenSigStartValue" SG_ 210 VFC_Obj17A_PhiBottom 1600;
BA_ "GenSigStartValue" SG_ 210 VFC_Obj17A_Ax 160;
BA_ "GenSigStartValue" SG_ 210 VFC_Obj17A_NormVx 40000;
BA_ "GenSigStartValue" SG_ 210 VFC_Obj17A_NormAx 5000;
BA_ "GenSigStartValue" SG_ 210 VFC_Obj17A_Vx 1540;
BA_ "GenSigStartValue" SG_ 210 VFC_Obj17A_Dy 8000;
BA_ "GenSigStartValue" SG_ 210 VFC_Obj17A_Vy 500;
BA_ "GenSigStartValue" SG_ 210 VFC_Obj17A_Ay 120;
BA_ "GenSigStartValue" SG_ 211 VFC_Obj17B_LineEdgeAngle 4000;
BA_ "GenSigStartValue" SG_ 211 VFC_Obj17B_AngLongitude 500;
BA_ "GenSigStartValue" SG_ 212 VFC_Obj18A_PhiLeft 4000;
BA_ "GenSigStartValue" SG_ 212 VFC_Obj18A_Heading 157;
BA_ "GenSigStartValue" SG_ 212 VFC_Obj18A_PhiMid 4000;
BA_ "GenSigStartValue" SG_ 212 VFC_Obj18A_PhiRight 4000;
BA_ "GenSigStartValue" SG_ 212 VFC_Obj18A_PhiLeftVel 4000;
BA_ "GenSigStartValue" SG_ 212 VFC_Obj18A_PhiRightVel 4000;
BA_ "GenSigStartValue" SG_ 212 VFC_Obj18A_PhiTop 1600;
BA_ "GenSigStartValue" SG_ 212 VFC_Obj18A_PhiBottom 1600;
BA_ "GenSigStartValue" SG_ 212 VFC_Obj18A_Ax 160;
BA_ "GenSigStartValue" SG_ 212 VFC_Obj18A_NormVx 40000;
BA_ "GenSigStartValue" SG_ 212 VFC_Obj18A_NormAx 5000;
BA_ "GenSigStartValue" SG_ 212 VFC_Obj18A_Vx 1540;
BA_ "GenSigStartValue" SG_ 212 VFC_Obj18A_Dy 8000;
BA_ "GenSigStartValue" SG_ 212 VFC_Obj18A_Vy 500;
BA_ "GenSigStartValue" SG_ 212 VFC_Obj18A_Ay 120;
BA_ "GenSigStartValue" SG_ 213 VFC_Obj18B_LineEdgeAngle 4000;
BA_ "GenSigStartValue" SG_ 213 VFC_Obj18B_AngLongitude 500;
BA_ "GenSigStartValue" SG_ 214 VFC_Obj19A_PhiLeft 4000;
BA_ "GenSigStartValue" SG_ 214 VFC_Obj19A_Heading 157;
BA_ "GenSigStartValue" SG_ 214 VFC_Obj19A_PhiMid 4000;
BA_ "GenSigStartValue" SG_ 214 VFC_Obj19A_PhiRight 4000;
BA_ "GenSigStartValue" SG_ 214 VFC_Obj19A_PhiLeftVel 4000;
BA_ "GenSigStartValue" SG_ 214 VFC_Obj19A_PhiRightVel 4000;
BA_ "GenSigStartValue" SG_ 214 VFC_Obj19A_PhiTop 1600;
BA_ "GenSigStartValue" SG_ 214 VFC_Obj19A_PhiBottom 1600;
BA_ "GenSigStartValue" SG_ 214 VFC_Obj19A_Ax 160;
BA_ "GenSigStartValue" SG_ 214 VFC_Obj19A_NormVx 40000;
BA_ "GenSigStartValue" SG_ 214 VFC_Obj19A_NormAx 5000;
BA_ "GenSigStartValue" SG_ 214 VFC_Obj19A_Vx 1540;
BA_ "GenSigStartValue" SG_ 214 VFC_Obj19A_Dy 8000;
BA_ "GenSigStartValue" SG_ 214 VFC_Obj19A_Vy 500;
BA_ "GenSigStartValue" SG_ 214 VFC_Obj19A_Ay 120;
BA_ "GenSigStartValue" SG_ 215 VFC_Obj19B_LineEdgeAngle 4000;
BA_ "GenSigStartValue" SG_ 215 VFC_Obj19B_AngLongitude 500;
BA_ "GenSigStartValue" SG_ 288 OnComingObj0_dxv_sw 32000;
BA_ "GenSigStartValue" SG_ 289 OnComingObj1_dxv_sw 32000;
BA_ "GenSigStartValue" SG_ 290 OnComingObj2_dxv_sw 32000;
BA_ "GenSigStartValue" SG_ 291 OnComingObj3_dxv_sw 32000;
BA_ "GenSigStartValue" SG_ 292 OnGoingObj0_dxv_sw 32000;
BA_ "GenSigStartValue" SG_ 293 OnGoingObj1_dxv_sw 32000;
BA_ "GenSigStartValue" SG_ 137 VFC_MotorTorqueMaxLimitRequest 1024;
BA_ "GenSigStartValue" SG_ 137 VFC_MotorTorqueMinLimitRequest 1024;
BA_ "GenSigStartValue" SG_ 145 Selflearning_angle 1025;
BA_ "GenSigStartValue" SG_ 145 VFC_LLaneDistanceFusion 36;
BA_ "GenSigStartValue" SG_ 145 VFC_RLaneDistanceFusion 36;
BA_ "GenSigStartValue" SG_ 146 VFC_LASModeSelectionStatus 1;
BA_ "GenSigStartValue" SG_ 146 VFC_RLaneMarkerType 7;
BA_ "GenSigStartValue" SG_ 146 VFC_RoadCurvatureFar 60;
BA_ "GenSigStartValue" SG_ 146 VFC_RRLaneDistance 28;
BA_ "GenSigStartValue" SG_ 146 VFC_LASWarningModeSelectionSts 2;
BA_ "GenSigStartValue" SG_ 146 VFC_LDWShakeLevStatus 2;
BA_ "GenSigStartValue" SG_ 146 VFC_LLaneMarkerType 7;
BA_ "GenSigStartValue" SG_ 146 VFC_LLLaneDistance 28;
BA_ "GenSigStartValue" SG_ 146 VFC_RoadCurvature 60;
BA_ "GenSigStartValue" SG_ 146 VFC_RoadCurvatureNear 60;
BA_ "GenSigStartValue" SG_ 147 VFC_LaneEquationC1 2047;
BA_ "GenSigStartValue" SG_ 147 VFC_LaneEquationC2 2047;
BA_ "GenSigStartValue" SG_ 147 VFC_LaneEquationC3 2047;
BA_ "GenSigStartValue" SG_ 930 LAS_OverspeedWarningOffset 10;

VAL_ 210 VFC_Obj17A_ClassifiedView 0 "Unknown" 1 "Front" 2 "Rear" 3 "Left" 4 "Right" ;
VAL_ 210 VFC_Obj17A_Measured 0 "Invalid" 1 "Predicted" 2 "Measured" 3 "Reserved" ;
VAL_ 210 VFC_Obj17A_VisibleView 0 "UNKNOWN" 1 "CLASSIC" 2 "SIDE" 3 "CLASSIC_SIDE" 4 "SIDE_CLASSIC" ;

VAL_ 210 VFC_Obj17A_HeadOrientation 14 "Reserved 2" 13 "Reserved 1" 12 "Head oppo left back right front" 11 "Head oppo left right" 10 "Head oppo let front right back" 9 "Head oppo front back " 0 "N/A" 1 "Head front" 2 "Head left front" 3 "Head left" 4 "Head left back" 5 "Head back" 6 "Head right back" 7 "Head right" 8 "Head right front" 15 "Unknown" ;

VAL_ 210 VFC_Obj17A_Type 0 "No type" 1 "Car" 2 "Truck" 3 "Motorcycle" 4 "Pedestrian" 5 "Cyclist" 6 "Animal" ;
VAL_ 211 VFC_Obj17B_LineEdgeRightEgo 0 "Right" 1 "Not Right" ;
VAL_ 211 VFC_Obj17B_LineEdgeLeftEgo 0 "Left" 1 "Not Left" ;
VAL_ 211 VFC_Obj17B_CompletelyInImg 0 "completely measured" 1 "not completely measured" ;
VAL_ 211 VFC_Obj17B_DirIndicator 0 "No direction indicator" 1 "Left indicator" 2 "Right indicator" 3 "Warning Lights" 4 "Unknown" ;
VAL_ 211 VFC_Obj17B_BrakeLight 0 "No light detected" 1 "One light detected" 2 "Two lights detected" 3 "Three lights detected" 4 "Unknown" ;

VAL_ 211 VFC_Obj17B_MeasSource 15 "Source_INVALID" 11 "Source_OLS" 10 "Source_FUSED" 0 "Source_GOD_Stereo" 1 "Source_MOD" 2 "Source_PDET" 4 "Source_GOD_MONO" ;

VAL_ 212 VFC_Obj18A_ClassifiedView 0 "Unknown" 1 "Front" 2 "Rear" 3 "Left" 4 "Right" ;
VAL_ 212 VFC_Obj18A_Measured 0 "Invalid" 1 "Predicted" 2 "Measured" 3 "Reserved" ;
VAL_ 212 VFC_Obj18A_VisibleView 0 "UNKNOWN" 1 "CLASSIC" 2 "SIDE" 3 "CLASSIC_SIDE" 4 "SIDE_CLASSIC" ;
VAL_ 212 VFC_Obj18A_HeadOrientation 14 "Reserved 2" 13 "Reserved 1" 12 "Head oppo left back right front" 11 "Head oppo left right" 10 "Head oppo let front right back" 9 "Head oppo front back " 0 "N/A" 1 "Head front" 2 "Head left front" 3 "Head left" 4 "Head left back" 5 "Head back" 6 "Head right back" 7 "Head right" 8 "Head right front" 15 "Unknown" ;

VAL_ 212 VFC_Obj18A_Type 0 "No type" 1 "Car" 2 "Truck" 3 "Motorcycle" 4 "Pedestrian" 5 "Cyclist" 6 "Animal" ;
VAL_ 213 VFC_Obj18B_LineEdgeRightEgo 0 "Right" 1 "Not Right" ;
VAL_ 213 VFC_Obj18B_LineEdgeLeftEgo 0 "Left" 1 "Not Left" ;
VAL_ 213 VFC_Obj18B_CompletelyInImg 0 "completely measured" 1 "not completely measured" ;
VAL_ 213 VFC_Obj18B_DirIndicator 0 "No direction indicator" 1 "Left indicator" 2 "Right indicator" 3 "Warning Lights" 4 "Unknown" ;
VAL_ 213 VFC_Obj18B_BrakeLight 0 "No light detected" 1 "One light detected" 2 "Two lights detected" 3 "Three lights detected" 4 "Unknown" ;

VAL_ 213 VFC_Obj18B_MeasSource 15 "Source_INVALID" 11 "Source_OLS" 10 "Source_FUSED" 0 "Source_GOD_Stereo" 1 "Source_MOD" 2 "Source_PDET" 4 "Source_GOD_MONO" ;

VAL_ 214 VFC_Obj19A_ClassifiedView 0 "Unknown" 1 "Front" 2 "Rear" 3 "Left" 4 "Right" ;
VAL_ 214 VFC_Obj19A_Measured 0 "Invalid" 1 "Predicted" 2 "Measured" 3 "Reserved" ;
VAL_ 214 VFC_Obj19A_VisibleView 0 "UNKNOWN" 1 "CLASSIC" 2 "SIDE" 3 "CLASSIC_SIDE" 4 "SIDE_CLASSIC" ;

VAL_ 214 VFC_Obj19A_HeadOrientation 14 "Reserved 2" 13 "Reserved 1" 12 "Head oppo left back right front" 11 "Head oppo left right" 10 "Head oppo let front right back" 9 "Head oppo front back " 0 "N/A" 1 "Head front" 2 "Head left front" 3 "Head left" 4 "Head left back" 5 "Head back" 6 "Head right back" 7 "Head right" 8 "Head right front" 15 "Unknown" ;

VAL_ 214 VFC_Obj19A_Type 0 "No type" 1 "Car" 2 "Truck" 3 "Motorcycle" 4 "Pedestrian" 5 "Cyclist" 6 "Animal" ;
VAL_ 215 VFC_Obj19B_LineEdgeRightEgo 0 "Right" 1 "Not Right" ;
VAL_ 215 VFC_Obj19B_LineEdgeLeftEgo 0 "Left" 1 "Not Left" ;
VAL_ 215 VFC_Obj19B_CompletelyInImg 0 "completely measured" 1 "not completely measured" ;
VAL_ 215 VFC_Obj19B_DirIndicator 0 "No direction indicator" 1 "Left indicator" 2 "Right indicator" 3 "Warning Lights" 4 "Unknown" ;
VAL_ 215 VFC_Obj19B_BrakeLight 0 "No light detected" 1 "One light detected" 2 "Two lights detected" 3 "Three lights detected" 4 "Unknown" ;

VAL_ 215 VFC_Obj19B_MeasSource 15 "Source_INVALID" 11 "Source_OLS" 10 "Source_FUSED" 0 "Source_GOD_Stereo" 1 "Source_MOD" 2 "Source_PDET" 4 "Source_GOD_MONO" ;

VAL_ 256 Status_AvoidCollision 3 "reserve" 2 "RightAvoid" 1 "LeftAvoid" 0 "None" ;
VAL_ 256 ACC_ExitReason 7 "Reserved" 6 "Reserved" 5 "Reserved" 4 "Reserved" 3 "Others" 2 "Brake" 1 "ACC_Cancel" 0 "None" ;
VAL_ 256 StatusACC 0 "OFF MODE" 1 "PASSIVE MODE" 2 "STANDBY MODE" 3 "ACTIVE CONTROL MODE" 4 "BRAKE ONLY MODE" 5 "OVERRIDE" 6 "STAND ACTIVE" 7 "STAND WAIT" 8 "TEMPORARY FAILURE" 9 "PERMANENT FAILURE" ;
VAL_ 288 OnComingObj0_Handle_ub 0 "object is invalid" ;
VAL_ 288 OnComingObj0_RFF_ub 0 "not fused with video" 1 "fused with video" ;
VAL_ 289 OnComingObj1_Handle_ub 0 "object is invalid" ;
VAL_ 289 OnComingObj1_RFF_ub 0 "not fused with video" 1 "fused with video" ;
VAL_ 290 OnComingObj2_Handle_ub 0 "object is invalid" ;
VAL_ 290 OnComingObj2_RFF_ub 0 "not fused with video" 1 "fused with video" ;
VAL_ 291 OnComingObj3_Handle_ub 0 "object is invalid" ;
VAL_ 291 OnComingObj3_RFF_ub 0 "not fused with video" 1 "fused with video" ;
VAL_ 292 OnGoingObj0_Handle_ub 0 "object is invalid" ;
VAL_ 292 OnGoingObj0_RFF_ub 0 "not fused with video" 1 "fused with video" ;
VAL_ 293 OnGoingObj1_Handle_ub 0 "object is invalid" ;
VAL_ 293 OnGoingObj1_RFF_ub 0 "not fused with video" 1 "fused with video" ;
VAL_ 304 TrajPointACCObj0_Valid_b 0 "not existent in last cycle" 1 "existent in last cycle" ;
VAL_ 304 TrajPointACCObj0_Drive_b 0 "not driving in same direction" 1 "driving in same direction" ;
VAL_ 304 TrajPointACCObj0_Stand_b 0 "not Standing" 1 "standing" ;
VAL_ 304 TrajPointACCObj0_InvDir_b 0 "Not opposite dir/Not stopped" 1 "Opposite dir/stopped" ;
VAL_ 304 TrajPointACCObj0_Stopped_b 0 "not stopped" 1 "stopped" ;
VAL_ 304 TrajPointACCObj0_TrajEnd_b 0 "not measured" 1 "measured" ;
VAL_ 305 TrajPointACCObj1_Valid_b 0 "not existent in last cycle" 1 "existent in last cycle" ;
VAL_ 305 TrajPointACCObj1_Drive_b 0 "not driving in same direction" 1 "driving in same direction" ;
VAL_ 305 TrajPointACCObj1_Stand_b 0 "not Standing" 1 "standing" ;
VAL_ 305 TrajPointACCObj1_InvDir_b 0 "Not opposite dir/Not stopped" 1 "Opposite dir/stopped" ;
VAL_ 305 TrajPointACCObj1_Stopped_b 0 "not stopped" 1 "stopped" ;
VAL_ 305 TrajPointACCObj1_TrajEnd_b 0 "not measured" 1 "measured" ;
VAL_ 306 TrajPointACCObj2_Valid_b 0 "not existent in last cycle" 1 "existent in last cycle" ;
VAL_ 306 TrajPointACCObj2_Drive_b 0 "not driving in same direction" 1 "driving in same direction" ;
VAL_ 306 TrajPointACCObj2_Stand_b 0 "not Standing" 1 "standing" ;
VAL_ 306 TrajPointACCObj2_InvDir_b 0 "Not opposite dir/Not stopped" 1 "Opposite dir/stopped" ;
VAL_ 306 TrajPointACCObj2_Stopped_b 0 "not stopped" 1 "stopped" ;
VAL_ 306 TrajPointACCObj2_TrajEnd_b 0 "not measured" 1 "measured" ;
VAL_ 307 TrajPointACCObj3_Valid_b 0 "not existent in last cycle" 1 "existent in last cycle" ;
VAL_ 307 TrajPointACCObj3_Drive_b 0 "not driving in same direction" 1 "driving in same direction" ;
VAL_ 307 TrajPointACCObj3_Stand_b 0 "not Standing" 1 "standing" ;
VAL_ 307 TrajPointACCObj3_InvDir_b 0 "Not opposite dir/Not stopped" 1 "Opposite dir/stopped" ;
VAL_ 307 TrajPointACCObj3_Stopped_b 0 "not stopped" 1 "stopped" ;
VAL_ 307 TrajPointACCObj3_TrajEnd_b 0 "not measured" 1 "measured" ;
VAL_ 308 TrajPointACCObj4_Valid_b 0 "not existent in last cycle" 1 "existent in last cycle" ;
VAL_ 308 TrajPointACCObj4_Drive_b 0 "not driving in same direction" 1 "driving in same direction" ;
VAL_ 308 TrajPointACCObj4_Stand_b 0 "not Standing" 1 "standing" ;
VAL_ 308 TrajPointACCObj4_InvDir_b 0 "Not opposite dir/Not stopped" 1 "Opposite dir/stopped" ;
VAL_ 308 TrajPointACCObj4_Stopped_b 0 "not stopped" 1 "stopped" ;
VAL_ 308 TrajPointACCObj4_TrajEnd_b 0 "not measured" 1 "measured" ;
VAL_ 309 TrajPointACCObj5_Valid_b 0 "not existent in last cycle" 1 "existent in last cycle" ;
VAL_ 309 TrajPointACCObj5_Drive_b 0 "not driving in same direction" 1 "driving in same direction" ;
VAL_ 309 TrajPointACCObj5_Stand_b 0 "not Standing" 1 "standing" ;
VAL_ 309 TrajPointACCObj5_InvDir_b 0 "Not opposite dir/Not stopped" 1 "Opposite dir/stopped" ;
VAL_ 309 TrajPointACCObj5_Stopped_b 0 "not stopped" 1 "stopped" ;
VAL_ 309 TrajPointACCObj5_TrajEnd_b 0 "not measured" 1 "measured" ;
VAL_ 310 TrajPointACCObj6_Valid_b 0 "not existent in last cycle" 1 "existent in last cycle" ;
VAL_ 310 TrajPointACCObj6_Stand_b 0 "not Standing" 1 "standing" ;
VAL_ 310 TrajPointACCObj6_Drive_b 0 "not driving in same direction" 1 "driving in same direction" ;
VAL_ 310 TrajPointACCObj6_InvDir_b 0 "Not opposite dir/Not stopped" 1 "Opposite dir/stopped" ;
VAL_ 310 TrajPointACCObj6_Stopped_b 0 "not stopped" 1 "stopped" ;
VAL_ 310 TrajPointACCObj6_TrajEnd_b 0 "not measured" 1 "measured" ;
VAL_ 311 TrajPointACCObj7_Valid_b 0 "not existent in last cycle" 1 "existent in last cycle" ;
VAL_ 311 TrajPointACCObj7_Drive_b 0 "not driving in same direction" 1 "driving in same direction" ;
VAL_ 311 TrajPointACCObj7_Stand_b 0 "not Standing" 1 "standing" ;
VAL_ 311 TrajPointACCObj7_InvDir_b 0 "Not opposite dir/Not stopped" 1 "Opposite dir/stopped" ;
VAL_ 311 TrajPointACCObj7_Stopped_b 0 "not stopped" 1 "stopped" ;
VAL_ 311 TrajPointACCObj7_TrajEnd_b 0 "not measured" 1 "measured" ;
VAL_ 312 TrajPointACCObj8_Valid_b 0 "not existent in last cycle" 1 "existent in last cycle" ;
VAL_ 312 TrajPointACCObj8_Drive_b 0 "not driving in same direction" 1 "driving in same direction" ;
VAL_ 312 TrajPointACCObj8_Stand_b 0 "not Standing" 1 "standing" ;
VAL_ 312 TrajPointACCObj8_InvDir_b 0 "Not opposite dir/Not stopped" 1 "Opposite dir/stopped" ;
VAL_ 312 TrajPointACCObj8_Stopped_b 0 "not stopped" 1 "stopped" ;
VAL_ 312 TrajPointACCObj8_TrajEnd_b 0 "not measured" 1 "measured" ;
VAL_ 313 TrajPointACCObj9_Valid_b 0 "not existent in last cycle" 1 "existent in last cycle" ;
VAL_ 313 TrajPointACCObj9_Drive_b 0 "not driving in same direction" 1 "driving in same direction" ;
VAL_ 313 TrajPointACCObj9_Stand_b 0 "not Standing" 1 "standing" ;
VAL_ 313 TrajPointACCObj9_InvDir_b 0 "Not opposite dir/Not stopped" 1 "Opposite dir/stopped" ;
VAL_ 313 TrajPointACCObj9_Stopped_b 0 "not stopped" 1 "stopped" ;
VAL_ 313 TrajPointACCObj9_TrajEnd_b 0 "not measured" 1 "measured" ;
VAL_ 320 TrajPointACCObj10_Valid_b 0 "not existent in last cycle" 1 "existent in last cycle" ;
VAL_ 320 TrajPointACCObj10_Drive_b 0 "not driving in same direction" 1 "driving in same direction" ;
VAL_ 320 TrajPointACCObj10_Stand_b 0 "not Standing" 1 "standing" ;
VAL_ 320 TrajPointACCObj10_InvDir_b 0 "Not opposite dir/Not stopped" 1 "Opposite dir/stopped" ;
VAL_ 320 TrajPointACCObj10_Stopped_b 0 "not stopped" 1 "stopped" ;
VAL_ 320 TrajPointACCObj10_TrajEnd_b 0 "not measured" 1 "measured" ;
VAL_ 321 TrajPointACCObj11_Valid_b 0 "not existent in last cycle" 1 "existent in last cycle" ;
VAL_ 321 TrajPointACCObj11_Drive_b 0 "not driving in same direction" 1 "driving in same direction" ;
VAL_ 321 TrajPointACCObj11_Stand_b 0 "not Standing" 1 "standing" ;
VAL_ 321 TrajPointACCObj11_InvDir_b 0 "Not opposite dir/Not stopped" 1 "Opposite dir/stopped" ;
VAL_ 321 TrajPointACCObj11_Stopped_b 0 "not stopped" 1 "stopped" ;
VAL_ 321 TrajPointACCObj11_TrajEnd_b 0 "not measured" 1 "measured" ;
VAL_ 322 TrajPointACCObj12_Valid_b 0 "not existent in last cycle" 1 "existent in last cycle" ;
VAL_ 322 TrajPointACCObj12_Drive_b 0 "not driving in same direction" 1 "driving in same direction" ;
VAL_ 322 TrajPointACCObj12_Stand_b 0 "not Standing" 1 "standing" ;
VAL_ 322 TrajPointACCObj12_InvDir_b 0 "Not opposite dir/Not stopped" 1 "Opposite dir/stopped" ;
VAL_ 322 TrajPointACCObj12_Stopped_b 0 "not stopped" 1 "stopped" ;
VAL_ 322 TrajPointACCObj12_TrajEnd_b 0 "not measured" 1 "measured" ;
VAL_ 323 TrajPointACCObj13_Valid_b 0 "not existent in last cycle" 1 "existent in last cycle" ;
VAL_ 323 TrajPointACCObj13_Drive_b 0 "not driving in same direction" 1 "driving in same direction" ;
VAL_ 323 TrajPointACCObj13_Stand_b 0 "not Standing" 1 "standing" ;
VAL_ 323 TrajPointACCObj13_InvDir_b 0 "Not opposite dir/Not stopped" 1 "Opposite dir/stopped" ;
VAL_ 323 TrajPointACCObj13_Stopped_b 0 "not stopped" 1 "stopped" ;
VAL_ 323 TrajPointACCObj13_TrajEnd_b 0 "not measured" 1 "measured" ;
VAL_ 324 TrajPointACCObj14_Valid_b 0 "not existent in last cycle" 1 "existent in last cycle" ;
VAL_ 324 TrajPointACCObj14_Drive_b 0 "not driving in same direction" 1 "driving in same direction" ;
VAL_ 324 TrajPointACCObj14_Stand_b 0 "not Standing" 1 "standing" ;
VAL_ 324 TrajPointACCObj14_InvDir_b 0 "Not opposite dir/Not stopped" 1 "Opposite dir/stopped" ;
VAL_ 324 TrajPointACCObj14_Stopped_b 0 "not stopped" 1 "stopped" ;
VAL_ 324 TrajPointACCObj14_TrajEnd_b 0 "not measured" 1 "measured" ;
VAL_ 325 TrajPointACCObj15_Valid_b 0 "not existent in last cycle" 1 "existent in last cycle" ;
VAL_ 325 TrajPointACCObj15_Drive_b 0 "not driving in same direction" 1 "driving in same direction" ;
VAL_ 325 TrajPointACCObj15_Stand_b 0 "not Standing" 1 "standing" ;
VAL_ 325 TrajPointACCObj15_InvDir_b 0 "Not opposite dir/Not stopped" 1 "Opposite dir/stopped" ;
VAL_ 325 TrajPointACCObj15_Stopped_b 0 "not stopped" 1 "stopped" ;
VAL_ 325 TrajPointACCObj15_TrajEnd_b 0 "not measured" 1 "measured" ;
VAL_ 326 TrajPointACCObj16_Valid_b 0 "not existent in last cycle" 1 "existent in last cycle" ;
VAL_ 326 TrajPointACCObj16_Drive_b 0 "not driving in same direction" 1 "driving in same direction" ;
VAL_ 326 TrajPointACCObj16_Stand_b 0 "not Standing" 1 "standing" ;
VAL_ 326 TrajPointACCObj16_InvDir_b 0 "Not opposite dir/Not stopped" 1 "Opposite dir/stopped" ;
VAL_ 326 TrajPointACCObj16_Stopped_b 0 "not stopped" 1 "stopped" ;
VAL_ 326 TrajPointACCObj16_TrajEnd_b 0 "not measured" 1 "measured" ;
VAL_ 327 TrajPointACCObj17_Valid_b 0 "not existent in last cycle" 1 "existent in last cycle" ;
VAL_ 327 TrajPointACCObj17_Drive_b 0 "not driving in same direction" 1 "driving in same direction" ;
VAL_ 327 TrajPointACCObj17_Stand_b 0 "not Standing" 1 "standing" ;
VAL_ 327 TrajPointACCObj17_InvDir_b 0 "Not opposite dir/Not stopped" 1 "Opposite dir/stopped" ;
VAL_ 327 TrajPointACCObj17_Stopped_b 0 "not stopped" 1 "stopped" ;
VAL_ 327 TrajPointACCObj17_TrajEnd_b 0 "not measured" 1 "measured" ;
VAL_ 328 TrajPointACCObj18_Valid_b 0 "not existent in last cycle" 1 "existent in last cycle" ;
VAL_ 328 TrajPointACCObj18_Drive_b 0 "not driving in same direction" 1 "driving in same direction" ;
VAL_ 328 TrajPointACCObj18_Stand_b 0 "not Standing" 1 "standing" ;
VAL_ 328 TrajPointACCObj18_InvDir_b 0 "Not opposite dir/Not stopped" 1 "Opposite dir/stopped" ;
VAL_ 328 TrajPointACCObj18_Stopped_b 0 "not stopped" 1 "stopped" ;
VAL_ 328 TrajPointACCObj18_TrajEnd_b 0 "not measured" 1 "measured" ;
VAL_ 329 TrajPointACCObj19_Valid_b 0 "not existent in last cycle" 1 "existent in last cycle" ;
VAL_ 329 TrajPointACCObj19_Drive_b 0 "not driving in same direction" 1 "driving in same direction" ;
VAL_ 329 TrajPointACCObj19_Stand_b 0 "not Standing" 1 "standing" ;
VAL_ 329 TrajPointACCObj19_InvDir_b 0 "Not opposite dir/Not stopped" 1 "Opposite dir/stopped" ;
VAL_ 329 TrajPointACCObj19_Stopped_b 0 "not stopped" 1 "stopped" ;
VAL_ 329 TrajPointACCObj19_TrajEnd_b 0 "not measured" 1 "measured" ;
VAL_ 336 TrajPointACCObj20_Valid_b 0 "not existent in last cycle" 1 "existent in last cycle" ;
VAL_ 336 TrajPointACCObj20_Drive_b 0 "not driving in same direction" 1 "driving in same direction" ;
VAL_ 336 TrajPointACCObj20_Stand_b 0 "not Standing" 1 "standing" ;
VAL_ 336 TrajPointACCObj20_InvDir_b 0 "Not opposite dir/Not stopped" 1 "Opposite dir/stopped" ;
VAL_ 336 TrajPointACCObj20_Stopped_b 0 "not stopped" 1 "stopped" ;
VAL_ 336 TrajPointACCObj20_TrajEnd_b 0 "not measured" 1 "measured" ;
VAL_ 337 TrajPointACCObj21_Valid_b 0 "not existent in last cycle" 1 "existent in last cycle" ;
VAL_ 337 TrajPointACCObj21_Drive_b 0 "not driving in same direction" 1 "driving in same direction" ;
VAL_ 337 TrajPointACCObj21_Stand_b 0 "not Standing" 1 "standing" ;
VAL_ 337 TrajPointACCObj21_InvDir_b 0 "Not opposite dir/Not stopped" 1 "Opposite dir/stopped" ;
VAL_ 337 TrajPointACCObj21_Stopped_b 0 "not stopped" 1 "stopped" ;
VAL_ 337 TrajPointACCObj21_TrajEnd_b 0 "not measured" 1 "measured" ;
VAL_ 338 TrajPointACCObj22_Valid_b 0 "not existent in last cycle" 1 "existent in last cycle" ;
VAL_ 338 TrajPointACCObj22_Drive_b 0 "not driving in same direction" 1 "driving in same direction" ;
VAL_ 338 TrajPointACCObj22_Stand_b 0 "not Standing" 1 "standing" ;
VAL_ 338 TrajPointACCObj22_InvDir_b 0 "Not opposite dir/Not stopped" 1 "Opposite dir/stopped" ;
VAL_ 338 TrajPointACCObj22_Stopped_b 0 "not stopped" 1 "stopped" ;
VAL_ 338 TrajPointACCObj22_TrajEnd_b 0 "not measured" 1 "measured" ;
VAL_ 339 TrajPointACCObj23_Valid_b 0 "not existent in last cycle" 1 "existent in last cycle" ;
VAL_ 339 TrajPointACCObj23_Drive_b 0 "not driving in same direction" 1 "driving in same direction" ;
VAL_ 339 TrajPointACCObj23_Stand_b 0 "not Standing" 1 "standing" ;
VAL_ 339 TrajPointACCObj23_InvDir_b 0 "Not opposite dir/Not stopped" 1 "Opposite dir/stopped" ;
VAL_ 339 TrajPointACCObj23_Stopped_b 0 "not stopped" 1 "stopped" ;
VAL_ 339 TrajPointACCObj23_TrajEnd_b 0 "not measured" 1 "measured" ;
VAL_ 340 ACCObjInfo_Handle_ub 0 "object is invalid" ;
VAL_ 340 ACCObjInfo_RFF_ub 0 "not fused with video" 1 "fused with video" ;
VAL_ 137 VFC_MotorTorqueMaxLimitRequest 2047 "Reserved" ;
VAL_ 137 VFC_MotorTorqueMinLimitRequest 2047 "Reserved" ;
VAL_ 137 VFC_LatAngReqActive 0 "not active" 1 "active" ;
VAL_ 137 VFC_LatAngReq 14410 "Reseverd" ;
VAL_ 148 VFC_LDWStatus 0 "off" 1 "Standby" 2 "Active" 3 "Failure" ;
VAL_ 148 VFC_LDWVibrationWarningReq 0 "No Warming" 1 "Left Warming" 2 "Right Warming" 3 "Reserved" ;
VAL_ 148 VFC_LKAStatus 0 "off" 1 "Standby" 2 "Active" 3 "Failure" ;
VAL_ 145 Selflearning_status 3 "reserved" 2 "completed" 1 "learning" 0 "init" ;
VAL_ 145 VFC_DriverWindowControl 102 "Reserved" 1 "0%~100%" 0 "no request" ;
VAL_ 145 VFC_LLaneDistanceFusion 121 "reserved" 0 "-1-5" ;
VAL_ 145 VFC_SunroofControl 205 "Reserved" 203 "Sunshade0%~100%" 1 "SunRoof0%~100%" 255 "Reserved" 254 "Initialize" 204 "stop" 102 "tilt" 0 "inactive" ;
VAL_ 145 VFC_RLaneDistanceFusion 1 "Reserved" 0 "-1-5" ;
VAL_ 146 VFC_EmergencyLightingRequest 3 "OFF" 2 "Level2" 1 "Level1" 0 "no request" ;
VAL_ 146 VFC_ELKActiveSide 3 "RESERVED" 2 "SIDE_RI" 1 "SIDE_LE" 0 "SIDE_UNDEF" ;
VAL_ 146 VFC_LASModeSelectionStatus 0 "Reserved" 1 "LDW" 2 "LKA" 3 "LCS" 4 "Reserved" 7 "OFF" ;
VAL_ 146 VFC_LatTakeoverReq 0 "no request" 1 "level 1 request" 2 "level 2 request" 3 "reserved" ;
VAL_ 146 VFC_HandsOnReq 7 "reserved" 6 "reserved" 0 "no request" 1 "level 1 request" 2 "level 2 request" 3 "level 3 request" 4 "level 4 request" 5 "reserved" ;
VAL_ 146 VFC_RLaneMarkerType 0 "Dashed" 1 "solid" 2 "road edge" 3 "double lane mark" 4 "Botts' dots" 5 "other" 6 "fence" 7 "no display" ;
VAL_ 146 VFC_LaneChangeStatus 0 "no lane change " 1 "lane changing" 2 "end lane change" 3 "unknow" ;
VAL_ 146 VFC_RoadCurvatureFar 1 "Reserved" 0 "-0.03-0.03" ;
VAL_ 146 VFC_RRLaneDistance 61 "reserved" 0 "0-12" ;
VAL_ 146 VFC_IACCHWAMode 0 "off" 1 "standby" 2 "passive" 3 "active" 4 "suspend" 5 "prohibition" 6 "reserved" 7 "failure" ;
VAL_ 146 VFC_LASWarningModeSelectionSts 0 "Reserved" 1 "sound" 2 "vibration" 3 "sound and vibration" 4 "Reserved" ;
VAL_ 146 VFC_DriverHandsOffStatus 0 "hands off" 1 "hands on Level1" 2 "hands on Level2" 3 "unkown" ;
VAL_ 146 VFC_IACCHWATextInfoForDriver 24 "Reserved" 13 "prohibition request" 12 "system error" 11 "caturion about driving safty" 10 "driver overrides steering" 28 "reserved" 15 "Hands on plz" 23 "unable to active in Bad weather" 22 "other system error" 0 "no display" 1 "IACC cancel" 2 "IACC deativate" 3 "IACC unintended exit" 4 "unable to activate IACC" 5 "lane condition not avaliable" 6 "ADR/DVR Status not Match" 7 "longitudinal control not avaliable" 8 "IACC not available by EPS" 9 "exceed speed limit" 14 "turn light switch on" 16 "Please turn on IACC in incall" 17 "unable to active in curve" 18 "unable to active for not in lane/crossing lane" 19 "Longitude Exit" 20 "takeover request with safety stoping" 21 "takeover request with safety stop completed" 27 "Driver Drowsy or Distracted" ;
VAL_ 146 VFC_LDWShakeLevStatus 0 "reserved" 1 "low" 2 "normal" 3 "high" ;
VAL_ 146 VFC_IACCHWAEnable 0 "OFF" 1 "on" ;
VAL_ 146 VFC_HostLaneLeftStatus 0 "no display" 1 "Tracking" 2 "Intervention" 3 "Warning" 4 "Centering" 5 "Crossing" 6 "UDLC Request Active" 7 "reserved" 8 "UDLC  not  Active by obj" 9 "reserved" ;
VAL_ 146 VFC_ELKInterventionMode 0 "off" 1 "Road edge" 2 "Overtaking" 3 "Oncoming" ;
VAL_ 146 VFC_ELKMode 7 "reserved" 6 "reserved" 5 "reserved" 0 "off" 1 "passive" 2 "active" 3 "fault" 4 "reserved" ;
VAL_ 146 VFC_HostLaneRightStatus 0 "no display" 1 "Tracking" 2 "Intervention" 3 "Warning" 4 "Centering" 5 "Crossing" 6 "UDLC Request Active" 7 "reserved" 8 "UDLC  not  Active by obj" 9 "reserved" ;
VAL_ 146 VFC_TargetBasedLateralControl 0 "no lateral control" 1 "around Based" 2 "lane based" 3 "target based" ;
VAL_ 146 VFC_HandsoffFuncStatus 0 "off" 1 "passive" 2 "standby" 3 "wariming" 4 "total hansoff mode" 5 "handsoff with limit" 6 "reserved" 7 "faulure" ;
VAL_ 146 VFC_HandsoffFuncTextinfo 0 "no display" 1 "total handsoff mode" 2 "out of handsoff mode by out ODD" 3 "out of handsoff mode by Drowsiness" 4 "out of handsoff mode by Distraction" 5 "out of handsoffmode-IMS Unavail" 6 "out of handsoffmode-NAV Unavail" 7 "our of handsoffmode-NoCurvature" 8 "out of handsoffmode-IACC Suspend" 9 "Reserved" ;
VAL_ 146 VFC_LLaneMarkerType 0 "Dashed" 1 "solid" 2 "road edge" 3 "double lane mark" 4 "Botts' dots" 5 "other" 6 "fence" 7 "no display" ;
VAL_ 146 VFC_ELKEnableStatus 0 "off" 1 "on" ;
VAL_ 146 VFC_LLLaneDistance 1 "Reserved" 0 "0-12" ;
VAL_ 146 VFC_RoadCurvature 1 "Reserved" 0 "-0.03-0.03" ;
VAL_ 146 VFC_LLLaneDetection 0 "not detected" 1 "detected" 2 "road edge" 3 "fence" ;
VAL_ 146 VFC_Voiceinfo 15 "Reserved" 0 "no voice" 1 "latentWarning voive" 2 "FCWAEB voice" 3 "ACC object detect voice" 4 "ACC object disappeared voice" 5 "ACC/IACC takeover request voice" 6 "Lane Left dangerous warning  voice" 7 "Lane Right dangerous warning  voice" 8 "reserved" 9 "IACC Active voice" 10 "IACC exit voice" 11 "reserved" 12 "reserved" 13 "cruise unintended exit" 14 "TrafficWarning" ;
VAL_ 146 VFC_RRLaneDetection 0 "not detected" 1 "detected" 2 "road edge" 3 "fence" ;
VAL_ 146 VFC_RoadCurvatureNear 1 "Reserved" 0 "-0.03-0.03" ;
VAL_ 147 VFC_LaneEquationStatus 3 "reserved" 2 "right lane" 1 "left lane" 0 "no display" ;
VAL_ 930 LAS_OverspeedWarningOffset 31 "Invalid" 21 "Reserved" 0 "Reserved" ;
VAL_ 930 VFC_ADAS_ModSts_SLA 0 "Unknown" 1 "Off" 2 "Fusion mode" 3 "Vision mode" 4 "Navigation only mode" 5 "Defect" 6 "Reserved" 7 "Reserved" ;
VAL_ 930 VFC_ADAS_SpdLim_SLA 0 "No Display" 1 "SPL Cancelled" 2 "SPL 5" 3 "SPL 10" 4 "SPL 15" 5 "SPL 20" 6 "SPL 25" 7 "SPL 30" 8 "SPL 35" 9 "SPL 40" 10 "SPL 45" 11 "SPL 50" 12 "SPL 55" 13 "SPL 60" 14 "SPL 65" 15 "SPL 70" 16 "SPL 75" 17 "SPL 80" 18 "SPL 85" 19 "SPL 90" 20 "SPL 95" 21 "SPL 100" 22 "SPL 105" 23 "SPL 110" 24 "SPL 115" 25 "SPL 120" 26 "SPL 125" 27 "SPL 130" 28 "Reserved" 29 "0x1C(28)-FF(255): Reserved." 255 "0x1C(28)-FF(255): Reserved." ;
VAL_ 930 VFC_ADAS_SpdLimUnit_SLA 0 "Unknown" 1 "KPH" 2 "MPH" 3 "Reserved" ;
